VERSION ""

NS_ :

BS_:

BU_: HVESP01 HVESS

BO_ 2499744364 HVESP01_DiagnosticC_8: 8 HVESP01
 SG_ HVESP01_PackVoltageImbalance_8 : 58|2@1+ (1,0) [0|3] ""  HVESP01
 SG_ HVESP01_PrechargeoverCurrent_8 : 56|2@1+ (1,0) [0|3] ""  HVESP01
 SG_ HVESP01_HVILvoltageError_8 : 2|2@1+ (1,0) [0|3] ""  HVESP01
 SG_ HVESP01_HVILcurrentReturnError_8 : 0|2@1+ (1,0) [0|3] ""  HVESP01
 SG_ HVESP01_PosFcContWelded_8 : 14|2@1+ (1,0) [0|3] ""  HVESP01
 SG_ HVESP01_PosFcContStuckOpen_8 : 12|2@1+ (1,0) [0|3] ""  HVESP01
 SG_ HVESP01_NegFcContWelded_8 : 10|2@1+ (1,0) [0|3] ""  HVESP01
 SG_ HVESP01_NegFcContStuckOpen_8 : 8|2@1+ (1,0) [0|3] ""  HVESP01
 SG_ HVESP01_IsolationIntFault_8 : 20|2@1+ (1,0) [0|3] ""  HVESP01
 SG_ HVESP01_IsolationExtFault_8 : 18|2@1+ (1,0) [0|3] ""  HVESP01
 SG_ HVESP01_pcb_error_8 : 16|2@1+ (1,0) [0|3] ""  HVESP01
 SG_ HVESP01_hall_eff_hi_rang_err_8 : 30|2@1+ (1,0) [0|3] ""  HVESP01
 SG_ HVESP01_brick_volt_sns_open_8 : 28|2@1+ (1,0) [0|3] ""  HVESP01
 SG_ HVESP01_5v_error_8 : 26|2@1+ (1,0) [0|3] ""  HVESP01
 SG_ HVESP01_3_3_hot_error_8 : 24|2@1+ (1,0) [0|3] ""  HVESP01
 SG_ HVESP01_12v_input_error_8 : 38|2@1+ (1,0) [0|3] ""  HVESP01
 SG_ HVESP01_1_25v_error_8 : 36|2@1+ (1,0) [0|3] ""  HVESP01
 SG_ HVESP01_shunt_MIA_8 : 34|2@1+ (1,0) [0|3] ""  HVESP01
 SG_ HVESP01_SBC_int_reg_error_8 : 32|2@1+ (1,0) [0|3] ""  HVESP01
 SG_ HVESP01_pos_3_3v_analog_error_8 : 46|2@1+ (1,0) [0|3] ""  HVESP01
 SG_ HVESP01_outlt_clnt_thrm_open_8 : 44|2@1+ (1,0) [0|3] ""  HVESP01
 SG_ HVESP01_neg_3_3_analog_error_8 : 42|2@1+ (1,0) [0|3] ""  HVESP01
 SG_ HVESP01_inlet_clnt_thrm_open_8 : 40|2@1+ (1,0) [0|3] ""  HVESP01
 SG_ HVESP01_hall_eff_lo_rang_err_8 : 54|2@1+ (1,0) [0|3] ""  HVESP01
 SG_ HVESP01_outlt_clnt_thrm_short_8 : 52|2@1+ (1,0) [0|3] ""  HVESP01
 SG_ HVESP01_inlet_clnt_thrm_short_8 : 50|2@1+ (1,0) [0|3] ""  HVESP01
 SG_ HVESP01_3_3v_error_8 : 48|2@1+ (1,0) [0|3] ""  HVESP01

BO_ 2499744613 HVESP01_DiagnosticD_1: 8 HVESP01
 SG_ HVESP01_BusJoinFailed_1 : 10|2@1+ (1,0) [0|3] ""  HVESP01
 SG_ HVESP01_ModuleThermFaultSevere_1 : 8|2@1+ (1,0) [0|3] ""  HVESP01
 SG_ HVESP01_Cal2PackMismatch_1 : 22|2@1+ (1,0) [0|3] ""  HVESP01
 SG_ HVESP01_HardwareUvloError_1 : 20|2@1+ (1,0) [0|3] ""  HVESP01
 SG_ HVESP01_iOverchargemod_1 : 46|2@1+ (1,0) [0|3] ""  HVESP01
 SG_ HVESP01_afe_pwr_wire_open_1 : 44|2@1+ (1,0) [0|3] ""  HVESP01
 SG_ HVESP01_HardwareOVError_1 : 18|2@1+ (1,0) [0|3] ""  HVESP01
 SG_ HVESP01_DoubleDcContWeld_1 : 16|2@1+ (1,0) [0|3] ""  HVESP01
 SG_ HVESP01_CurrentMismatch_1 : 30|2@1+ (1,0) [0|3] ""  HVESP01
 SG_ HVESP01_vBrickImbalanceWar_1 : 28|2@1+ (1,0) [0|3] ""  HVESP01
 SG_ HVESP01_vBrickImbalanceMod_1 : 26|2@1+ (1,0) [0|3] ""  HVESP01
 SG_ HVESP01_vBrickImbalanceSev_1 : 24|2@1+ (1,0) [0|3] ""  HVESP01
 SG_ HVESP01_Placeholder06_1 : 38|2@1+ (1,0) [0|3] ""  HVESP01
 SG_ HVESP01_iOverdischargewar_1 : 36|2@1+ (1,0) [0|3] ""  HVESP01
 SG_ HVESP01_SpeakerMia_1 : 2|2@1+ (1,0) [0|3] ""  HVESP01
 SG_ HVESP01_IsoSpiBreak_1 : 0|2@1+ (1,0) [0|3] ""  HVESP01
 SG_ HVESP01_VersionMismatch_1 : 14|2@1+ (1,0) [0|3] ""  HVESP01
 SG_ HVESP01_SystemPrechargeFail_1 : 12|2@1+ (1,0) [0|3] ""  HVESP01
 SG_ HVESP01_iOverdischargemod_1 : 34|2@1+ (1,0) [0|3] ""  HVESP01
 SG_ HVESP01_iOverchargewar_1 : 32|2@1+ (1,0) [0|3] ""  HVESP01

BO_ 2499744614 HVESP01_DiagnosticD_2: 8 HVESP01
 SG_ HVESP01_BusJoinFailed_2 : 10|2@1+ (1,0) [0|3] ""  HVESP01
 SG_ HVESP01_ModuleThermFaultSevere_2 : 8|2@1+ (1,0) [0|3] ""  HVESP01
 SG_ HVESP01_Cal2PackMismatch_2 : 22|2@1+ (1,0) [0|3] ""  HVESP01
 SG_ HVESP01_HardwareUvloError_2 : 20|2@1+ (1,0) [0|3] ""  HVESP01
 SG_ HVESP01_iOverchargemod_2 : 46|2@1+ (1,0) [0|3] ""  HVESP01
 SG_ HVESP01_afe_pwr_wire_open_2 : 44|2@1+ (1,0) [0|3] ""  HVESP01
 SG_ HVESP01_HardwareOVError_2 : 18|2@1+ (1,0) [0|3] ""  HVESP01
 SG_ HVESP01_DoubleDcContWeld_2 : 16|2@1+ (1,0) [0|3] ""  HVESP01
 SG_ HVESP01_CurrentMismatch_2 : 30|2@1+ (1,0) [0|3] ""  HVESP01
 SG_ HVESP01_vBrickImbalanceWar_2 : 28|2@1+ (1,0) [0|3] ""  HVESP01
 SG_ HVESP01_vBrickImbalanceMod_2 : 26|2@1+ (1,0) [0|3] ""  HVESP01
 SG_ HVESP01_vBrickImbalanceSev_2 : 24|2@1+ (1,0) [0|3] ""  HVESP01
 SG_ HVESP01_Placeholder06_2 : 38|2@1+ (1,0) [0|3] ""  HVESP01
 SG_ HVESP01_iOverdischargewar_2 : 36|2@1+ (1,0) [0|3] ""  HVESP01
 SG_ HVESP01_SpeakerMia_2 : 2|2@1+ (1,0) [0|3] ""  HVESP01
 SG_ HVESP01_IsoSpiBreak_2 : 0|2@1+ (1,0) [0|3] ""  HVESP01
 SG_ HVESP01_VersionMismatch_2 : 14|2@1+ (1,0) [0|3] ""  HVESP01
 SG_ HVESP01_SystemPrechargeFail_2 : 12|2@1+ (1,0) [0|3] ""  HVESP01
 SG_ HVESP01_iOverdischargemod_2 : 34|2@1+ (1,0) [0|3] ""  HVESP01
 SG_ HVESP01_iOverchargewar_2 : 32|2@1+ (1,0) [0|3] ""  HVESP01

BO_ 2499744615 HVESP01_DiagnosticD_3: 8 HVESP01
 SG_ HVESP01_BusJoinFailed_3 : 10|2@1+ (1,0) [0|3] ""  HVESP01
 SG_ HVESP01_ModuleThermFaultSevere_3 : 8|2@1+ (1,0) [0|3] ""  HVESP01
 SG_ HVESP01_Cal2PackMismatch_3 : 22|2@1+ (1,0) [0|3] ""  HVESP01
 SG_ HVESP01_HardwareUvloError_3 : 20|2@1+ (1,0) [0|3] ""  HVESP01
 SG_ HVESP01_iOverchargemod_3 : 46|2@1+ (1,0) [0|3] ""  HVESP01
 SG_ HVESP01_afe_pwr_wire_open_3 : 44|2@1+ (1,0) [0|3] ""  HVESP01
 SG_ HVESP01_HardwareOVError_3 : 18|2@1+ (1,0) [0|3] ""  HVESP01
 SG_ HVESP01_DoubleDcContWeld_3 : 16|2@1+ (1,0) [0|3] ""  HVESP01
 SG_ HVESP01_CurrentMismatch_3 : 30|2@1+ (1,0) [0|3] ""  HVESP01
 SG_ HVESP01_vBrickImbalanceWar_3 : 28|2@1+ (1,0) [0|3] ""  HVESP01
 SG_ HVESP01_vBrickImbalanceMod_3 : 26|2@1+ (1,0) [0|3] ""  HVESP01
 SG_ HVESP01_vBrickImbalanceSev_3 : 24|2@1+ (1,0) [0|3] ""  HVESP01
 SG_ HVESP01_Placeholder06_3 : 38|2@1+ (1,0) [0|3] ""  HVESP01
 SG_ HVESP01_iOverdischargewar_3 : 36|2@1+ (1,0) [0|3] ""  HVESP01
 SG_ HVESP01_SpeakerMia_3 : 2|2@1+ (1,0) [0|3] ""  HVESP01
 SG_ HVESP01_IsoSpiBreak_3 : 0|2@1+ (1,0) [0|3] ""  HVESP01
 SG_ HVESP01_VersionMismatch_3 : 14|2@1+ (1,0) [0|3] ""  HVESP01
 SG_ HVESP01_SystemPrechargeFail_3 : 12|2@1+ (1,0) [0|3] ""  HVESP01
 SG_ HVESP01_iOverdischargemod_3 : 34|2@1+ (1,0) [0|3] ""  HVESP01
 SG_ HVESP01_iOverchargewar_3 : 32|2@1+ (1,0) [0|3] ""  HVESP01

BO_ 2499744616 HVESP01_DiagnosticD_4: 8 HVESP01
 SG_ HVESP01_BusJoinFailed_4 : 10|2@1+ (1,0) [0|3] ""  HVESP01
 SG_ HVESP01_ModuleThermFaultSevere_4 : 8|2@1+ (1,0) [0|3] ""  HVESP01
 SG_ HVESP01_Cal2PackMismatch_4 : 22|2@1+ (1,0) [0|3] ""  HVESP01
 SG_ HVESP01_HardwareUvloError_4 : 20|2@1+ (1,0) [0|3] ""  HVESP01
 SG_ HVESP01_iOverchargemod_4 : 46|2@1+ (1,0) [0|3] ""  HVESP01
 SG_ HVESP01_afe_pwr_wire_open_4 : 44|2@1+ (1,0) [0|3] ""  HVESP01
 SG_ HVESP01_HardwareOVError_4 : 18|2@1+ (1,0) [0|3] ""  HVESP01
 SG_ HVESP01_DoubleDcContWeld_4 : 16|2@1+ (1,0) [0|3] ""  HVESP01
 SG_ HVESP01_CurrentMismatch_4 : 30|2@1+ (1,0) [0|3] ""  HVESP01
 SG_ HVESP01_vBrickImbalanceWar_4 : 28|2@1+ (1,0) [0|3] ""  HVESP01
 SG_ HVESP01_vBrickImbalanceMod_4 : 26|2@1+ (1,0) [0|3] ""  HVESP01
 SG_ HVESP01_vBrickImbalanceSev_4 : 24|2@1+ (1,0) [0|3] ""  HVESP01
 SG_ HVESP01_Placeholder06_4 : 38|2@1+ (1,0) [0|3] ""  HVESP01
 SG_ HVESP01_iOverdischargewar_4 : 36|2@1+ (1,0) [0|3] ""  HVESP01
 SG_ HVESP01_SpeakerMia_4 : 2|2@1+ (1,0) [0|3] ""  HVESP01
 SG_ HVESP01_IsoSpiBreak_4 : 0|2@1+ (1,0) [0|3] ""  HVESP01
 SG_ HVESP01_VersionMismatch_4 : 14|2@1+ (1,0) [0|3] ""  HVESP01
 SG_ HVESP01_SystemPrechargeFail_4 : 12|2@1+ (1,0) [0|3] ""  HVESP01
 SG_ HVESP01_iOverdischargemod_4 : 34|2@1+ (1,0) [0|3] ""  HVESP01
 SG_ HVESP01_iOverchargewar_4 : 32|2@1+ (1,0) [0|3] ""  HVESP01

BO_ 2499744617 HVESP01_DiagnosticD_5: 8 HVESP01
 SG_ HVESP01_BusJoinFailed_5 : 10|2@1+ (1,0) [0|3] ""  HVESP01
 SG_ HVESP01_ModuleThermFaultSevere_5 : 8|2@1+ (1,0) [0|3] ""  HVESP01
 SG_ HVESP01_Cal2PackMismatch_5 : 22|2@1+ (1,0) [0|3] ""  HVESP01
 SG_ HVESP01_HardwareUvloError_5 : 20|2@1+ (1,0) [0|3] ""  HVESP01
 SG_ HVESP01_iOverchargemod_5 : 46|2@1+ (1,0) [0|3] ""  HVESP01
 SG_ HVESP01_afe_pwr_wire_open_5 : 44|2@1+ (1,0) [0|3] ""  HVESP01
 SG_ HVESP01_HardwareOVError_5 : 18|2@1+ (1,0) [0|3] ""  HVESP01
 SG_ HVESP01_DoubleDcContWeld_5 : 16|2@1+ (1,0) [0|3] ""  HVESP01
 SG_ HVESP01_CurrentMismatch_5 : 30|2@1+ (1,0) [0|3] ""  HVESP01
 SG_ HVESP01_vBrickImbalanceWar_5 : 28|2@1+ (1,0) [0|3] ""  HVESP01
 SG_ HVESP01_vBrickImbalanceMod_5 : 26|2@1+ (1,0) [0|3] ""  HVESP01
 SG_ HVESP01_vBrickImbalanceSev_5 : 24|2@1+ (1,0) [0|3] ""  HVESP01
 SG_ HVESP01_Placeholder06_5 : 38|2@1+ (1,0) [0|3] ""  HVESP01
 SG_ HVESP01_iOverdischargewar_5 : 36|2@1+ (1,0) [0|3] ""  HVESP01
 SG_ HVESP01_SpeakerMia_5 : 2|2@1+ (1,0) [0|3] ""  HVESP01
 SG_ HVESP01_IsoSpiBreak_5 : 0|2@1+ (1,0) [0|3] ""  HVESP01
 SG_ HVESP01_VersionMismatch_5 : 14|2@1+ (1,0) [0|3] ""  HVESP01
 SG_ HVESP01_SystemPrechargeFail_5 : 12|2@1+ (1,0) [0|3] ""  HVESP01
 SG_ HVESP01_iOverdischargemod_5 : 34|2@1+ (1,0) [0|3] ""  HVESP01
 SG_ HVESP01_iOverchargewar_5 : 32|2@1+ (1,0) [0|3] ""  HVESP01

BO_ 2499744618 HVESP01_DiagnosticD_6: 8 HVESP01
 SG_ HVESP01_BusJoinFailed_6 : 10|2@1+ (1,0) [0|3] ""  HVESP01
 SG_ HVESP01_ModuleThermFaultSevere_6 : 8|2@1+ (1,0) [0|3] ""  HVESP01
 SG_ HVESP01_Cal2PackMismatch_6 : 22|2@1+ (1,0) [0|3] ""  HVESP01
 SG_ HVESP01_HardwareUvloError_6 : 20|2@1+ (1,0) [0|3] ""  HVESP01
 SG_ HVESP01_iOverchargemod_6 : 46|2@1+ (1,0) [0|3] ""  HVESP01
 SG_ HVESP01_afe_pwr_wire_open_6 : 44|2@1+ (1,0) [0|3] ""  HVESP01
 SG_ HVESP01_HardwareOVError_6 : 18|2@1+ (1,0) [0|3] ""  HVESP01
 SG_ HVESP01_DoubleDcContWeld_6 : 16|2@1+ (1,0) [0|3] ""  HVESP01
 SG_ HVESP01_CurrentMismatch_6 : 30|2@1+ (1,0) [0|3] ""  HVESP01
 SG_ HVESP01_vBrickImbalanceWar_6 : 28|2@1+ (1,0) [0|3] ""  HVESP01
 SG_ HVESP01_vBrickImbalanceMod_6 : 26|2@1+ (1,0) [0|3] ""  HVESP01
 SG_ HVESP01_vBrickImbalanceSev_6 : 24|2@1+ (1,0) [0|3] ""  HVESP01
 SG_ HVESP01_Placeholder06_6 : 38|2@1+ (1,0) [0|3] ""  HVESP01
 SG_ HVESP01_iOverdischargewar_6 : 36|2@1+ (1,0) [0|3] ""  HVESP01
 SG_ HVESP01_SpeakerMia_6 : 2|2@1+ (1,0) [0|3] ""  HVESP01
 SG_ HVESP01_IsoSpiBreak_6 : 0|2@1+ (1,0) [0|3] ""  HVESP01
 SG_ HVESP01_VersionMismatch_6 : 14|2@1+ (1,0) [0|3] ""  HVESP01
 SG_ HVESP01_SystemPrechargeFail_6 : 12|2@1+ (1,0) [0|3] ""  HVESP01
 SG_ HVESP01_iOverdischargemod_6 : 34|2@1+ (1,0) [0|3] ""  HVESP01
 SG_ HVESP01_iOverchargewar_6 : 32|2@1+ (1,0) [0|3] ""  HVESP01

BO_ 2499744619 HVESP01_DiagnosticD_7: 8 HVESP01
 SG_ HVESP01_BusJoinFailed_7 : 10|2@1+ (1,0) [0|3] ""  HVESP01
 SG_ HVESP01_ModuleThermFaultSevere_7 : 8|2@1+ (1,0) [0|3] ""  HVESP01
 SG_ HVESP01_Cal2PackMismatch_7 : 22|2@1+ (1,0) [0|3] ""  HVESP01
 SG_ HVESP01_HardwareUvloError_7 : 20|2@1+ (1,0) [0|3] ""  HVESP01
 SG_ HVESP01_iOverchargemod_7 : 46|2@1+ (1,0) [0|3] ""  HVESP01
 SG_ HVESP01_afe_pwr_wire_open_7 : 44|2@1+ (1,0) [0|3] ""  HVESP01
 SG_ HVESP01_HardwareOVError_7 : 18|2@1+ (1,0) [0|3] ""  HVESP01
 SG_ HVESP01_DoubleDcContWeld_7 : 16|2@1+ (1,0) [0|3] ""  HVESP01
 SG_ HVESP01_CurrentMismatch_7 : 30|2@1+ (1,0) [0|3] ""  HVESP01
 SG_ HVESP01_vBrickImbalanceWar_7 : 28|2@1+ (1,0) [0|3] ""  HVESP01
 SG_ HVESP01_vBrickImbalanceMod_7 : 26|2@1+ (1,0) [0|3] ""  HVESP01
 SG_ HVESP01_vBrickImbalanceSev_7 : 24|2@1+ (1,0) [0|3] ""  HVESP01
 SG_ HVESP01_Placeholder06_7 : 38|2@1+ (1,0) [0|3] ""  HVESP01
 SG_ HVESP01_iOverdischargewar_7 : 36|2@1+ (1,0) [0|3] ""  HVESP01
 SG_ HVESP01_SpeakerMia_7 : 2|2@1+ (1,0) [0|3] ""  HVESP01
 SG_ HVESP01_IsoSpiBreak_7 : 0|2@1+ (1,0) [0|3] ""  HVESP01
 SG_ HVESP01_VersionMismatch_7 : 14|2@1+ (1,0) [0|3] ""  HVESP01
 SG_ HVESP01_SystemPrechargeFail_7 : 12|2@1+ (1,0) [0|3] ""  HVESP01
 SG_ HVESP01_iOverdischargemod_7 : 34|2@1+ (1,0) [0|3] ""  HVESP01
 SG_ HVESP01_iOverchargewar_7 : 32|2@1+ (1,0) [0|3] ""  HVESP01

BO_ 2499744620 HVESP01_DiagnosticD_8: 8 HVESP01
 SG_ HVESP01_BusJoinFailed_8 : 10|2@1+ (1,0) [0|3] ""  HVESP01
 SG_ HVESP01_ModuleThermFaultSevere_8 : 8|2@1+ (1,0) [0|3] ""  HVESP01
 SG_ HVESP01_Cal2PackMismatch_8 : 22|2@1+ (1,0) [0|3] ""  HVESP01
 SG_ HVESP01_HardwareUvloError_8 : 20|2@1+ (1,0) [0|3] ""  HVESP01
 SG_ HVESP01_iOverchargemod_8 : 46|2@1+ (1,0) [0|3] ""  HVESP01
 SG_ HVESP01_afe_pwr_wire_open_8 : 44|2@1+ (1,0) [0|3] ""  HVESP01
 SG_ HVESP01_HardwareOVError_8 : 18|2@1+ (1,0) [0|3] ""  HVESP01
 SG_ HVESP01_DoubleDcContWeld_8 : 16|2@1+ (1,0) [0|3] ""  HVESP01
 SG_ HVESP01_CurrentMismatch_8 : 30|2@1+ (1,0) [0|3] ""  HVESP01
 SG_ HVESP01_vBrickImbalanceWar_8 : 28|2@1+ (1,0) [0|3] ""  HVESP01
 SG_ HVESP01_vBrickImbalanceMod_8 : 26|2@1+ (1,0) [0|3] ""  HVESP01
 SG_ HVESP01_vBrickImbalanceSev_8 : 24|2@1+ (1,0) [0|3] ""  HVESP01
 SG_ HVESP01_Placeholder06_8 : 38|2@1+ (1,0) [0|3] ""  HVESP01
 SG_ HVESP01_iOverdischargewar_8 : 36|2@1+ (1,0) [0|3] ""  HVESP01
 SG_ HVESP01_SpeakerMia_8 : 2|2@1+ (1,0) [0|3] ""  HVESP01
 SG_ HVESP01_IsoSpiBreak_8 : 0|2@1+ (1,0) [0|3] ""  HVESP01
 SG_ HVESP01_VersionMismatch_8 : 14|2@1+ (1,0) [0|3] ""  HVESP01
 SG_ HVESP01_SystemPrechargeFail_8 : 12|2@1+ (1,0) [0|3] ""  HVESP01
 SG_ HVESP01_iOverdischargemod_8 : 34|2@1+ (1,0) [0|3] ""  HVESP01
 SG_ HVESP01_iOverchargewar_8 : 32|2@1+ (1,0) [0|3] ""  HVESP01

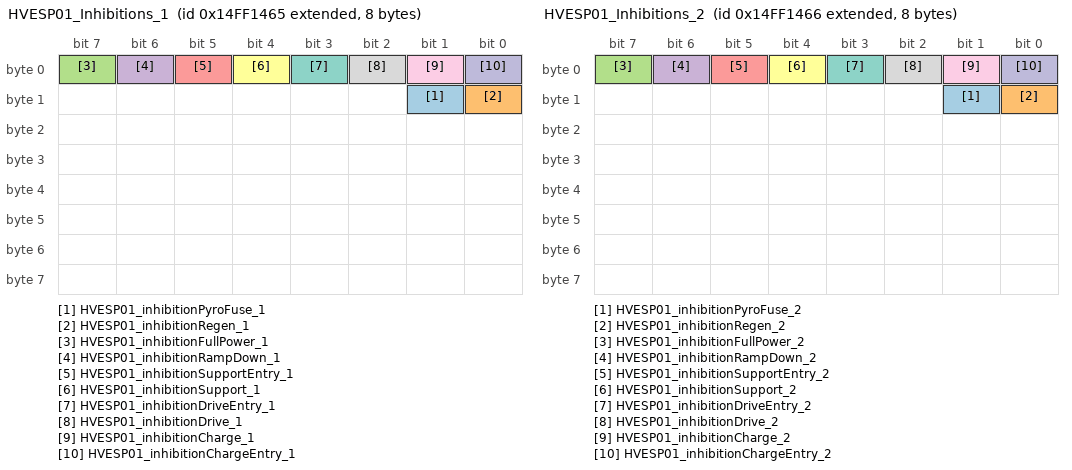
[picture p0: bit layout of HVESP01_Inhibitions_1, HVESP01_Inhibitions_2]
BO_ 2499744869 HVESP01_Inhibitions_1: 8 HVESP01
 SG_ HVESP01_inhibitionPyroFuse_1 : 9|1@1+ (1,0) [0|1] ""  HVESP01
 SG_ HVESP01_inhibitionRegen_1 : 8|1@1+ (1,0) [0|1] ""  HVESP01
 SG_ HVESP01_inhibitionFullPower_1 : 7|1@1+ (1,0) [0|1] ""  HVESP01
 SG_ HVESP01_inhibitionRampDown_1 : 6|1@1+ (1,0) [0|1] ""  HVESP01
 SG_ HVESP01_inhibitionSupportEntry_1 : 5|1@1+ (1,0) [0|1] ""  HVESP01
 SG_ HVESP01_inhibitionSupport_1 : 4|1@1+ (1,0) [0|1] ""  HVESP01
 SG_ HVESP01_inhibitionDriveEntry_1 : 3|1@1+ (1,0) [0|1] ""  HVESP01
 SG_ HVESP01_inhibitionDrive_1 : 2|1@1+ (1,0) [0|1] ""  HVESP01
 SG_ HVESP01_inhibitionCharge_1 : 1|1@1+ (1,0) [0|1] ""  HVESP01
 SG_ HVESP01_inhibitionChargeEntry_1 : 0|1@1+ (1,0) [0|1] ""  HVESP01

BO_ 2499744870 HVESP01_Inhibitions_2: 8 HVESP01
 SG_ HVESP01_inhibitionPyroFuse_2 : 9|1@1+ (1,0) [0|1] ""  HVESP01
 SG_ HVESP01_inhibitionRegen_2 : 8|1@1+ (1,0) [0|1] ""  HVESP01
 SG_ HVESP01_inhibitionFullPower_2 : 7|1@1+ (1,0) [0|1] ""  HVESP01
 SG_ HVESP01_inhibitionRampDown_2 : 6|1@1+ (1,0) [0|1] ""  HVESP01
 SG_ HVESP01_inhibitionSupportEntry_2 : 5|1@1+ (1,0) [0|1] ""  HVESP01
 SG_ HVESP01_inhibitionSupport_2 : 4|1@1+ (1,0) [0|1] ""  HVESP01
 SG_ HVESP01_inhibitionDriveEntry_2 : 3|1@1+ (1,0) [0|1] ""  HVESP01
 SG_ HVESP01_inhibitionDrive_2 : 2|1@1+ (1,0) [0|1] ""  HVESP01
 SG_ HVESP01_inhibitionCharge_2 : 1|1@1+ (1,0) [0|1] ""  HVESP01
 SG_ HVESP01_inhibitionChargeEntry_2 : 0|1@1+ (1,0) [0|1] ""  HVESP01

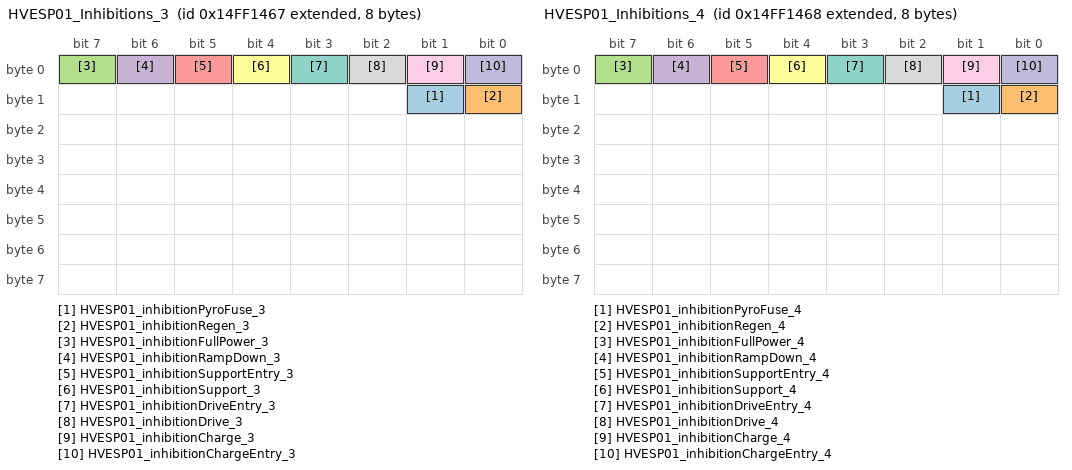
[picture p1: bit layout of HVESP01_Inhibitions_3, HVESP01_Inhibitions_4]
BO_ 2499744871 HVESP01_Inhibitions_3: 8 HVESP01
 SG_ HVESP01_inhibitionPyroFuse_3 : 9|1@1+ (1,0) [0|1] ""  HVESP01
 SG_ HVESP01_inhibitionRegen_3 : 8|1@1+ (1,0) [0|1] ""  HVESP01
 SG_ HVESP01_inhibitionFullPower_3 : 7|1@1+ (1,0) [0|1] ""  HVESP01
 SG_ HVESP01_inhibitionRampDown_3 : 6|1@1+ (1,0) [0|1] ""  HVESP01
 SG_ HVESP01_inhibitionSupportEntry_3 : 5|1@1+ (1,0) [0|1] ""  HVESP01
 SG_ HVESP01_inhibitionSupport_3 : 4|1@1+ (1,0) [0|1] ""  HVESP01
 SG_ HVESP01_inhibitionDriveEntry_3 : 3|1@1+ (1,0) [0|1] ""  HVESP01
 SG_ HVESP01_inhibitionDrive_3 : 2|1@1+ (1,0) [0|1] ""  HVESP01
 SG_ HVESP01_inhibitionCharge_3 : 1|1@1+ (1,0) [0|1] ""  HVESP01
 SG_ HVESP01_inhibitionChargeEntry_3 : 0|1@1+ (1,0) [0|1] ""  HVESP01

BO_ 2499744872 HVESP01_Inhibitions_4: 8 HVESP01
 SG_ HVESP01_inhibitionPyroFuse_4 : 9|1@1+ (1,0) [0|1] ""  HVESP01
 SG_ HVESP01_inhibitionRegen_4 : 8|1@1+ (1,0) [0|1] ""  HVESP01
 SG_ HVESP01_inhibitionFullPower_4 : 7|1@1+ (1,0) [0|1] ""  HVESP01
 SG_ HVESP01_inhibitionRampDown_4 : 6|1@1+ (1,0) [0|1] ""  HVESP01
 SG_ HVESP01_inhibitionSupportEntry_4 : 5|1@1+ (1,0) [0|1] ""  HVESP01
 SG_ HVESP01_inhibitionSupport_4 : 4|1@1+ (1,0) [0|1] ""  HVESP01
 SG_ HVESP01_inhibitionDriveEntry_4 : 3|1@1+ (1,0) [0|1] ""  HVESP01
 SG_ HVESP01_inhibitionDrive_4 : 2|1@1+ (1,0) [0|1] ""  HVESP01
 SG_ HVESP01_inhibitionCharge_4 : 1|1@1+ (1,0) [0|1] ""  HVESP01
 SG_ HVESP01_inhibitionChargeEntry_4 : 0|1@1+ (1,0) [0|1] ""  HVESP01

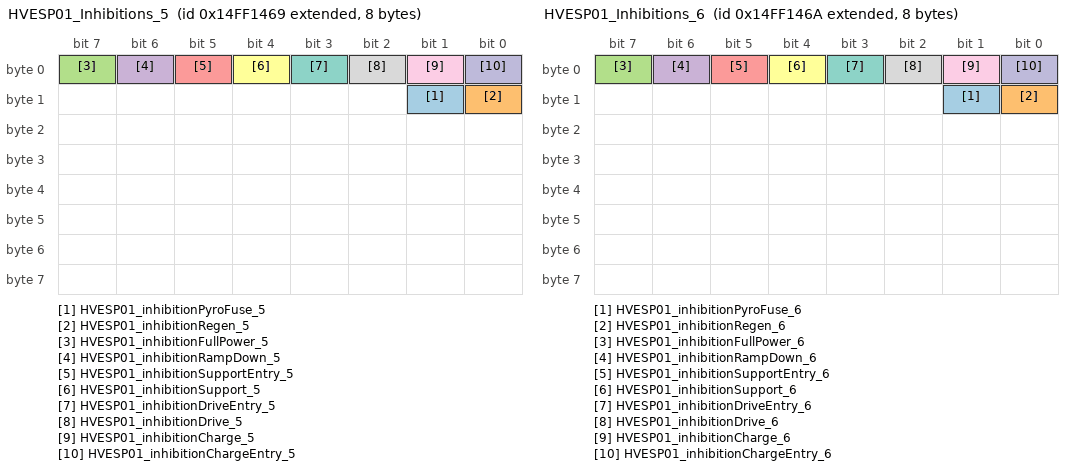
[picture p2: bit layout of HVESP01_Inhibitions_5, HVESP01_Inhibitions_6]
BO_ 2499744873 HVESP01_Inhibitions_5: 8 HVESP01
 SG_ HVESP01_inhibitionPyroFuse_5 : 9|1@1+ (1,0) [0|1] ""  HVESP01
 SG_ HVESP01_inhibitionRegen_5 : 8|1@1+ (1,0) [0|1] ""  HVESP01
 SG_ HVESP01_inhibitionFullPower_5 : 7|1@1+ (1,0) [0|1] ""  HVESP01
 SG_ HVESP01_inhibitionRampDown_5 : 6|1@1+ (1,0) [0|1] ""  HVESP01
 SG_ HVESP01_inhibitionSupportEntry_5 : 5|1@1+ (1,0) [0|1] ""  HVESP01
 SG_ HVESP01_inhibitionSupport_5 : 4|1@1+ (1,0) [0|1] ""  HVESP01
 SG_ HVESP01_inhibitionDriveEntry_5 : 3|1@1+ (1,0) [0|1] ""  HVESP01
 SG_ HVESP01_inhibitionDrive_5 : 2|1@1+ (1,0) [0|1] ""  HVESP01
 SG_ HVESP01_inhibitionCharge_5 : 1|1@1+ (1,0) [0|1] ""  HVESP01
 SG_ HVESP01_inhibitionChargeEntry_5 : 0|1@1+ (1,0) [0|1] ""  HVESP01

BO_ 2499744874 HVESP01_Inhibitions_6: 8 HVESP01
 SG_ HVESP01_inhibitionPyroFuse_6 : 9|1@1+ (1,0) [0|1] ""  HVESP01
 SG_ HVESP01_inhibitionRegen_6 : 8|1@1+ (1,0) [0|1] ""  HVESP01
 SG_ HVESP01_inhibitionFullPower_6 : 7|1@1+ (1,0) [0|1] ""  HVESP01
 SG_ HVESP01_inhibitionRampDown_6 : 6|1@1+ (1,0) [0|1] ""  HVESP01
 SG_ HVESP01_inhibitionSupportEntry_6 : 5|1@1+ (1,0) [0|1] ""  HVESP01
 SG_ HVESP01_inhibitionSupport_6 : 4|1@1+ (1,0) [0|1] ""  HVESP01
 SG_ HVESP01_inhibitionDriveEntry_6 : 3|1@1+ (1,0) [0|1] ""  HVESP01
 SG_ HVESP01_inhibitionDrive_6 : 2|1@1+ (1,0) [0|1] ""  HVESP01
 SG_ HVESP01_inhibitionCharge_6 : 1|1@1+ (1,0) [0|1] ""  HVESP01
 SG_ HVESP01_inhibitionChargeEntry_6 : 0|1@1+ (1,0) [0|1] ""  HVESP01

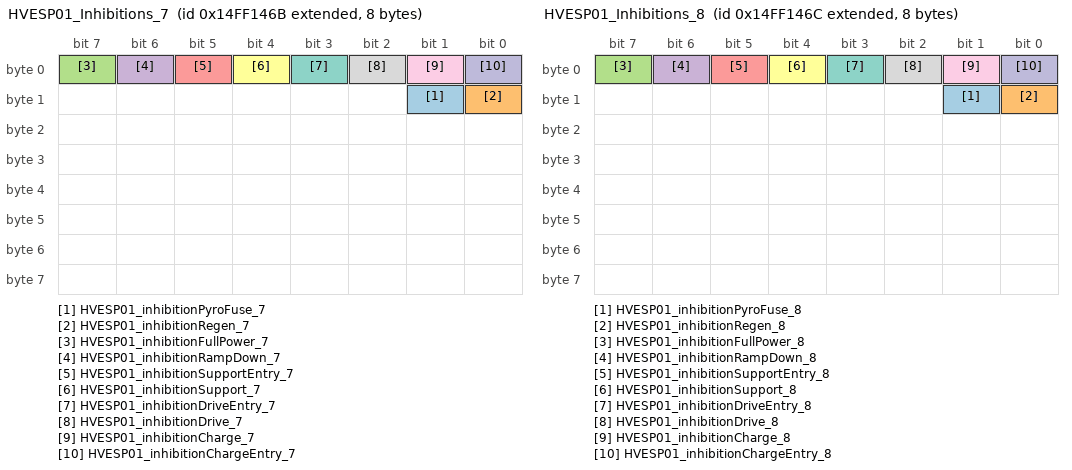
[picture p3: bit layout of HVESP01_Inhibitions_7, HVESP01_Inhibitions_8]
BO_ 2499744875 HVESP01_Inhibitions_7: 8 HVESP01
 SG_ HVESP01_inhibitionPyroFuse_7 : 9|1@1+ (1,0) [0|1] ""  HVESP01
 SG_ HVESP01_inhibitionRegen_7 : 8|1@1+ (1,0) [0|1] ""  HVESP01
 SG_ HVESP01_inhibitionFullPower_7 : 7|1@1+ (1,0) [0|1] ""  HVESP01
 SG_ HVESP01_inhibitionRampDown_7 : 6|1@1+ (1,0) [0|1] ""  HVESP01
 SG_ HVESP01_inhibitionSupportEntry_7 : 5|1@1+ (1,0) [0|1] ""  HVESP01
 SG_ HVESP01_inhibitionSupport_7 : 4|1@1+ (1,0) [0|1] ""  HVESP01
 SG_ HVESP01_inhibitionDriveEntry_7 : 3|1@1+ (1,0) [0|1] ""  HVESP01
 SG_ HVESP01_inhibitionDrive_7 : 2|1@1+ (1,0) [0|1] ""  HVESP01
 SG_ HVESP01_inhibitionCharge_7 : 1|1@1+ (1,0) [0|1] ""  HVESP01
 SG_ HVESP01_inhibitionChargeEntry_7 : 0|1@1+ (1,0) [0|1] ""  HVESP01

BO_ 2499744876 HVESP01_Inhibitions_8: 8 HVESP01
 SG_ HVESP01_inhibitionPyroFuse_8 : 9|1@1+ (1,0) [0|1] ""  HVESP01
 SG_ HVESP01_inhibitionRegen_8 : 8|1@1+ (1,0) [0|1] ""  HVESP01
 SG_ HVESP01_inhibitionFullPower_8 : 7|1@1+ (1,0) [0|1] ""  HVESP01
 SG_ HVESP01_inhibitionRampDown_8 : 6|1@1+ (1,0) [0|1] ""  HVESP01
 SG_ HVESP01_inhibitionSupportEntry_8 : 5|1@1+ (1,0) [0|1] ""  HVESP01
 SG_ HVESP01_inhibitionSupport_8 : 4|1@1+ (1,0) [0|1] ""  HVESP01
 SG_ HVESP01_inhibitionDriveEntry_8 : 3|1@1+ (1,0) [0|1] ""  HVESP01
 SG_ HVESP01_inhibitionDrive_8 : 2|1@1+ (1,0) [0|1] ""  HVESP01
 SG_ HVESP01_inhibitionCharge_8 : 1|1@1+ (1,0) [0|1] ""  HVESP01
 SG_ HVESP01_inhibitionChargeEntry_8 : 0|1@1+ (1,0) [0|1] ""  HVESP01

BO_ 2499745125 HVESP01_DiagnosticPrevA_1: 8 HVESP01
 SG_ HVESP01_vBrickOverSev_1 : 2|2@1+ (1,0) [0|3] ""  HVESP01
 SG_ HVESP01_vBrickOverMod_1 : 0|2@1+ (1,0) [0|3] ""  HVESP01
 SG_ HVESP01_vBrickOverWar_1 : 14|2@1+ (1,0) [0|3] ""  HVESP01
 SG_ HVESP01_HVESP01Quiet_1 : 12|2@1+ (1,0) [0|3] ""  HVESP01
 SG_ HVESP01_vBrickUnderMod_1 : 10|2@1+ (1,0) [0|3] ""  HVESP01
 SG_ HVESP01_vBrickUnderWar_1 : 8|2@1+ (1,0) [0|3] ""  HVESP01
 SG_ HVESP01_TempModuleOverSev_1 : 22|2@1+ (1,0) [0|3] ""  HVESP01
 SG_ HVESP01_TempModuleOverMod_1 : 20|2@1+ (1,0) [0|3] ""  HVESP01
 SG_ HVESP01_TempModuleOverWar_1 : 18|2@1+ (1,0) [0|3] ""  HVESP01
 SG_ HVESP01_TempModuleUnderSev_1 : 16|2@1+ (1,0) [0|3] ""  HVESP01
 SG_ HVESP01_TempModuleUnderMod_1 : 30|2@1+ (1,0) [0|3] ""  HVESP01
 SG_ HVESP01_TempModuleUnderWar_1 : 28|2@1+ (1,0) [0|3] ""  HVESP01
 SG_ HVESP01_iOverchargesev_1 : 26|2@1+ (1,0) [0|3] ""  HVESP01
 SG_ HVESP01_iOverdischargesev_1 : 24|2@1+ (1,0) [0|3] ""  HVESP01
 SG_ HVESP01_iOverHardware_1 : 38|2@1+ (1,0) [0|3] ""  HVESP01
 SG_ HVESP01_PosDcContStuckOpen_1 : 36|2@1+ (1,0) [0|3] ""  HVESP01
 SG_ HVESP01_PosDcContWelded_1 : 34|2@1+ (1,0) [0|3] ""  HVESP01
 SG_ HVESP01_NegDcContStuckOpen_1 : 32|2@1+ (1,0) [0|3] ""  HVESP01
 SG_ HVESP01_NegDcContWelded_1 : 46|2@1+ (1,0) [0|3] ""  HVESP01
 SG_ HVESP01_PrechgTooFast_1 : 44|2@1+ (1,0) [0|3] ""  HVESP01
 SG_ HVESP01_PrechgContWelded_1 : 42|2@1+ (1,0) [0|3] ""  HVESP01
 SG_ HVESP01_PrechgTimeout_1 : 40|2@1+ (1,0) [0|3] ""  HVESP01
 SG_ HVESP01_PrechgContStuckOpen_1 : 54|2@1+ (1,0) [0|3] ""  HVESP01
 SG_ HVESP01_ModuleImbalance_1 : 52|2@1+ (1,0) [0|3] ""  HVESP01
 SG_ HVESP01_ModuleMIA_1 : 50|2@1+ (1,0) [0|3] ""  HVESP01
 SG_ HVESP01_SensePackVoltError_1 : 48|2@1+ (1,0) [0|3] ""  HVESP01
 SG_ HVESP01_SenseLoadVoltError_1 : 62|2@1+ (1,0) [0|3] ""  HVESP01
 SG_ HVESP01_SenseShuntError_1 : 60|2@1+ (1,0) [0|3] ""  HVESP01
 SG_ HVESP01_SenseFcVoltErrorr_1 : 58|2@1+ (1,0) [0|3] ""  HVESP01
 SG_ HVESP01_Placeholder14_1 : 56|2@1+ (1,0) [0|3] ""  HVESP01

BO_ 2499745126 HVESP01_DiagnosticPrevA_2: 8 HVESP01
 SG_ HVESP01_vBrickOverSev_2 : 2|2@1+ (1,0) [0|3] ""  HVESP01
 SG_ HVESP01_vBrickOverMod_2 : 0|2@1+ (1,0) [0|3] ""  HVESP01
 SG_ HVESP01_vBrickOverWar_2 : 14|2@1+ (1,0) [0|3] ""  HVESP01
 SG_ HVESP01_HVESP01Quiet_2 : 12|2@1+ (1,0) [0|3] ""  HVESP01
 SG_ HVESP01_vBrickUnderMod_2 : 10|2@1+ (1,0) [0|3] ""  HVESP01
 SG_ HVESP01_vBrickUnderWar_2 : 8|2@1+ (1,0) [0|3] ""  HVESP01
 SG_ HVESP01_TempModuleOverSev_2 : 22|2@1+ (1,0) [0|3] ""  HVESP01
 SG_ HVESP01_TempModuleOverMod_2 : 20|2@1+ (1,0) [0|3] ""  HVESP01
 SG_ HVESP01_TempModuleOverWar_2 : 18|2@1+ (1,0) [0|3] ""  HVESP01
 SG_ HVESP01_TempModuleUnderSev_2 : 16|2@1+ (1,0) [0|3] ""  HVESP01
 SG_ HVESP01_TempModuleUnderMod_2 : 30|2@1+ (1,0) [0|3] ""  HVESP01
 SG_ HVESP01_TempModuleUnderWar_2 : 28|2@1+ (1,0) [0|3] ""  HVESP01
 SG_ HVESP01_iOverchargesev_2 : 26|2@1+ (1,0) [0|3] ""  HVESP01
 SG_ HVESP01_iOverdischargesev_2 : 24|2@1+ (1,0) [0|3] ""  HVESP01
 SG_ HVESP01_iOverHardware_2 : 38|2@1+ (1,0) [0|3] ""  HVESP01
 SG_ HVESP01_PosDcContStuckOpen_2 : 36|2@1+ (1,0) [0|3] ""  HVESP01
 SG_ HVESP01_PosDcContWelded_2 : 34|2@1+ (1,0) [0|3] ""  HVESP01
 SG_ HVESP01_NegDcContStuckOpen_2 : 32|2@1+ (1,0) [0|3] ""  HVESP01
 SG_ HVESP01_NegDcContWelded_2 : 46|2@1+ (1,0) [0|3] ""  HVESP01
 SG_ HVESP01_PrechgTooFast_2 : 44|2@1+ (1,0) [0|3] ""  HVESP01
 SG_ HVESP01_PrechgContWelded_2 : 42|2@1+ (1,0) [0|3] ""  HVESP01
 SG_ HVESP01_PrechgTimeout_2 : 40|2@1+ (1,0) [0|3] ""  HVESP01
 SG_ HVESP01_PrechgContStuckOpen_2 : 54|2@1+ (1,0) [0|3] ""  HVESP01
 SG_ HVESP01_ModuleImbalance_2 : 52|2@1+ (1,0) [0|3] ""  HVESP01
 SG_ HVESP01_ModuleMIA_2 : 50|2@1+ (1,0) [0|3] ""  HVESP01
 SG_ HVESP01_SensePackVoltError_2 : 48|2@1+ (1,0) [0|3] ""  HVESP01
 SG_ HVESP01_SenseLoadVoltError_2 : 62|2@1+ (1,0) [0|3] ""  HVESP01
 SG_ HVESP01_SenseShuntError_2 : 60|2@1+ (1,0) [0|3] ""  HVESP01
 SG_ HVESP01_SenseFcVoltErrorr_2 : 58|2@1+ (1,0) [0|3] ""  HVESP01
 SG_ HVESP01_Placeholder14_2 : 56|2@1+ (1,0) [0|3] ""  HVESP01

BO_ 2499745127 HVESP01_DiagnosticPrevA_3: 8 HVESP01
 SG_ HVESP01_vBrickOverSev_3 : 2|2@1+ (1,0) [0|3] ""  HVESP01
 SG_ HVESP01_vBrickOverMod_3 : 0|2@1+ (1,0) [0|3] ""  HVESP01
 SG_ HVESP01_vBrickOverWar_3 : 14|2@1+ (1,0) [0|3] ""  HVESP01
 SG_ HVESP01_HVESP01Quiet_3 : 12|2@1+ (1,0) [0|3] ""  HVESP01
 SG_ HVESP01_vBrickUnderMod_3 : 10|2@1+ (1,0) [0|3] ""  HVESP01
 SG_ HVESP01_vBrickUnderWar_3 : 8|2@1+ (1,0) [0|3] ""  HVESP01
 SG_ HVESP01_TempModuleOverSev_3 : 22|2@1+ (1,0) [0|3] ""  HVESP01
 SG_ HVESP01_TempModuleOverMod_3 : 20|2@1+ (1,0) [0|3] ""  HVESP01
 SG_ HVESP01_TempModuleOverWar_3 : 18|2@1+ (1,0) [0|3] ""  HVESP01
 SG_ HVESP01_TempModuleUnderSev_3 : 16|2@1+ (1,0) [0|3] ""  HVESP01
 SG_ HVESP01_TempModuleUnderMod_3 : 30|2@1+ (1,0) [0|3] ""  HVESP01
 SG_ HVESP01_TempModuleUnderWar_3 : 28|2@1+ (1,0) [0|3] ""  HVESP01
 SG_ HVESP01_iOverchargesev_3 : 26|2@1+ (1,0) [0|3] ""  HVESP01
 SG_ HVESP01_iOverdischargesev_3 : 24|2@1+ (1,0) [0|3] ""  HVESP01
 SG_ HVESP01_iOverHardware_3 : 38|2@1+ (1,0) [0|3] ""  HVESP01
 SG_ HVESP01_PosDcContStuckOpen_3 : 36|2@1+ (1,0) [0|3] ""  HVESP01
 SG_ HVESP01_PosDcContWelded_3 : 34|2@1+ (1,0) [0|3] ""  HVESP01
 SG_ HVESP01_NegDcContStuckOpen_3 : 32|2@1+ (1,0) [0|3] ""  HVESP01
 SG_ HVESP01_NegDcContWelded_3 : 46|2@1+ (1,0) [0|3] ""  HVESP01
 SG_ HVESP01_PrechgTooFast_3 : 44|2@1+ (1,0) [0|3] ""  HVESP01
 SG_ HVESP01_PrechgContWelded_3 : 42|2@1+ (1,0) [0|3] ""  HVESP01
 SG_ HVESP01_PrechgTimeout_3 : 40|2@1+ (1,0) [0|3] ""  HVESP01
 SG_ HVESP01_PrechgContStuckOpen_3 : 54|2@1+ (1,0) [0|3] ""  HVESP01
 SG_ HVESP01_ModuleImbalance_3 : 52|2@1+ (1,0) [0|3] ""  HVESP01
 SG_ HVESP01_ModuleMIA_3 : 50|2@1+ (1,0) [0|3] ""  HVESP01
 SG_ HVESP01_SensePackVoltError_3 : 48|2@1+ (1,0) [0|3] ""  HVESP01
 SG_ HVESP01_SenseLoadVoltError_3 : 62|2@1+ (1,0) [0|3] ""  HVESP01
 SG_ HVESP01_SenseShuntError_3 : 60|2@1+ (1,0) [0|3] ""  HVESP01
 SG_ HVESP01_SenseFcVoltErrorr_3 : 58|2@1+ (1,0) [0|3] ""  HVESP01
 SG_ HVESP01_Placeholder14_3 : 56|2@1+ (1,0) [0|3] ""  HVESP01

BO_ 2499745128 HVESP01_DiagnosticPrevA_4: 8 HVESP01
 SG_ HVESP01_vBrickOverSev_4 : 2|2@1+ (1,0) [0|3] ""  HVESP01
 SG_ HVESP01_vBrickOverMod_4 : 0|2@1+ (1,0) [0|3] ""  HVESP01
 SG_ HVESP01_vBrickOverWar_4 : 14|2@1+ (1,0) [0|3] ""  HVESP01
 SG_ HVESP01_HVESP01Quiet_4 : 12|2@1+ (1,0) [0|3] ""  HVESP01
 SG_ HVESP01_vBrickUnderMod_4 : 10|2@1+ (1,0) [0|3] ""  HVESP01
 SG_ HVESP01_vBrickUnderWar_4 : 8|2@1+ (1,0) [0|3] ""  HVESP01
 SG_ HVESP01_TempModuleOverSev_4 : 22|2@1+ (1,0) [0|3] ""  HVESP01
 SG_ HVESP01_TempModuleOverMod_4 : 20|2@1+ (1,0) [0|3] ""  HVESP01
 SG_ HVESP01_TempModuleOverWar_4 : 18|2@1+ (1,0) [0|3] ""  HVESP01
 SG_ HVESP01_TempModuleUnderSev_4 : 16|2@1+ (1,0) [0|3] ""  HVESP01
 SG_ HVESP01_TempModuleUnderMod_4 : 30|2@1+ (1,0) [0|3] ""  HVESP01
 SG_ HVESP01_TempModuleUnderWar_4 : 28|2@1+ (1,0) [0|3] ""  HVESP01
 SG_ HVESP01_iOverchargesev_4 : 26|2@1+ (1,0) [0|3] ""  HVESP01
 SG_ HVESP01_iOverdischargesev_4 : 24|2@1+ (1,0) [0|3] ""  HVESP01
 SG_ HVESP01_iOverHardware_4 : 38|2@1+ (1,0) [0|3] ""  HVESP01
 SG_ HVESP01_PosDcContStuckOpen_4 : 36|2@1+ (1,0) [0|3] ""  HVESP01
 SG_ HVESP01_PosDcContWelded_4 : 34|2@1+ (1,0) [0|3] ""  HVESP01
 SG_ HVESP01_NegDcContStuckOpen_4 : 32|2@1+ (1,0) [0|3] ""  HVESP01
 SG_ HVESP01_NegDcContWelded_4 : 46|2@1+ (1,0) [0|3] ""  HVESP01
 SG_ HVESP01_PrechgTooFast_4 : 44|2@1+ (1,0) [0|3] ""  HVESP01
 SG_ HVESP01_PrechgContWelded_4 : 42|2@1+ (1,0) [0|3] ""  HVESP01
 SG_ HVESP01_PrechgTimeout_4 : 40|2@1+ (1,0) [0|3] ""  HVESP01
 SG_ HVESP01_PrechgContStuckOpen_4 : 54|2@1+ (1,0) [0|3] ""  HVESP01
 SG_ HVESP01_ModuleImbalance_4 : 52|2@1+ (1,0) [0|3] ""  HVESP01
 SG_ HVESP01_ModuleMIA_4 : 50|2@1+ (1,0) [0|3] ""  HVESP01
 SG_ HVESP01_SensePackVoltError_4 : 48|2@1+ (1,0) [0|3] ""  HVESP01
 SG_ HVESP01_SenseLoadVoltError_4 : 62|2@1+ (1,0) [0|3] ""  HVESP01
 SG_ HVESP01_SenseShuntError_4 : 60|2@1+ (1,0) [0|3] ""  HVESP01
 SG_ HVESP01_SenseFcVoltErrorr_4 : 58|2@1+ (1,0) [0|3] ""  HVESP01
 SG_ HVESP01_Placeholder14_4 : 56|2@1+ (1,0) [0|3] ""  HVESP01

BO_ 2499745129 HVESP01_DiagnosticPrevA_5: 8 HVESP01
 SG_ HVESP01_vBrickOverSev_5 : 2|2@1+ (1,0) [0|3] ""  HVESP01
 SG_ HVESP01_vBrickOverMod_5 : 0|2@1+ (1,0) [0|3] ""  HVESP01
 SG_ HVESP01_vBrickOverWar_5 : 14|2@1+ (1,0) [0|3] ""  HVESP01
 SG_ HVESP01_HVESP01Quiet_5 : 12|2@1+ (1,0) [0|3] ""  HVESP01
 SG_ HVESP01_vBrickUnderMod_5 : 10|2@1+ (1,0) [0|3] ""  HVESP01
 SG_ HVESP01_vBrickUnderWar_5 : 8|2@1+ (1,0) [0|3] ""  HVESP01
 SG_ HVESP01_TempModuleOverSev_5 : 22|2@1+ (1,0) [0|3] ""  HVESP01
 SG_ HVESP01_TempModuleOverMod_5 : 20|2@1+ (1,0) [0|3] ""  HVESP01
 SG_ HVESP01_TempModuleOverWar_5 : 18|2@1+ (1,0) [0|3] ""  HVESP01
 SG_ HVESP01_TempModuleUnderSev_5 : 16|2@1+ (1,0) [0|3] ""  HVESP01
 SG_ HVESP01_TempModuleUnderMod_5 : 30|2@1+ (1,0) [0|3] ""  HVESP01
 SG_ HVESP01_TempModuleUnderWar_5 : 28|2@1+ (1,0) [0|3] ""  HVESP01
 SG_ HVESP01_iOverchargesev_5 : 26|2@1+ (1,0) [0|3] ""  HVESP01
 SG_ HVESP01_iOverdischargesev_5 : 24|2@1+ (1,0) [0|3] ""  HVESP01
 SG_ HVESP01_iOverHardware_5 : 38|2@1+ (1,0) [0|3] ""  HVESP01
 SG_ HVESP01_PosDcContStuckOpen_5 : 36|2@1+ (1,0) [0|3] ""  HVESP01
 SG_ HVESP01_PosDcContWelded_5 : 34|2@1+ (1,0) [0|3] ""  HVESP01
 SG_ HVESP01_NegDcContStuckOpen_5 : 32|2@1+ (1,0) [0|3] ""  HVESP01
 SG_ HVESP01_NegDcContWelded_5 : 46|2@1+ (1,0) [0|3] ""  HVESP01
 SG_ HVESP01_PrechgTooFast_5 : 44|2@1+ (1,0) [0|3] ""  HVESP01
 SG_ HVESP01_PrechgContWelded_5 : 42|2@1+ (1,0) [0|3] ""  HVESP01
 SG_ HVESP01_PrechgTimeout_5 : 40|2@1+ (1,0) [0|3] ""  HVESP01
 SG_ HVESP01_PrechgContStuckOpen_5 : 54|2@1+ (1,0) [0|3] ""  HVESP01
 SG_ HVESP01_ModuleImbalance_5 : 52|2@1+ (1,0) [0|3] ""  HVESP01
 SG_ HVESP01_ModuleMIA_5 : 50|2@1+ (1,0) [0|3] ""  HVESP01
 SG_ HVESP01_SensePackVoltError_5 : 48|2@1+ (1,0) [0|3] ""  HVESP01
 SG_ HVESP01_SenseLoadVoltError_5 : 62|2@1+ (1,0) [0|3] ""  HVESP01
 SG_ HVESP01_SenseShuntError_5 : 60|2@1+ (1,0) [0|3] ""  HVESP01
 SG_ HVESP01_SenseFcVoltErrorr_5 : 58|2@1+ (1,0) [0|3] ""  HVESP01
 SG_ HVESP01_Placeholder14_5 : 56|2@1+ (1,0) [0|3] ""  HVESP01

BO_ 2499745130 HVESP01_DiagnosticPrevA_6: 8 HVESP01
 SG_ HVESP01_vBrickOverSev_6 : 2|2@1+ (1,0) [0|3] ""  HVESP01
 SG_ HVESP01_vBrickOverMod_6 : 0|2@1+ (1,0) [0|3] ""  HVESP01
 SG_ HVESP01_vBrickOverWar_6 : 14|2@1+ (1,0) [0|3] ""  HVESP01
 SG_ HVESP01_HVESP01Quiet_6 : 12|2@1+ (1,0) [0|3] ""  HVESP01
 SG_ HVESP01_vBrickUnderMod_6 : 10|2@1+ (1,0) [0|3] ""  HVESP01
 SG_ HVESP01_vBrickUnderWar_6 : 8|2@1+ (1,0) [0|3] ""  HVESP01
 SG_ HVESP01_TempModuleOverSev_6 : 22|2@1+ (1,0) [0|3] ""  HVESP01
 SG_ HVESP01_TempModuleOverMod_6 : 20|2@1+ (1,0) [0|3] ""  HVESP01
 SG_ HVESP01_TempModuleOverWar_6 : 18|2@1+ (1,0) [0|3] ""  HVESP01
 SG_ HVESP01_TempModuleUnderSev_6 : 16|2@1+ (1,0) [0|3] ""  HVESP01
 SG_ HVESP01_TempModuleUnderMod_6 : 30|2@1+ (1,0) [0|3] ""  HVESP01
 SG_ HVESP01_TempModuleUnderWar_6 : 28|2@1+ (1,0) [0|3] ""  HVESP01
 SG_ HVESP01_iOverchargesev_6 : 26|2@1+ (1,0) [0|3] ""  HVESP01
 SG_ HVESP01_iOverdischargesev_6 : 24|2@1+ (1,0) [0|3] ""  HVESP01
 SG_ HVESP01_iOverHardware_6 : 38|2@1+ (1,0) [0|3] ""  HVESP01
 SG_ HVESP01_PosDcContStuckOpen_6 : 36|2@1+ (1,0) [0|3] ""  HVESP01
 SG_ HVESP01_PosDcContWelded_6 : 34|2@1+ (1,0) [0|3] ""  HVESP01
 SG_ HVESP01_NegDcContStuckOpen_6 : 32|2@1+ (1,0) [0|3] ""  HVESP01
 SG_ HVESP01_NegDcContWelded_6 : 46|2@1+ (1,0) [0|3] ""  HVESP01
 SG_ HVESP01_PrechgTooFast_6 : 44|2@1+ (1,0) [0|3] ""  HVESP01
 SG_ HVESP01_PrechgContWelded_6 : 42|2@1+ (1,0) [0|3] ""  HVESP01
 SG_ HVESP01_PrechgTimeout_6 : 40|2@1+ (1,0) [0|3] ""  HVESP01
 SG_ HVESP01_PrechgContStuckOpen_6 : 54|2@1+ (1,0) [0|3] ""  HVESP01
 SG_ HVESP01_ModuleImbalance_6 : 52|2@1+ (1,0) [0|3] ""  HVESP01
 SG_ HVESP01_ModuleMIA_6 : 50|2@1+ (1,0) [0|3] ""  HVESP01
 SG_ HVESP01_SensePackVoltError_6 : 48|2@1+ (1,0) [0|3] ""  HVESP01
 SG_ HVESP01_SenseLoadVoltError_6 : 62|2@1+ (1,0) [0|3] ""  HVESP01
 SG_ HVESP01_SenseShuntError_6 : 60|2@1+ (1,0) [0|3] ""  HVESP01
 SG_ HVESP01_SenseFcVoltErrorr_6 : 58|2@1+ (1,0) [0|3] ""  HVESP01
 SG_ HVESP01_Placeholder14_6 : 56|2@1+ (1,0) [0|3] ""  HVESP01

BO_ 2499745131 HVESP01_DiagnosticPrevA_7: 8 HVESP01
 SG_ HVESP01_vBrickOverSev_7 : 2|2@1+ (1,0) [0|3] ""  HVESP01
 SG_ HVESP01_vBrickOverMod_7 : 0|2@1+ (1,0) [0|3] ""  HVESP01
 SG_ HVESP01_vBrickOverWar_7 : 14|2@1+ (1,0) [0|3] ""  HVESP01
 SG_ HVESP01_HVESP01Quiet_7 : 12|2@1+ (1,0) [0|3] ""  HVESP01
 SG_ HVESP01_vBrickUnderMod_7 : 10|2@1+ (1,0) [0|3] ""  HVESP01
 SG_ HVESP01_vBrickUnderWar_7 : 8|2@1+ (1,0) [0|3] ""  HVESP01
 SG_ HVESP01_TempModuleOverSev_7 : 22|2@1+ (1,0) [0|3] ""  HVESP01
 SG_ HVESP01_TempModuleOverMod_7 : 20|2@1+ (1,0) [0|3] ""  HVESP01
 SG_ HVESP01_TempModuleOverWar_7 : 18|2@1+ (1,0) [0|3] ""  HVESP01
 SG_ HVESP01_TempModuleUnderSev_7 : 16|2@1+ (1,0) [0|3] ""  HVESP01
 SG_ HVESP01_TempModuleUnderMod_7 : 30|2@1+ (1,0) [0|3] ""  HVESP01
 SG_ HVESP01_TempModuleUnderWar_7 : 28|2@1+ (1,0) [0|3] ""  HVESP01
 SG_ HVESP01_iOverchargesev_7 : 26|2@1+ (1,0) [0|3] ""  HVESP01
 SG_ HVESP01_iOverdischargesev_7 : 24|2@1+ (1,0) [0|3] ""  HVESP01
 SG_ HVESP01_iOverHardware_7 : 38|2@1+ (1,0) [0|3] ""  HVESP01
 SG_ HVESP01_PosDcContStuckOpen_7 : 36|2@1+ (1,0) [0|3] ""  HVESP01
 SG_ HVESP01_PosDcContWelded_7 : 34|2@1+ (1,0) [0|3] ""  HVESP01
 SG_ HVESP01_NegDcContStuckOpen_7 : 32|2@1+ (1,0) [0|3] ""  HVESP01
 SG_ HVESP01_NegDcContWelded_7 : 46|2@1+ (1,0) [0|3] ""  HVESP01
 SG_ HVESP01_PrechgTooFast_7 : 44|2@1+ (1,0) [0|3] ""  HVESP01
 SG_ HVESP01_PrechgContWelded_7 : 42|2@1+ (1,0) [0|3] ""  HVESP01
 SG_ HVESP01_PrechgTimeout_7 : 40|2@1+ (1,0) [0|3] ""  HVESP01
 SG_ HVESP01_PrechgContStuckOpen_7 : 54|2@1+ (1,0) [0|3] ""  HVESP01
 SG_ HVESP01_ModuleImbalance_7 : 52|2@1+ (1,0) [0|3] ""  HVESP01
 SG_ HVESP01_ModuleMIA_7 : 50|2@1+ (1,0) [0|3] ""  HVESP01
 SG_ HVESP01_SensePackVoltError_7 : 48|2@1+ (1,0) [0|3] ""  HVESP01
 SG_ HVESP01_SenseLoadVoltError_7 : 62|2@1+ (1,0) [0|3] ""  HVESP01
 SG_ HVESP01_SenseShuntError_7 : 60|2@1+ (1,0) [0|3] ""  HVESP01
 SG_ HVESP01_SenseFcVoltErrorr_7 : 58|2@1+ (1,0) [0|3] ""  HVESP01
 SG_ HVESP01_Placeholder14_7 : 56|2@1+ (1,0) [0|3] ""  HVESP01

BO_ 2499745132 HVESP01_DiagnosticPrevA_8: 8 HVESP01
 SG_ HVESP01_vBrickOverSev_8 : 2|2@1+ (1,0) [0|3] ""  HVESP01
 SG_ HVESP01_vBrickOverMod_8 : 0|2@1+ (1,0) [0|3] ""  HVESP01
 SG_ HVESP01_vBrickOverWar_8 : 14|2@1+ (1,0) [0|3] ""  HVESP01
 SG_ HVESP01_HVESP01Quiet_8 : 12|2@1+ (1,0) [0|3] ""  HVESP01
 SG_ HVESP01_vBrickUnderMod_8 : 10|2@1+ (1,0) [0|3] ""  HVESP01
 SG_ HVESP01_vBrickUnderWar_8 : 8|2@1+ (1,0) [0|3] ""  HVESP01
 SG_ HVESP01_TempModuleOverSev_8 : 22|2@1+ (1,0) [0|3] ""  HVESP01
 SG_ HVESP01_TempModuleOverMod_8 : 20|2@1+ (1,0) [0|3] ""  HVESP01
 SG_ HVESP01_TempModuleOverWar_8 : 18|2@1+ (1,0) [0|3] ""  HVESP01
 SG_ HVESP01_TempModuleUnderSev_8 : 16|2@1+ (1,0) [0|3] ""  HVESP01
 SG_ HVESP01_TempModuleUnderMod_8 : 30|2@1+ (1,0) [0|3] ""  HVESP01
 SG_ HVESP01_TempModuleUnderWar_8 : 28|2@1+ (1,0) [0|3] ""  HVESP01
 SG_ HVESP01_iOverchargesev_8 : 26|2@1+ (1,0) [0|3] ""  HVESP01
 SG_ HVESP01_iOverdischargesev_8 : 24|2@1+ (1,0) [0|3] ""  HVESP01
 SG_ HVESP01_iOverHardware_8 : 38|2@1+ (1,0) [0|3] ""  HVESP01
 SG_ HVESP01_PosDcContStuckOpen_8 : 36|2@1+ (1,0) [0|3] ""  HVESP01
 SG_ HVESP01_PosDcContWelded_8 : 34|2@1+ (1,0) [0|3] ""  HVESP01
 SG_ HVESP01_NegDcContStuckOpen_8 : 32|2@1+ (1,0) [0|3] ""  HVESP01
 SG_ HVESP01_NegDcContWelded_8 : 46|2@1+ (1,0) [0|3] ""  HVESP01
 SG_ HVESP01_PrechgTooFast_8 : 44|2@1+ (1,0) [0|3] ""  HVESP01
 SG_ HVESP01_PrechgContWelded_8 : 42|2@1+ (1,0) [0|3] ""  HVESP01
 SG_ HVESP01_PrechgTimeout_8 : 40|2@1+ (1,0) [0|3] ""  HVESP01
 SG_ HVESP01_PrechgContStuckOpen_8 : 54|2@1+ (1,0) [0|3] ""  HVESP01
 SG_ HVESP01_ModuleImbalance_8 : 52|2@1+ (1,0) [0|3] ""  HVESP01
 SG_ HVESP01_ModuleMIA_8 : 50|2@1+ (1,0) [0|3] ""  HVESP01
 SG_ HVESP01_SensePackVoltError_8 : 48|2@1+ (1,0) [0|3] ""  HVESP01
 SG_ HVESP01_SenseLoadVoltError_8 : 62|2@1+ (1,0) [0|3] ""  HVESP01
 SG_ HVESP01_SenseShuntError_8 : 60|2@1+ (1,0) [0|3] ""  HVESP01
 SG_ HVESP01_SenseFcVoltErrorr_8 : 58|2@1+ (1,0) [0|3] ""  HVESP01
 SG_ HVESP01_Placeholder14_8 : 56|2@1+ (1,0) [0|3] ""  HVESP01

BO_ 2499745381 HVESP01_DiagnosticPrevB_1: 8 HVESP01
 SG_ HVESP01_SenseBrickImpHigh_1 : 2|2@1+ (1,0) [0|3] ""  HVESP01
 SG_ HVESP01_AFEfault_1 : 0|2@1+ (1,0) [0|3] ""  HVESP01
 SG_ HVESP01_AFEerror_1 : 14|2@1+ (1,0) [0|3] ""  HVESP01
 SG_ HVESP01_HVESP01MIA_1 : 12|2@1+ (1,0) [0|3] ""  HVESP01
 SG_ HVESP01_TempAmbientOverSev_1 : 10|2@1+ (1,0) [0|3] ""  HVESP01
 SG_ HVESP01_TempAmbientOverMod_1 : 8|2@1+ (1,0) [0|3] ""  HVESP01
 SG_ HVESP01_TempAmbientOverWar_1 : 22|2@1+ (1,0) [0|3] ""  HVESP01
 SG_ HVESP01_AbnormReset_1 : 20|2@1+ (1,0) [0|3] ""  HVESP01
 SG_ HVESP01_SenseAuxVoltError_1 : 18|2@1+ (1,0) [0|3] ""  HVESP01
 SG_ HVESP01_CalibrationInvalid_1 : 16|2@1+ (1,0) [0|3] ""  HVESP01
 SG_ HVESP01_TaskLockup_1 : 30|2@1+ (1,0) [0|3] ""  HVESP01
 SG_ HVESP01_RAMover_1 : 28|2@1+ (1,0) [0|3] ""  HVESP01
 SG_ HVESP01_BrickOverdischarge_1 : 26|2@1+ (1,0) [0|3] ""  HVESP01
 SG_ HVESP01_BrickOvercharge_1 : 24|2@1+ (1,0) [0|3] ""  HVESP01
 SG_ HVESP01_vBrickImbalancePer_1 : 38|2@1+ (1,0) [0|3] ""  HVESP01
 SG_ HVESP01_TempBrickImbalance_1 : 36|2@1+ (1,0) [0|3] ""  HVESP01
 SG_ HVESP01_CapPackLow_1 : 34|2@1+ (1,0) [0|3] ""  HVESP01
 SG_ HVESP01_rBrickHigh_1 : 32|2@1+ (1,0) [0|3] ""  HVESP01
 SG_ HVESP01_PowerpackInsuffErr_1 : 46|2@1+ (1,0) [0|3] ""  HVESP01
 SG_ HVESP01_BrickSoftShort_1 : 44|2@1+ (1,0) [0|3] ""  HVESP01
 SG_ HVESP01_chargeUndercurrent_1 : 42|2@1+ (1,0) [0|3] ""  HVESP01
 SG_ HVESP01_HVILcurrentSourceError_1 : 40|2@1+ (1,0) [0|3] ""  HVESP01
 SG_ HVESP01_SRS_1 : 54|2@1+ (1,0) [0|3] ""  HVESP01
 SG_ HVESP01_IsolationExtWar_1 : 52|2@1+ (1,0) [0|3] ""  HVESP01
 SG_ HVESP01_IsolationIntWar_1 : 50|2@1+ (1,0) [0|3] ""  HVESP01
 SG_ HVESP01_PyroFuseBlown_1 : 48|2@1+ (1,0) [0|3] ""  HVESP01
 SG_ HVESP01_vBrickUnderSev_1 : 62|2@1+ (1,0) [0|3] ""  HVESP01
 SG_ HVESP01_chargePrechargeTimeout_1 : 60|2@1+ (1,0) [0|3] ""  HVESP01
 SG_ HVESP01_ModuleThermFaultMod_0007 : 58|2@1+ (1,0) [0|3] ""  HVESP01
 SG_ HVESP01_ModuleThermFaultWar_0007 : 56|2@1+ (1,0) [0|3] ""  HVESP01

BO_ 2499745382 HVESP01_DiagnosticPrevB_2: 8 HVESP01
 SG_ HVESP01_SenseBrickImpHigh_2 : 2|2@1+ (1,0) [0|3] ""  HVESP01
 SG_ HVESP01_AFEfault_2 : 0|2@1+ (1,0) [0|3] ""  HVESP01
 SG_ HVESP01_AFEerror_2 : 14|2@1+ (1,0) [0|3] ""  HVESP01
 SG_ HVESP01_HVESP01MIA_2 : 12|2@1+ (1,0) [0|3] ""  HVESP01
 SG_ HVESP01_TempAmbientOverSev_2 : 10|2@1+ (1,0) [0|3] ""  HVESP01
 SG_ HVESP01_TempAmbientOverMod_2 : 8|2@1+ (1,0) [0|3] ""  HVESP01
 SG_ HVESP01_TempAmbientOverWar_2 : 22|2@1+ (1,0) [0|3] ""  HVESP01
 SG_ HVESP01_AbnormReset_2 : 20|2@1+ (1,0) [0|3] ""  HVESP01
 SG_ HVESP01_SenseAuxVoltError_2 : 18|2@1+ (1,0) [0|3] ""  HVESP01
 SG_ HVESP01_CalibrationInvalid_2 : 16|2@1+ (1,0) [0|3] ""  HVESP01
 SG_ HVESP01_TaskLockup_2 : 30|2@1+ (1,0) [0|3] ""  HVESP01
 SG_ HVESP01_RAMover_2 : 28|2@1+ (1,0) [0|3] ""  HVESP01
 SG_ HVESP01_BrickOverdischarge_2 : 26|2@1+ (1,0) [0|3] ""  HVESP01
 SG_ HVESP01_BrickOvercharge_2 : 24|2@1+ (1,0) [0|3] ""  HVESP01
 SG_ HVESP01_vBrickImbalancePer_2 : 38|2@1+ (1,0) [0|3] ""  HVESP01
 SG_ HVESP01_TempBrickImbalance_2 : 36|2@1+ (1,0) [0|3] ""  HVESP01
 SG_ HVESP01_CapPackLow_2 : 34|2@1+ (1,0) [0|3] ""  HVESP01
 SG_ HVESP01_rBrickHigh_2 : 32|2@1+ (1,0) [0|3] ""  HVESP01
 SG_ HVESP01_PowerpackInsuffErr_2 : 46|2@1+ (1,0) [0|3] ""  HVESP01
 SG_ HVESP01_BrickSoftShort_2 : 44|2@1+ (1,0) [0|3] ""  HVESP01
 SG_ HVESP01_chargeUndercurrent_2 : 42|2@1+ (1,0) [0|3] ""  HVESP01
 SG_ HVESP01_HVILcurrentSourceError_2 : 40|2@1+ (1,0) [0|3] ""  HVESP01
 SG_ HVESP01_SRS_2 : 54|2@1+ (1,0) [0|3] ""  HVESP01
 SG_ HVESP01_IsolationExtWar_2 : 52|2@1+ (1,0) [0|3] ""  HVESP01
 SG_ HVESP01_IsolationIntWar_2 : 50|2@1+ (1,0) [0|3] ""  HVESP01
 SG_ HVESP01_PyroFuseBlown_2 : 48|2@1+ (1,0) [0|3] ""  HVESP01
 SG_ HVESP01_vBrickUnderSev_2 : 62|2@1+ (1,0) [0|3] ""  HVESP01
 SG_ HVESP01_chargePrechargeTimeout_2 : 60|2@1+ (1,0) [0|3] ""  HVESP01
 SG_ HVESP01_ModuleThermFaultMod_0008 : 58|2@1+ (1,0) [0|3] ""  HVESP01
 SG_ HVESP01_ModuleThermFaultWar_0008 : 56|2@1+ (1,0) [0|3] ""  HVESP01

BO_ 2499745383 HVESP01_DiagnosticPrevB_3: 8 HVESP01
 SG_ HVESP01_SenseBrickImpHigh_3 : 2|2@1+ (1,0) [0|3] ""  HVESP01
 SG_ HVESP01_AFEfault_3 : 0|2@1+ (1,0) [0|3] ""  HVESP01
 SG_ HVESP01_AFEerror_3 : 14|2@1+ (1,0) [0|3] ""  HVESP01
 SG_ HVESP01_HVESP01MIA_3 : 12|2@1+ (1,0) [0|3] ""  HVESP01
 SG_ HVESP01_TempAmbientOverSev_3 : 10|2@1+ (1,0) [0|3] ""  HVESP01
 SG_ HVESP01_TempAmbientOverMod_3 : 8|2@1+ (1,0) [0|3] ""  HVESP01
 SG_ HVESP01_TempAmbientOverWar_3 : 22|2@1+ (1,0) [0|3] ""  HVESP01
 SG_ HVESP01_AbnormReset_3 : 20|2@1+ (1,0) [0|3] ""  HVESP01
 SG_ HVESP01_SenseAuxVoltError_3 : 18|2@1+ (1,0) [0|3] ""  HVESP01
 SG_ HVESP01_CalibrationInvalid_3 : 16|2@1+ (1,0) [0|3] ""  HVESP01
 SG_ HVESP01_TaskLockup_3 : 30|2@1+ (1,0) [0|3] ""  HVESP01
 SG_ HVESP01_RAMover_3 : 28|2@1+ (1,0) [0|3] ""  HVESP01
 SG_ HVESP01_BrickOverdischarge_3 : 26|2@1+ (1,0) [0|3] ""  HVESP01
 SG_ HVESP01_BrickOvercharge_3 : 24|2@1+ (1,0) [0|3] ""  HVESP01
 SG_ HVESP01_vBrickImbalancePer_3 : 38|2@1+ (1,0) [0|3] ""  HVESP01
 SG_ HVESP01_TempBrickImbalance_3 : 36|2@1+ (1,0) [0|3] ""  HVESP01
 SG_ HVESP01_CapPackLow_3 : 34|2@1+ (1,0) [0|3] ""  HVESP01
 SG_ HVESP01_rBrickHigh_3 : 32|2@1+ (1,0) [0|3] ""  HVESP01
 SG_ HVESP01_PowerpackInsuffErr_3 : 46|2@1+ (1,0) [0|3] ""  HVESP01
 SG_ HVESP01_BrickSoftShort_3 : 44|2@1+ (1,0) [0|3] ""  HVESP01
 SG_ HVESP01_chargeUndercurrent_3 : 42|2@1+ (1,0) [0|3] ""  HVESP01
 SG_ HVESP01_HVILcurrentSourceError_3 : 40|2@1+ (1,0) [0|3] ""  HVESP01
 SG_ HVESP01_SRS_3 : 54|2@1+ (1,0) [0|3] ""  HVESP01
 SG_ HVESP01_IsolationExtWar_3 : 52|2@1+ (1,0) [0|3] ""  HVESP01
 SG_ HVESP01_IsolationIntWar_3 : 50|2@1+ (1,0) [0|3] ""  HVESP01
 SG_ HVESP01_PyroFuseBlown_3 : 48|2@1+ (1,0) [0|3] ""  HVESP01
 SG_ HVESP01_vBrickUnderSev_3 : 62|2@1+ (1,0) [0|3] ""  HVESP01
 SG_ HVESP01_chargePrechargeTimeout_3 : 60|2@1+ (1,0) [0|3] ""  HVESP01
 SG_ HVESP01_ModuleThermFaultMod_0009 : 58|2@1+ (1,0) [0|3] ""  HVESP01
 SG_ HVESP01_ModuleThermFaultWar_0009 : 56|2@1+ (1,0) [0|3] ""  HVESP01

BO_ 2499745384 HVESP01_DiagnosticPrevB_4: 8 HVESP01
 SG_ HVESP01_SenseBrickImpHigh_4 : 2|2@1+ (1,0) [0|3] ""  HVESP01
 SG_ HVESP01_AFEfault_4 : 0|2@1+ (1,0) [0|3] ""  HVESP01
 SG_ HVESP01_AFEerror_4 : 14|2@1+ (1,0) [0|3] ""  HVESP01
 SG_ HVESP01_HVESP01MIA_4 : 12|2@1+ (1,0) [0|3] ""  HVESP01
 SG_ HVESP01_TempAmbientOverSev_4 : 10|2@1+ (1,0) [0|3] ""  HVESP01
 SG_ HVESP01_TempAmbientOverMod_4 : 8|2@1+ (1,0) [0|3] ""  HVESP01
 SG_ HVESP01_TempAmbientOverWar_4 : 22|2@1+ (1,0) [0|3] ""  HVESP01
 SG_ HVESP01_AbnormReset_4 : 20|2@1+ (1,0) [0|3] ""  HVESP01
 SG_ HVESP01_SenseAuxVoltError_4 : 18|2@1+ (1,0) [0|3] ""  HVESP01
 SG_ HVESP01_CalibrationInvalid_4 : 16|2@1+ (1,0) [0|3] ""  HVESP01
 SG_ HVESP01_TaskLockup_4 : 30|2@1+ (1,0) [0|3] ""  HVESP01
 SG_ HVESP01_RAMover_4 : 28|2@1+ (1,0) [0|3] ""  HVESP01
 SG_ HVESP01_BrickOverdischarge_4 : 26|2@1+ (1,0) [0|3] ""  HVESP01
 SG_ HVESP01_BrickOvercharge_4 : 24|2@1+ (1,0) [0|3] ""  HVESP01
 SG_ HVESP01_vBrickImbalancePer_4 : 38|2@1+ (1,0) [0|3] ""  HVESP01
 SG_ HVESP01_TempBrickImbalance_4 : 36|2@1+ (1,0) [0|3] ""  HVESP01
 SG_ HVESP01_CapPackLow_4 : 34|2@1+ (1,0) [0|3] ""  HVESP01
 SG_ HVESP01_rBrickHigh_4 : 32|2@1+ (1,0) [0|3] ""  HVESP01
 SG_ HVESP01_PowerpackInsuffErr_4 : 46|2@1+ (1,0) [0|3] ""  HVESP01
 SG_ HVESP01_BrickSoftShort_4 : 44|2@1+ (1,0) [0|3] ""  HVESP01
 SG_ HVESP01_chargeUndercurrent_4 : 42|2@1+ (1,0) [0|3] ""  HVESP01
 SG_ HVESP01_HVILcurrentSourceError_4 : 40|2@1+ (1,0) [0|3] ""  HVESP01
 SG_ HVESP01_SRS_4 : 54|2@1+ (1,0) [0|3] ""  HVESP01
 SG_ HVESP01_IsolationExtWar_4 : 52|2@1+ (1,0) [0|3] ""  HVESP01
 SG_ HVESP01_IsolationIntWar_4 : 50|2@1+ (1,0) [0|3] ""  HVESP01
 SG_ HVESP01_PyroFuseBlown_4 : 48|2@1+ (1,0) [0|3] ""  HVESP01
 SG_ HVESP01_vBrickUnderSev_4 : 62|2@1+ (1,0) [0|3] ""  HVESP01
 SG_ HVESP01_chargePrechargeTimeout_4 : 60|2@1+ (1,0) [0|3] ""  HVESP01
 SG_ HVESP01_ModuleThermFaultMod_0010 : 58|2@1+ (1,0) [0|3] ""  HVESP01
 SG_ HVESP01_ModuleThermFaultWar_0010 : 56|2@1+ (1,0) [0|3] ""  HVESP01

BO_ 2499745385 HVESP01_DiagnosticPrevB_5: 8 HVESP01
 SG_ HVESP01_SenseBrickImpHigh_5 : 2|2@1+ (1,0) [0|3] ""  HVESP01
 SG_ HVESP01_AFEfault_5 : 0|2@1+ (1,0) [0|3] ""  HVESP01
 SG_ HVESP01_AFEerror_5 : 14|2@1+ (1,0) [0|3] ""  HVESP01
 SG_ HVESP01_HVESP01MIA_5 : 12|2@1+ (1,0) [0|3] ""  HVESP01
 SG_ HVESP01_TempAmbientOverSev_5 : 10|2@1+ (1,0) [0|3] ""  HVESP01
 SG_ HVESP01_TempAmbientOverMod_5 : 8|2@1+ (1,0) [0|3] ""  HVESP01
 SG_ HVESP01_TempAmbientOverWar_5 : 22|2@1+ (1,0) [0|3] ""  HVESP01
 SG_ HVESP01_AbnormReset_5 : 20|2@1+ (1,0) [0|3] ""  HVESP01
 SG_ HVESP01_SenseAuxVoltError_5 : 18|2@1+ (1,0) [0|3] ""  HVESP01
 SG_ HVESP01_CalibrationInvalid_5 : 16|2@1+ (1,0) [0|3] ""  HVESP01
 SG_ HVESP01_TaskLockup_5 : 30|2@1+ (1,0) [0|3] ""  HVESP01
 SG_ HVESP01_RAMover_5 : 28|2@1+ (1,0) [0|3] ""  HVESP01
 SG_ HVESP01_BrickOverdischarge_5 : 26|2@1+ (1,0) [0|3] ""  HVESP01
 SG_ HVESP01_BrickOvercharge_5 : 24|2@1+ (1,0) [0|3] ""  HVESP01
 SG_ HVESP01_vBrickImbalancePer_5 : 38|2@1+ (1,0) [0|3] ""  HVESP01
 SG_ HVESP01_TempBrickImbalance_5 : 36|2@1+ (1,0) [0|3] ""  HVESP01
 SG_ HVESP01_CapPackLow_5 : 34|2@1+ (1,0) [0|3] ""  HVESP01
 SG_ HVESP01_rBrickHigh_5 : 32|2@1+ (1,0) [0|3] ""  HVESP01
 SG_ HVESP01_PowerpackInsuffErr_5 : 46|2@1+ (1,0) [0|3] ""  HVESP01
 SG_ HVESP01_BrickSoftShort_5 : 44|2@1+ (1,0) [0|3] ""  HVESP01
 SG_ HVESP01_chargeUndercurrent_5 : 42|2@1+ (1,0) [0|3] ""  HVESP01
 SG_ HVESP01_HVILcurrentSourceError_5 : 40|2@1+ (1,0) [0|3] ""  HVESP01
 SG_ HVESP01_SRS_5 : 54|2@1+ (1,0) [0|3] ""  HVESP01
 SG_ HVESP01_IsolationExtWar_5 : 52|2@1+ (1,0) [0|3] ""  HVESP01
 SG_ HVESP01_IsolationIntWar_5 : 50|2@1+ (1,0) [0|3] ""  HVESP01
 SG_ HVESP01_PyroFuseBlown_5 : 48|2@1+ (1,0) [0|3] ""  HVESP01
 SG_ HVESP01_vBrickUnderSev_5 : 62|2@1+ (1,0) [0|3] ""  HVESP01
 SG_ HVESP01_chargePrechargeTimeout_5 : 60|2@1+ (1,0) [0|3] ""  HVESP01
 SG_ HVESP01_ModuleThermFaultMod_0011 : 58|2@1+ (1,0) [0|3] ""  HVESP01
 SG_ HVESP01_ModuleThermFaultWar_0011 : 56|2@1+ (1,0) [0|3] ""  HVESP01

BO_ 2499745386 HVESP01_DiagnosticPrevB_6: 8 HVESP01
 SG_ HVESP01_SenseBrickImpHigh_6 : 2|2@1+ (1,0) [0|3] ""  HVESP01
 SG_ HVESP01_AFEfault_6 : 0|2@1+ (1,0) [0|3] ""  HVESP01
 SG_ HVESP01_AFEerror_6 : 14|2@1+ (1,0) [0|3] ""  HVESP01
 SG_ HVESP01_HVESP01MIA_6 : 12|2@1+ (1,0) [0|3] ""  HVESP01
 SG_ HVESP01_TempAmbientOverSev_6 : 10|2@1+ (1,0) [0|3] ""  HVESP01
 SG_ HVESP01_TempAmbientOverMod_6 : 8|2@1+ (1,0) [0|3] ""  HVESP01
 SG_ HVESP01_TempAmbientOverWar_6 : 22|2@1+ (1,0) [0|3] ""  HVESP01
 SG_ HVESP01_AbnormReset_6 : 20|2@1+ (1,0) [0|3] ""  HVESP01
 SG_ HVESP01_SenseAuxVoltError_6 : 18|2@1+ (1,0) [0|3] ""  HVESP01
 SG_ HVESP01_CalibrationInvalid_6 : 16|2@1+ (1,0) [0|3] ""  HVESP01
 SG_ HVESP01_TaskLockup_6 : 30|2@1+ (1,0) [0|3] ""  HVESP01
 SG_ HVESP01_RAMover_6 : 28|2@1+ (1,0) [0|3] ""  HVESP01
 SG_ HVESP01_BrickOverdischarge_6 : 26|2@1+ (1,0) [0|3] ""  HVESP01
 SG_ HVESP01_BrickOvercharge_6 : 24|2@1+ (1,0) [0|3] ""  HVESP01
 SG_ HVESP01_vBrickImbalancePer_6 : 38|2@1+ (1,0) [0|3] ""  HVESP01
 SG_ HVESP01_TempBrickImbalance_6 : 36|2@1+ (1,0) [0|3] ""  HVESP01
 SG_ HVESP01_CapPackLow_6 : 34|2@1+ (1,0) [0|3] ""  HVESP01
 SG_ HVESP01_rBrickHigh_6 : 32|2@1+ (1,0) [0|3] ""  HVESP01
 SG_ HVESP01_PowerpackInsuffErr_6 : 46|2@1+ (1,0) [0|3] ""  HVESP01
 SG_ HVESP01_BrickSoftShort_6 : 44|2@1+ (1,0) [0|3] ""  HVESP01
 SG_ HVESP01_chargeUndercurrent_6 : 42|2@1+ (1,0) [0|3] ""  HVESP01
 SG_ HVESP01_HVILcurrentSourceError_6 : 40|2@1+ (1,0) [0|3] ""  HVESP01
 SG_ HVESP01_SRS_6 : 54|2@1+ (1,0) [0|3] ""  HVESP01
 SG_ HVESP01_IsolationExtWar_6 : 52|2@1+ (1,0) [0|3] ""  HVESP01
 SG_ HVESP01_IsolationIntWar_6 : 50|2@1+ (1,0) [0|3] ""  HVESP01
 SG_ HVESP01_PyroFuseBlown_6 : 48|2@1+ (1,0) [0|3] ""  HVESP01
 SG_ HVESP01_vBrickUnderSev_6 : 62|2@1+ (1,0) [0|3] ""  HVESP01
 SG_ HVESP01_chargePrechargeTimeout_6 : 60|2@1+ (1,0) [0|3] ""  HVESP01
 SG_ HVESP01_ModuleThermFaultMod_0012 : 58|2@1+ (1,0) [0|3] ""  HVESP01
 SG_ HVESP01_ModuleThermFaultWar_0012 : 56|2@1+ (1,0) [0|3] ""  HVESP01

BO_ 2499745387 HVESP01_DiagnosticPrevB_7: 8 HVESP01
 SG_ HVESP01_SenseBrickImpHigh_7 : 2|2@1+ (1,0) [0|3] ""  HVESP01
 SG_ HVESP01_AFEfault_7 : 0|2@1+ (1,0) [0|3] ""  HVESP01
 SG_ HVESP01_AFEerror_7 : 14|2@1+ (1,0) [0|3] ""  HVESP01
 SG_ HVESP01_HVESP01MIA_7 : 12|2@1+ (1,0) [0|3] ""  HVESP01
 SG_ HVESP01_TempAmbientOverSev_7 : 10|2@1+ (1,0) [0|3] ""  HVESP01
 SG_ HVESP01_TempAmbientOverMod_7 : 8|2@1+ (1,0) [0|3] ""  HVESP01
 SG_ HVESP01_TempAmbientOverWar_7 : 22|2@1+ (1,0) [0|3] ""  HVESP01
 SG_ HVESP01_AbnormReset_7 : 20|2@1+ (1,0) [0|3] ""  HVESP01
 SG_ HVESP01_SenseAuxVoltError_7 : 18|2@1+ (1,0) [0|3] ""  HVESP01
 SG_ HVESP01_CalibrationInvalid_7 : 16|2@1+ (1,0) [0|3] ""  HVESP01
 SG_ HVESP01_TaskLockup_7 : 30|2@1+ (1,0) [0|3] ""  HVESP01
 SG_ HVESP01_RAMover_7 : 28|2@1+ (1,0) [0|3] ""  HVESP01
 SG_ HVESP01_BrickOverdischarge_7 : 26|2@1+ (1,0) [0|3] ""  HVESP01
 SG_ HVESP01_BrickOvercharge_7 : 24|2@1+ (1,0) [0|3] ""  HVESP01
 SG_ HVESP01_vBrickImbalancePer_7 : 38|2@1+ (1,0) [0|3] ""  HVESP01
 SG_ HVESP01_TempBrickImbalance_7 : 36|2@1+ (1,0) [0|3] ""  HVESP01
 SG_ HVESP01_CapPackLow_7 : 34|2@1+ (1,0) [0|3] ""  HVESP01
 SG_ HVESP01_rBrickHigh_7 : 32|2@1+ (1,0) [0|3] ""  HVESP01
 SG_ HVESP01_PowerpackInsuffErr_7 : 46|2@1+ (1,0) [0|3] ""  HVESP01
 SG_ HVESP01_BrickSoftShort_7 : 44|2@1+ (1,0) [0|3] ""  HVESP01
 SG_ HVESP01_chargeUndercurrent_7 : 42|2@1+ (1,0) [0|3] ""  HVESP01
 SG_ HVESP01_HVILcurrentSourceError_7 : 40|2@1+ (1,0) [0|3] ""  HVESP01
 SG_ HVESP01_SRS_7 : 54|2@1+ (1,0) [0|3] ""  HVESP01
 SG_ HVESP01_IsolationExtWar_7 : 52|2@1+ (1,0) [0|3] ""  HVESP01
 SG_ HVESP01_IsolationIntWar_7 : 50|2@1+ (1,0) [0|3] ""  HVESP01
 SG_ HVESP01_PyroFuseBlown_7 : 48|2@1+ (1,0) [0|3] ""  HVESP01
 SG_ HVESP01_vBrickUnderSev_7 : 62|2@1+ (1,0) [0|3] ""  HVESP01
 SG_ HVESP01_chargePrechargeTimeout_7 : 60|2@1+ (1,0) [0|3] ""  HVESP01
 SG_ HVESP01_ModuleThermFaultMod_0013 : 58|2@1+ (1,0) [0|3] ""  HVESP01
 SG_ HVESP01_ModuleThermFaultWar_0013 : 56|2@1+ (1,0) [0|3] ""  HVESP01

BO_ 2499745388 HVESP01_DiagnosticPrevB_8: 8 HVESP01
 SG_ HVESP01_SenseBrickImpHigh_8 : 2|2@1+ (1,0) [0|3] ""  HVESP01
 SG_ HVESP01_AFEfault_8 : 0|2@1+ (1,0) [0|3] ""  HVESP01
 SG_ HVESP01_AFEerror_8 : 14|2@1+ (1,0) [0|3] ""  HVESP01
 SG_ HVESP01_HVESP01MIA_8 : 12|2@1+ (1,0) [0|3] ""  HVESP01
 SG_ HVESP01_TempAmbientOverSev_8 : 10|2@1+ (1,0) [0|3] ""  HVESP01
 SG_ HVESP01_TempAmbientOverMod_8 : 8|2@1+ (1,0) [0|3] ""  HVESP01
 SG_ HVESP01_TempAmbientOverWar_8 : 22|2@1+ (1,0) [0|3] ""  HVESP01
 SG_ HVESP01_AbnormReset_8 : 20|2@1+ (1,0) [0|3] ""  HVESP01
 SG_ HVESP01_SenseAuxVoltError_8 : 18|2@1+ (1,0) [0|3] ""  HVESP01
 SG_ HVESP01_CalibrationInvalid_8 : 16|2@1+ (1,0) [0|3] ""  HVESP01
 SG_ HVESP01_TaskLockup_8 : 30|2@1+ (1,0) [0|3] ""  HVESP01
 SG_ HVESP01_RAMover_8 : 28|2@1+ (1,0) [0|3] ""  HVESP01
 SG_ HVESP01_BrickOverdischarge_8 : 26|2@1+ (1,0) [0|3] ""  HVESP01
 SG_ HVESP01_BrickOvercharge_8 : 24|2@1+ (1,0) [0|3] ""  HVESP01
 SG_ HVESP01_vBrickImbalancePer_8 : 38|2@1+ (1,0) [0|3] ""  HVESP01
 SG_ HVESP01_TempBrickImbalance_8 : 36|2@1+ (1,0) [0|3] ""  HVESP01
 SG_ HVESP01_CapPackLow_8 : 34|2@1+ (1,0) [0|3] ""  HVESP01
 SG_ HVESP01_rBrickHigh_8 : 32|2@1+ (1,0) [0|3] ""  HVESP01
 SG_ HVESP01_PowerpackInsuffErr_8 : 46|2@1+ (1,0) [0|3] ""  HVESP01
 SG_ HVESP01_BrickSoftShort_8 : 44|2@1+ (1,0) [0|3] ""  HVESP01
 SG_ HVESP01_chargeUndercurrent_8 : 42|2@1+ (1,0) [0|3] ""  HVESP01
 SG_ HVESP01_HVILcurrentSourceError_8 : 40|2@1+ (1,0) [0|3] ""  HVESP01
 SG_ HVESP01_SRS_8 : 54|2@1+ (1,0) [0|3] ""  HVESP01
 SG_ HVESP01_IsolationExtWar_8 : 52|2@1+ (1,0) [0|3] ""  HVESP01
 SG_ HVESP01_IsolationIntWar_8 : 50|2@1+ (1,0) [0|3] ""  HVESP01
 SG_ HVESP01_PyroFuseBlown_8 : 48|2@1+ (1,0) [0|3] ""  HVESP01
 SG_ HVESP01_vBrickUnderSev_8 : 62|2@1+ (1,0) [0|3] ""  HVESP01
 SG_ HVESP01_chargePrechargeTimeout_8 : 60|2@1+ (1,0) [0|3] ""  HVESP01
 SG_ HVESP01_ModuleThermFaultMod_0014 : 58|2@1+ (1,0) [0|3] ""  HVESP01
 SG_ HVESP01_ModuleThermFaultWar_0014 : 56|2@1+ (1,0) [0|3] ""  HVESP01

BO_ 2499745637 HVESP01_DiagnosticPrevC_1: 8 HVESP01
 SG_ HVESP01_PackVoltageImbalance_1 : 58|2@1+ (1,0) [0|3] ""  HVESP01
 SG_ HVESP01_PrechargeoverCurrent_1 : 56|2@1+ (1,0) [0|3] ""  HVESP01
 SG_ HVESP01_HVILvoltageError_1 : 2|2@1+ (1,0) [0|3] ""  HVESP01
 SG_ HVESP01_HVILcurrentReturnError_1 : 0|2@1+ (1,0) [0|3] ""  HVESP01
 SG_ HVESP01_PosFcContWelded_1 : 14|2@1+ (1,0) [0|3] ""  HVESP01
 SG_ HVESP01_PosFcContStuckOpen_1 : 12|2@1+ (1,0) [0|3] ""  HVESP01
 SG_ HVESP01_NegFcContWelded_1 : 10|2@1+ (1,0) [0|3] ""  HVESP01
 SG_ HVESP01_NegFcContStuckOpen_1 : 8|2@1+ (1,0) [0|3] ""  HVESP01
 SG_ HVESP01_IsospiBreak_1 : 22|2@1+ (1,0) [0|3] ""  HVESP01
 SG_ HVESP01_IsolationIntFault_1 : 20|2@1+ (1,0) [0|3] ""  HVESP01
 SG_ HVESP01_IsolationExtFault_1 : 18|2@1+ (1,0) [0|3] ""  HVESP01
 SG_ HVESP01_pcb_error_1 : 16|2@1+ (1,0) [0|3] ""  HVESP01
 SG_ HVESP01_hall_eff_hi_rang_err_1 : 30|2@1+ (1,0) [0|3] ""  HVESP01
 SG_ HVESP01_brick_volt_sns_open_1 : 28|2@1+ (1,0) [0|3] ""  HVESP01
 SG_ HVESP01_5v_error_1 : 26|2@1+ (1,0) [0|3] ""  HVESP01
 SG_ HVESP01_3_3_hot_error_1 : 24|2@1+ (1,0) [0|3] ""  HVESP01
 SG_ HVESP01_12v_input_error_1 : 38|2@1+ (1,0) [0|3] ""  HVESP01
 SG_ HVESP01_1_25v_error_1 : 36|2@1+ (1,0) [0|3] ""  HVESP01
 SG_ HVESP01_shunt_MIA_1 : 34|2@1+ (1,0) [0|3] ""  HVESP01
 SG_ HVESP01_SBC_int_reg_error_1 : 32|2@1+ (1,0) [0|3] ""  HVESP01
 SG_ HVESP01_pos_3_3v_analog_error_1 : 46|2@1+ (1,0) [0|3] ""  HVESP01
 SG_ HVESP01_outlt_clnt_thrm_open_1 : 44|2@1+ (1,0) [0|3] ""  HVESP01
 SG_ HVESP01_neg_3_3_analog_error_1 : 42|2@1+ (1,0) [0|3] ""  HVESP01
 SG_ HVESP01_inlet_clnt_thrm_open_1 : 40|2@1+ (1,0) [0|3] ""  HVESP01
 SG_ HVESP01_hall_eff_lo_rang_err_1 : 54|2@1+ (1,0) [0|3] ""  HVESP01
 SG_ HVESP01_outlt_clnt_thrm_short_1 : 52|2@1+ (1,0) [0|3] ""  HVESP01
 SG_ HVESP01_inlet_clnt_thrm_short_1 : 50|2@1+ (1,0) [0|3] ""  HVESP01
 SG_ HVESP01_3_3v_error_1 : 48|2@1+ (1,0) [0|3] ""  HVESP01

BO_ 2499745638 HVESP01_DiagnosticPrevC_2: 8 HVESP01
 SG_ HVESP01_PackVoltageImbalance_2 : 58|2@1+ (1,0) [0|3] ""  HVESP01
 SG_ HVESP01_PrechargeoverCurrent_2 : 56|2@1+ (1,0) [0|3] ""  HVESP01
 SG_ HVESP01_HVILvoltageError_2 : 2|2@1+ (1,0) [0|3] ""  HVESP01
 SG_ HVESP01_HVILcurrentReturnError_2 : 0|2@1+ (1,0) [0|3] ""  HVESP01
 SG_ HVESP01_PosFcContWelded_2 : 14|2@1+ (1,0) [0|3] ""  HVESP01
 SG_ HVESP01_PosFcContStuckOpen_2 : 12|2@1+ (1,0) [0|3] ""  HVESP01
 SG_ HVESP01_NegFcContWelded_2 : 10|2@1+ (1,0) [0|3] ""  HVESP01
 SG_ HVESP01_NegFcContStuckOpen_2 : 8|2@1+ (1,0) [0|3] ""  HVESP01
 SG_ HVESP01_IsospiBreak_2 : 22|2@1+ (1,0) [0|3] ""  HVESP01
 SG_ HVESP01_IsolationIntFault_2 : 20|2@1+ (1,0) [0|3] ""  HVESP01
 SG_ HVESP01_IsolationExtFault_2 : 18|2@1+ (1,0) [0|3] ""  HVESP01
 SG_ HVESP01_pcb_error_2 : 16|2@1+ (1,0) [0|3] ""  HVESP01
 SG_ HVESP01_hall_eff_hi_rang_err_2 : 30|2@1+ (1,0) [0|3] ""  HVESP01
 SG_ HVESP01_brick_volt_sns_open_2 : 28|2@1+ (1,0) [0|3] ""  HVESP01
 SG_ HVESP01_5v_error_2 : 26|2@1+ (1,0) [0|3] ""  HVESP01
 SG_ HVESP01_3_3_hot_error_2 : 24|2@1+ (1,0) [0|3] ""  HVESP01
 SG_ HVESP01_12v_input_error_2 : 38|2@1+ (1,0) [0|3] ""  HVESP01
 SG_ HVESP01_1_25v_error_2 : 36|2@1+ (1,0) [0|3] ""  HVESP01
 SG_ HVESP01_shunt_MIA_2 : 34|2@1+ (1,0) [0|3] ""  HVESP01
 SG_ HVESP01_SBC_int_reg_error_2 : 32|2@1+ (1,0) [0|3] ""  HVESP01
 SG_ HVESP01_pos_3_3v_analog_error_2 : 46|2@1+ (1,0) [0|3] ""  HVESP01
 SG_ HVESP01_outlt_clnt_thrm_open_2 : 44|2@1+ (1,0) [0|3] ""  HVESP01
 SG_ HVESP01_neg_3_3_analog_error_2 : 42|2@1+ (1,0) [0|3] ""  HVESP01
 SG_ HVESP01_inlet_clnt_thrm_open_2 : 40|2@1+ (1,0) [0|3] ""  HVESP01
 SG_ HVESP01_hall_eff_lo_rang_err_2 : 54|2@1+ (1,0) [0|3] ""  HVESP01
 SG_ HVESP01_outlt_clnt_thrm_short_2 : 52|2@1+ (1,0) [0|3] ""  HVESP01
 SG_ HVESP01_inlet_clnt_thrm_short_2 : 50|2@1+ (1,0) [0|3] ""  HVESP01
 SG_ HVESP01_3_3v_error_2 : 48|2@1+ (1,0) [0|3] ""  HVESP01

BO_ 2499745639 HVESP01_DiagnosticPrevC_3: 8 HVESP01
 SG_ HVESP01_PackVoltageImbalance_3 : 58|2@1+ (1,0) [0|3] ""  HVESP01
 SG_ HVESP01_PrechargeoverCurrent_3 : 56|2@1+ (1,0) [0|3] ""  HVESP01
 SG_ HVESP01_HVILvoltageError_3 : 2|2@1+ (1,0) [0|3] ""  HVESP01
 SG_ HVESP01_HVILcurrentReturnError_3 : 0|2@1+ (1,0) [0|3] ""  HVESP01
 SG_ HVESP01_PosFcContWelded_3 : 14|2@1+ (1,0) [0|3] ""  HVESP01
 SG_ HVESP01_PosFcContStuckOpen_3 : 12|2@1+ (1,0) [0|3] ""  HVESP01
 SG_ HVESP01_NegFcContWelded_3 : 10|2@1+ (1,0) [0|3] ""  HVESP01
 SG_ HVESP01_NegFcContStuckOpen_3 : 8|2@1+ (1,0) [0|3] ""  HVESP01
 SG_ HVESP01_IsospiBreak_3 : 22|2@1+ (1,0) [0|3] ""  HVESP01
 SG_ HVESP01_IsolationIntFault_3 : 20|2@1+ (1,0) [0|3] ""  HVESP01
 SG_ HVESP01_IsolationExtFault_3 : 18|2@1+ (1,0) [0|3] ""  HVESP01
 SG_ HVESP01_pcb_error_3 : 16|2@1+ (1,0) [0|3] ""  HVESP01
 SG_ HVESP01_hall_eff_hi_rang_err_3 : 30|2@1+ (1,0) [0|3] ""  HVESP01
 SG_ HVESP01_brick_volt_sns_open_3 : 28|2@1+ (1,0) [0|3] ""  HVESP01
 SG_ HVESP01_5v_error_3 : 26|2@1+ (1,0) [0|3] ""  HVESP01
 SG_ HVESP01_3_3_hot_error_3 : 24|2@1+ (1,0) [0|3] ""  HVESP01
 SG_ HVESP01_12v_input_error_3 : 38|2@1+ (1,0) [0|3] ""  HVESP01
 SG_ HVESP01_1_25v_error_3 : 36|2@1+ (1,0) [0|3] ""  HVESP01
 SG_ HVESP01_shunt_MIA_3 : 34|2@1+ (1,0) [0|3] ""  HVESP01
 SG_ HVESP01_SBC_int_reg_error_3 : 32|2@1+ (1,0) [0|3] ""  HVESP01
 SG_ HVESP01_pos_3_3v_analog_error_3 : 46|2@1+ (1,0) [0|3] ""  HVESP01
 SG_ HVESP01_outlt_clnt_thrm_open_3 : 44|2@1+ (1,0) [0|3] ""  HVESP01
 SG_ HVESP01_neg_3_3_analog_error_3 : 42|2@1+ (1,0) [0|3] ""  HVESP01
 SG_ HVESP01_inlet_clnt_thrm_open_3 : 40|2@1+ (1,0) [0|3] ""  HVESP01
 SG_ HVESP01_hall_eff_lo_rang_err_3 : 54|2@1+ (1,0) [0|3] ""  HVESP01
 SG_ HVESP01_outlt_clnt_thrm_short_3 : 52|2@1+ (1,0) [0|3] ""  HVESP01
 SG_ HVESP01_inlet_clnt_thrm_short_3 : 50|2@1+ (1,0) [0|3] ""  HVESP01
 SG_ HVESP01_3_3v_error_3 : 48|2@1+ (1,0) [0|3] ""  HVESP01

BO_ 2499745640 HVESP01_DiagnosticPrevC_4: 8 HVESP01
 SG_ HVESP01_PackVoltageImbalance_4 : 58|2@1+ (1,0) [0|3] ""  HVESP01
 SG_ HVESP01_PrechargeoverCurrent_4 : 56|2@1+ (1,0) [0|3] ""  HVESP01
 SG_ HVESP01_HVILvoltageError_4 : 2|2@1+ (1,0) [0|3] ""  HVESP01
 SG_ HVESP01_HVILcurrentReturnError_4 : 0|2@1+ (1,0) [0|3] ""  HVESP01
 SG_ HVESP01_PosFcContWelded_4 : 14|2@1+ (1,0) [0|3] ""  HVESP01
 SG_ HVESP01_PosFcContStuckOpen_4 : 12|2@1+ (1,0) [0|3] ""  HVESP01
 SG_ HVESP01_NegFcContWelded_4 : 10|2@1+ (1,0) [0|3] ""  HVESP01
 SG_ HVESP01_NegFcContStuckOpen_4 : 8|2@1+ (1,0) [0|3] ""  HVESP01
 SG_ HVESP01_IsospiBreak_4 : 22|2@1+ (1,0) [0|3] ""  HVESP01
 SG_ HVESP01_IsolationIntFault_4 : 20|2@1+ (1,0) [0|3] ""  HVESP01
 SG_ HVESP01_IsolationExtFault_4 : 18|2@1+ (1,0) [0|3] ""  HVESP01
 SG_ HVESP01_pcb_error_4 : 16|2@1+ (1,0) [0|3] ""  HVESP01
 SG_ HVESP01_hall_eff_hi_rang_err_4 : 30|2@1+ (1,0) [0|3] ""  HVESP01
 SG_ HVESP01_brick_volt_sns_open_4 : 28|2@1+ (1,0) [0|3] ""  HVESP01
 SG_ HVESP01_5v_error_4 : 26|2@1+ (1,0) [0|3] ""  HVESP01
 SG_ HVESP01_3_3_hot_error_4 : 24|2@1+ (1,0) [0|3] ""  HVESP01
 SG_ HVESP01_12v_input_error_4 : 38|2@1+ (1,0) [0|3] ""  HVESP01
 SG_ HVESP01_1_25v_error_4 : 36|2@1+ (1,0) [0|3] ""  HVESP01
 SG_ HVESP01_shunt_MIA_4 : 34|2@1+ (1,0) [0|3] ""  HVESP01
 SG_ HVESP01_SBC_int_reg_error_4 : 32|2@1+ (1,0) [0|3] ""  HVESP01
 SG_ HVESP01_pos_3_3v_analog_error_4 : 46|2@1+ (1,0) [0|3] ""  HVESP01
 SG_ HVESP01_outlt_clnt_thrm_open_4 : 44|2@1+ (1,0) [0|3] ""  HVESP01
 SG_ HVESP01_neg_3_3_analog_error_4 : 42|2@1+ (1,0) [0|3] ""  HVESP01
 SG_ HVESP01_inlet_clnt_thrm_open_4 : 40|2@1+ (1,0) [0|3] ""  HVESP01
 SG_ HVESP01_hall_eff_lo_rang_err_4 : 54|2@1+ (1,0) [0|3] ""  HVESP01
 SG_ HVESP01_outlt_clnt_thrm_short_4 : 52|2@1+ (1,0) [0|3] ""  HVESP01
 SG_ HVESP01_inlet_clnt_thrm_short_4 : 50|2@1+ (1,0) [0|3] ""  HVESP01
 SG_ HVESP01_3_3v_error_4 : 48|2@1+ (1,0) [0|3] ""  HVESP01

BO_ 2499745641 HVESP01_DiagnosticPrevC_5: 8 HVESP01
 SG_ HVESP01_PackVoltageImbalance_5 : 58|2@1+ (1,0) [0|3] ""  HVESP01
 SG_ HVESP01_PrechargeoverCurrent_5 : 56|2@1+ (1,0) [0|3] ""  HVESP01
 SG_ HVESP01_HVILvoltageError_5 : 2|2@1+ (1,0) [0|3] ""  HVESP01
 SG_ HVESP01_HVILcurrentReturnError_5 : 0|2@1+ (1,0) [0|3] ""  HVESP01
 SG_ HVESP01_PosFcContWelded_5 : 14|2@1+ (1,0) [0|3] ""  HVESP01
 SG_ HVESP01_PosFcContStuckOpen_5 : 12|2@1+ (1,0) [0|3] ""  HVESP01
 SG_ HVESP01_NegFcContWelded_5 : 10|2@1+ (1,0) [0|3] ""  HVESP01
 SG_ HVESP01_NegFcContStuckOpen_5 : 8|2@1+ (1,0) [0|3] ""  HVESP01
 SG_ HVESP01_IsospiBreak_5 : 22|2@1+ (1,0) [0|3] ""  HVESP01
 SG_ HVESP01_IsolationIntFault_5 : 20|2@1+ (1,0) [0|3] ""  HVESP01
 SG_ HVESP01_IsolationExtFault_5 : 18|2@1+ (1,0) [0|3] ""  HVESP01
 SG_ HVESP01_pcb_error_5 : 16|2@1+ (1,0) [0|3] ""  HVESP01
 SG_ HVESP01_hall_eff_hi_rang_err_5 : 30|2@1+ (1,0) [0|3] ""  HVESP01
 SG_ HVESP01_brick_volt_sns_open_5 : 28|2@1+ (1,0) [0|3] ""  HVESP01
 SG_ HVESP01_5v_error_5 : 26|2@1+ (1,0) [0|3] ""  HVESP01
 SG_ HVESP01_3_3_hot_error_5 : 24|2@1+ (1,0) [0|3] ""  HVESP01
 SG_ HVESP01_12v_input_error_5 : 38|2@1+ (1,0) [0|3] ""  HVESP01
 SG_ HVESP01_1_25v_error_5 : 36|2@1+ (1,0) [0|3] ""  HVESP01
 SG_ HVESP01_shunt_MIA_5 : 34|2@1+ (1,0) [0|3] ""  HVESP01
 SG_ HVESP01_SBC_int_reg_error_5 : 32|2@1+ (1,0) [0|3] ""  HVESP01
 SG_ HVESP01_pos_3_3v_analog_error_5 : 46|2@1+ (1,0) [0|3] ""  HVESP01
 SG_ HVESP01_outlt_clnt_thrm_open_5 : 44|2@1+ (1,0) [0|3] ""  HVESP01
 SG_ HVESP01_neg_3_3_analog_error_5 : 42|2@1+ (1,0) [0|3] ""  HVESP01
 SG_ HVESP01_inlet_clnt_thrm_open_5 : 40|2@1+ (1,0) [0|3] ""  HVESP01
 SG_ HVESP01_hall_eff_lo_rang_err_5 : 54|2@1+ (1,0) [0|3] ""  HVESP01
 SG_ HVESP01_outlt_clnt_thrm_short_5 : 52|2@1+ (1,0) [0|3] ""  HVESP01
 SG_ HVESP01_inlet_clnt_thrm_short_5 : 50|2@1+ (1,0) [0|3] ""  HVESP01
 SG_ HVESP01_3_3v_error_5 : 48|2@1+ (1,0) [0|3] ""  HVESP01

BO_ 2499745642 HVESP01_DiagnosticPrevC_6: 8 HVESP01
 SG_ HVESP01_PackVoltageImbalance_6 : 58|2@1+ (1,0) [0|3] ""  HVESP01
 SG_ HVESP01_PrechargeoverCurrent_6 : 56|2@1+ (1,0) [0|3] ""  HVESP01
 SG_ HVESP01_HVILvoltageError_6 : 2|2@1+ (1,0) [0|3] ""  HVESP01
 SG_ HVESP01_HVILcurrentReturnError_6 : 0|2@1+ (1,0) [0|3] ""  HVESP01
 SG_ HVESP01_PosFcContWelded_6 : 14|2@1+ (1,0) [0|3] ""  HVESP01
 SG_ HVESP01_PosFcContStuckOpen_6 : 12|2@1+ (1,0) [0|3] ""  HVESP01
 SG_ HVESP01_NegFcContWelded_6 : 10|2@1+ (1,0) [0|3] ""  HVESP01
 SG_ HVESP01_NegFcContStuckOpen_6 : 8|2@1+ (1,0) [0|3] ""  HVESP01
 SG_ HVESP01_IsospiBreak_6 : 22|2@1+ (1,0) [0|3] ""  HVESP01
 SG_ HVESP01_IsolationIntFault_6 : 20|2@1+ (1,0) [0|3] ""  HVESP01
 SG_ HVESP01_IsolationExtFault_6 : 18|2@1+ (1,0) [0|3] ""  HVESP01
 SG_ HVESP01_pcb_error_6 : 16|2@1+ (1,0) [0|3] ""  HVESP01
 SG_ HVESP01_hall_eff_hi_rang_err_6 : 30|2@1+ (1,0) [0|3] ""  HVESP01
 SG_ HVESP01_brick_volt_sns_open_6 : 28|2@1+ (1,0) [0|3] ""  HVESP01
 SG_ HVESP01_5v_error_6 : 26|2@1+ (1,0) [0|3] ""  HVESP01
 SG_ HVESP01_3_3_hot_error_6 : 24|2@1+ (1,0) [0|3] ""  HVESP01
 SG_ HVESP01_12v_input_error_6 : 38|2@1+ (1,0) [0|3] ""  HVESP01
 SG_ HVESP01_1_25v_error_6 : 36|2@1+ (1,0) [0|3] ""  HVESP01
 SG_ HVESP01_shunt_MIA_6 : 34|2@1+ (1,0) [0|3] ""  HVESP01
 SG_ HVESP01_SBC_int_reg_error_6 : 32|2@1+ (1,0) [0|3] ""  HVESP01
 SG_ HVESP01_pos_3_3v_analog_error_6 : 46|2@1+ (1,0) [0|3] ""  HVESP01
 SG_ HVESP01_outlt_clnt_thrm_open_6 : 44|2@1+ (1,0) [0|3] ""  HVESP01
 SG_ HVESP01_neg_3_3_analog_error_6 : 42|2@1+ (1,0) [0|3] ""  HVESP01
 SG_ HVESP01_inlet_clnt_thrm_open_6 : 40|2@1+ (1,0) [0|3] ""  HVESP01
 SG_ HVESP01_hall_eff_lo_rang_err_6 : 54|2@1+ (1,0) [0|3] ""  HVESP01
 SG_ HVESP01_outlt_clnt_thrm_short_6 : 52|2@1+ (1,0) [0|3] ""  HVESP01
 SG_ HVESP01_inlet_clnt_thrm_short_6 : 50|2@1+ (1,0) [0|3] ""  HVESP01
 SG_ HVESP01_3_3v_error_6 : 48|2@1+ (1,0) [0|3] ""  HVESP01

BO_ 2499745643 HVESP01_DiagnosticPrevC_7: 8 HVESP01
 SG_ HVESP01_PackVoltageImbalance_7 : 58|2@1+ (1,0) [0|3] ""  HVESP01
 SG_ HVESP01_PrechargeoverCurrent_7 : 56|2@1+ (1,0) [0|3] ""  HVESP01
 SG_ HVESP01_HVILvoltageError_7 : 2|2@1+ (1,0) [0|3] ""  HVESP01
 SG_ HVESP01_HVILcurrentReturnError_7 : 0|2@1+ (1,0) [0|3] ""  HVESP01
 SG_ HVESP01_PosFcContWelded_7 : 14|2@1+ (1,0) [0|3] ""  HVESP01
 SG_ HVESP01_PosFcContStuckOpen_7 : 12|2@1+ (1,0) [0|3] ""  HVESP01
 SG_ HVESP01_NegFcContWelded_7 : 10|2@1+ (1,0) [0|3] ""  HVESP01
 SG_ HVESP01_NegFcContStuckOpen_7 : 8|2@1+ (1,0) [0|3] ""  HVESP01
 SG_ HVESP01_IsospiBreak_7 : 22|2@1+ (1,0) [0|3] ""  HVESP01
 SG_ HVESP01_IsolationIntFault_7 : 20|2@1+ (1,0) [0|3] ""  HVESP01
 SG_ HVESP01_IsolationExtFault_7 : 18|2@1+ (1,0) [0|3] ""  HVESP01
 SG_ HVESP01_pcb_error_7 : 16|2@1+ (1,0) [0|3] ""  HVESP01
 SG_ HVESP01_hall_eff_hi_rang_err_7 : 30|2@1+ (1,0) [0|3] ""  HVESP01
 SG_ HVESP01_brick_volt_sns_open_7 : 28|2@1+ (1,0) [0|3] ""  HVESP01
 SG_ HVESP01_5v_error_7 : 26|2@1+ (1,0) [0|3] ""  HVESP01
 SG_ HVESP01_3_3_hot_error_7 : 24|2@1+ (1,0) [0|3] ""  HVESP01
 SG_ HVESP01_12v_input_error_7 : 38|2@1+ (1,0) [0|3] ""  HVESP01
 SG_ HVESP01_1_25v_error_7 : 36|2@1+ (1,0) [0|3] ""  HVESP01
 SG_ HVESP01_shunt_MIA_7 : 34|2@1+ (1,0) [0|3] ""  HVESP01
 SG_ HVESP01_SBC_int_reg_error_7 : 32|2@1+ (1,0) [0|3] ""  HVESP01
 SG_ HVESP01_pos_3_3v_analog_error_7 : 46|2@1+ (1,0) [0|3] ""  HVESP01
 SG_ HVESP01_outlt_clnt_thrm_open_7 : 44|2@1+ (1,0) [0|3] ""  HVESP01
 SG_ HVESP01_neg_3_3_analog_error_7 : 42|2@1+ (1,0) [0|3] ""  HVESP01
 SG_ HVESP01_inlet_clnt_thrm_open_7 : 40|2@1+ (1,0) [0|3] ""  HVESP01
 SG_ HVESP01_hall_eff_lo_rang_err_7 : 54|2@1+ (1,0) [0|3] ""  HVESP01
 SG_ HVESP01_outlt_clnt_thrm_short_7 : 52|2@1+ (1,0) [0|3] ""  HVESP01
 SG_ HVESP01_inlet_clnt_thrm_short_7 : 50|2@1+ (1,0) [0|3] ""  HVESP01
 SG_ HVESP01_3_3v_error_7 : 48|2@1+ (1,0) [0|3] ""  HVESP01

BO_ 2499745644 HVESP01_DiagnosticPrevC_8: 8 HVESP01
 SG_ HVESP01_PackVoltageImbalance_8 : 58|2@1+ (1,0) [0|3] ""  HVESP01
 SG_ HVESP01_PrechargeoverCurrent_8 : 56|2@1+ (1,0) [0|3] ""  HVESP01
 SG_ HVESP01_HVILvoltageError_8 : 2|2@1+ (1,0) [0|3] ""  HVESP01
 SG_ HVESP01_HVILcurrentReturnError_8 : 0|2@1+ (1,0) [0|3] ""  HVESP01
 SG_ HVESP01_PosFcContWelded_8 : 14|2@1+ (1,0) [0|3] ""  HVESP01
 SG_ HVESP01_PosFcContStuckOpen_8 : 12|2@1+ (1,0) [0|3] ""  HVESP01
 SG_ HVESP01_NegFcContWelded_8 : 10|2@1+ (1,0) [0|3] ""  HVESP01
 SG_ HVESP01_NegFcContStuckOpen_8 : 8|2@1+ (1,0) [0|3] ""  HVESP01
 SG_ HVESP01_IsospiBreak_8 : 22|2@1+ (1,0) [0|3] ""  HVESP01
 SG_ HVESP01_IsolationIntFault_8 : 20|2@1+ (1,0) [0|3] ""  HVESP01
 SG_ HVESP01_IsolationExtFault_8 : 18|2@1+ (1,0) [0|3] ""  HVESP01
 SG_ HVESP01_pcb_error_8 : 16|2@1+ (1,0) [0|3] ""  HVESP01
 SG_ HVESP01_hall_eff_hi_rang_err_8 : 30|2@1+ (1,0) [0|3] ""  HVESP01
 SG_ HVESP01_brick_volt_sns_open_8 : 28|2@1+ (1,0) [0|3] ""  HVESP01
 SG_ HVESP01_5v_error_8 : 26|2@1+ (1,0) [0|3] ""  HVESP01
 SG_ HVESP01_3_3_hot_error_8 : 24|2@1+ (1,0) [0|3] ""  HVESP01
 SG_ HVESP01_12v_input_error_8 : 38|2@1+ (1,0) [0|3] ""  HVESP01
 SG_ HVESP01_1_25v_error_8 : 36|2@1+ (1,0) [0|3] ""  HVESP01
 SG_ HVESP01_shunt_MIA_8 : 34|2@1+ (1,0) [0|3] ""  HVESP01
 SG_ HVESP01_SBC_int_reg_error_8 : 32|2@1+ (1,0) [0|3] ""  HVESP01
 SG_ HVESP01_pos_3_3v_analog_error_8 : 46|2@1+ (1,0) [0|3] ""  HVESP01
 SG_ HVESP01_outlt_clnt_thrm_open_8 : 44|2@1+ (1,0) [0|3] ""  HVESP01
 SG_ HVESP01_neg_3_3_analog_error_8 : 42|2@1+ (1,0) [0|3] ""  HVESP01
 SG_ HVESP01_inlet_clnt_thrm_open_8 : 40|2@1+ (1,0) [0|3] ""  HVESP01
 SG_ HVESP01_hall_eff_lo_rang_err_8 : 54|2@1+ (1,0) [0|3] ""  HVESP01
 SG_ HVESP01_outlt_clnt_thrm_short_8 : 52|2@1+ (1,0) [0|3] ""  HVESP01
 SG_ HVESP01_inlet_clnt_thrm_short_8 : 50|2@1+ (1,0) [0|3] ""  HVESP01
 SG_ HVESP01_3_3v_error_8 : 48|2@1+ (1,0) [0|3] ""  HVESP01

BO_ 2499745893 HVESP01_DiagnosticPrevD_1: 8 HVESP01
 SG_ HVESP01_BusJoinFailed_1 : 10|2@1+ (1,0) [0|3] ""  HVESP01
 SG_ HVESP01_ModuleThermFaultSevere_1 : 8|2@1+ (1,0) [0|3] ""  HVESP01
 SG_ HVESP01_Cal2PackMismatch_1 : 22|2@1+ (1,0) [0|3] ""  HVESP01
 SG_ HVESP01_HardwareUvloError_1 : 20|2@1+ (1,0) [0|3] ""  HVESP01
 SG_ HVESP01_iOverchargemod_1 : 46|2@1+ (1,0) [0|3] ""  HVESP01
 SG_ HVESP01_afe_pwr_wire_open_1 : 44|2@1+ (1,0) [0|3] ""  HVESP01
 SG_ HVESP01_HardwareOVError_1 : 18|2@1+ (1,0) [0|3] ""  HVESP01
 SG_ HVESP01_DoubleDcContWeld_1 : 16|2@1+ (1,0) [0|3] ""  HVESP01
 SG_ HVESP01_CurrentMismatch_1 : 30|2@1+ (1,0) [0|3] ""  HVESP01
 SG_ HVESP01_vBrickImbalanceWar_1 : 28|2@1+ (1,0) [0|3] ""  HVESP01
 SG_ HVESP01_vBrickImbalanceMod_1 : 26|2@1+ (1,0) [0|3] ""  HVESP01
 SG_ HVESP01_vBrickImbalanceSev_1 : 24|2@1+ (1,0) [0|3] ""  HVESP01
 SG_ HVESP01_Placeholder06_1 : 38|2@1+ (1,0) [0|3] ""  HVESP01
 SG_ HVESP01_iOverdischargewar_1 : 36|2@1+ (1,0) [0|3] ""  HVESP01
 SG_ HVESP01_SpeakerMia_1 : 2|2@1+ (1,0) [0|3] ""  HVESP01
 SG_ HVESP01_IsoSpiBreak_1 : 0|2@1+ (1,0) [0|3] ""  HVESP01
 SG_ HVESP01_VersionMismatch_1 : 14|2@1+ (1,0) [0|3] ""  HVESP01
 SG_ HVESP01_SystemPrechargeFail_1 : 12|2@1+ (1,0) [0|3] ""  HVESP01
 SG_ HVESP01_iOverdischargemod_1 : 34|2@1+ (1,0) [0|3] ""  HVESP01
 SG_ HVESP01_iOverchargewar_1 : 32|2@1+ (1,0) [0|3] ""  HVESP01

BO_ 2499745894 HVESP01_DiagnosticPrevD_2: 8 HVESP01
 SG_ HVESP01_BusJoinFailed_2 : 10|2@1+ (1,0) [0|3] ""  HVESP01
 SG_ HVESP01_ModuleThermFaultSevere_2 : 8|2@1+ (1,0) [0|3] ""  HVESP01
 SG_ HVESP01_Cal2PackMismatch_2 : 22|2@1+ (1,0) [0|3] ""  HVESP01
 SG_ HVESP01_HardwareUvloError_2 : 20|2@1+ (1,0) [0|3] ""  HVESP01
 SG_ HVESP01_iOverchargemod_2 : 46|2@1+ (1,0) [0|3] ""  HVESP01
 SG_ HVESP01_afe_pwr_wire_open_2 : 44|2@1+ (1,0) [0|3] ""  HVESP01
 SG_ HVESP01_HardwareOVError_2 : 18|2@1+ (1,0) [0|3] ""  HVESP01
 SG_ HVESP01_DoubleDcContWeld_2 : 16|2@1+ (1,0) [0|3] ""  HVESP01
 SG_ HVESP01_CurrentMismatch_2 : 30|2@1+ (1,0) [0|3] ""  HVESP01
 SG_ HVESP01_vBrickImbalanceWar_2 : 28|2@1+ (1,0) [0|3] ""  HVESP01
 SG_ HVESP01_vBrickImbalanceMod_2 : 26|2@1+ (1,0) [0|3] ""  HVESP01
 SG_ HVESP01_vBrickImbalanceSev_2 : 24|2@1+ (1,0) [0|3] ""  HVESP01
 SG_ HVESP01_Placeholder06_2 : 38|2@1+ (1,0) [0|3] ""  HVESP01
 SG_ HVESP01_iOverdischargewar_2 : 36|2@1+ (1,0) [0|3] ""  HVESP01
 SG_ HVESP01_SpeakerMia_2 : 2|2@1+ (1,0) [0|3] ""  HVESP01
 SG_ HVESP01_IsoSpiBreak_2 : 0|2@1+ (1,0) [0|3] ""  HVESP01
 SG_ HVESP01_VersionMismatch_2 : 14|2@1+ (1,0) [0|3] ""  HVESP01
 SG_ HVESP01_SystemPrechargeFail_2 : 12|2@1+ (1,0) [0|3] ""  HVESP01
 SG_ HVESP01_iOverdischargemod_2 : 34|2@1+ (1,0) [0|3] ""  HVESP01
 SG_ HVESP01_iOverchargewar_2 : 32|2@1+ (1,0) [0|3] ""  HVESP01

BO_ 2499745895 HVESP01_DiagnosticPrevD_3: 8 HVESP01
 SG_ HVESP01_BusJoinFailed_3 : 10|2@1+ (1,0) [0|3] ""  HVESP01
 SG_ HVESP01_ModuleThermFaultSevere_3 : 8|2@1+ (1,0) [0|3] ""  HVESP01
 SG_ HVESP01_Cal2PackMismatch_3 : 22|2@1+ (1,0) [0|3] ""  HVESP01
 SG_ HVESP01_HardwareUvloError_3 : 20|2@1+ (1,0) [0|3] ""  HVESP01
 SG_ HVESP01_iOverchargemod_3 : 46|2@1+ (1,0) [0|3] ""  HVESP01
 SG_ HVESP01_afe_pwr_wire_open_3 : 44|2@1+ (1,0) [0|3] ""  HVESP01
 SG_ HVESP01_HardwareOVError_3 : 18|2@1+ (1,0) [0|3] ""  HVESP01
 SG_ HVESP01_DoubleDcContWeld_3 : 16|2@1+ (1,0) [0|3] ""  HVESP01
 SG_ HVESP01_CurrentMismatch_3 : 30|2@1+ (1,0) [0|3] ""  HVESP01
 SG_ HVESP01_vBrickImbalanceWar_3 : 28|2@1+ (1,0) [0|3] ""  HVESP01
 SG_ HVESP01_vBrickImbalanceMod_3 : 26|2@1+ (1,0) [0|3] ""  HVESP01
 SG_ HVESP01_vBrickImbalanceSev_3 : 24|2@1+ (1,0) [0|3] ""  HVESP01
 SG_ HVESP01_Placeholder06_3 : 38|2@1+ (1,0) [0|3] ""  HVESP01
 SG_ HVESP01_iOverdischargewar_3 : 36|2@1+ (1,0) [0|3] ""  HVESP01
 SG_ HVESP01_SpeakerMia_3 : 2|2@1+ (1,0) [0|3] ""  HVESP01
 SG_ HVESP01_IsoSpiBreak_3 : 0|2@1+ (1,0) [0|3] ""  HVESP01
 SG_ HVESP01_VersionMismatch_3 : 14|2@1+ (1,0) [0|3] ""  HVESP01
 SG_ HVESP01_SystemPrechargeFail_3 : 12|2@1+ (1,0) [0|3] ""  HVESP01
 SG_ HVESP01_iOverdischargemod_3 : 34|2@1+ (1,0) [0|3] ""  HVESP01
 SG_ HVESP01_iOverchargewar_3 : 32|2@1+ (1,0) [0|3] ""  HVESP01

BO_ 2499745896 HVESP01_DiagnosticPrevD_4: 8 HVESP01
 SG_ HVESP01_BusJoinFailed_4 : 10|2@1+ (1,0) [0|3] ""  HVESP01
 SG_ HVESP01_ModuleThermFaultSevere_4 : 8|2@1+ (1,0) [0|3] ""  HVESP01
 SG_ HVESP01_Cal2PackMismatch_4 : 22|2@1+ (1,0) [0|3] ""  HVESP01
 SG_ HVESP01_HardwareUvloError_4 : 20|2@1+ (1,0) [0|3] ""  HVESP01
 SG_ HVESP01_iOverchargemod_4 : 46|2@1+ (1,0) [0|3] ""  HVESP01
 SG_ HVESP01_afe_pwr_wire_open_4 : 44|2@1+ (1,0) [0|3] ""  HVESP01
 SG_ HVESP01_HardwareOVError_4 : 18|2@1+ (1,0) [0|3] ""  HVESP01
 SG_ HVESP01_DoubleDcContWeld_4 : 16|2@1+ (1,0) [0|3] ""  HVESP01
 SG_ HVESP01_CurrentMismatch_4 : 30|2@1+ (1,0) [0|3] ""  HVESP01
 SG_ HVESP01_vBrickImbalanceWar_4 : 28|2@1+ (1,0) [0|3] ""  HVESP01
 SG_ HVESP01_vBrickImbalanceMod_4 : 26|2@1+ (1,0) [0|3] ""  HVESP01
 SG_ HVESP01_vBrickImbalanceSev_4 : 24|2@1+ (1,0) [0|3] ""  HVESP01
 SG_ HVESP01_Placeholder06_4 : 38|2@1+ (1,0) [0|3] ""  HVESP01
 SG_ HVESP01_iOverdischargewar_4 : 36|2@1+ (1,0) [0|3] ""  HVESP01
 SG_ HVESP01_SpeakerMia_4 : 2|2@1+ (1,0) [0|3] ""  HVESP01
 SG_ HVESP01_IsoSpiBreak_4 : 0|2@1+ (1,0) [0|3] ""  HVESP01
 SG_ HVESP01_VersionMismatch_4 : 14|2@1+ (1,0) [0|3] ""  HVESP01
 SG_ HVESP01_SystemPrechargeFail_4 : 12|2@1+ (1,0) [0|3] ""  HVESP01
 SG_ HVESP01_iOverdischargemod_4 : 34|2@1+ (1,0) [0|3] ""  HVESP01
 SG_ HVESP01_iOverchargewar_4 : 32|2@1+ (1,0) [0|3] ""  HVESP01

BO_ 2499745897 HVESP01_DiagnosticPrevD_5: 8 HVESP01
 SG_ HVESP01_BusJoinFailed_5 : 10|2@1+ (1,0) [0|3] ""  HVESP01
 SG_ HVESP01_ModuleThermFaultSevere_5 : 8|2@1+ (1,0) [0|3] ""  HVESP01
 SG_ HVESP01_Cal2PackMismatch_5 : 22|2@1+ (1,0) [0|3] ""  HVESP01
 SG_ HVESP01_HardwareUvloError_5 : 20|2@1+ (1,0) [0|3] ""  HVESP01
 SG_ HVESP01_iOverchargemod_5 : 46|2@1+ (1,0) [0|3] ""  HVESP01
 SG_ HVESP01_afe_pwr_wire_open_5 : 44|2@1+ (1,0) [0|3] ""  HVESP01
 SG_ HVESP01_HardwareOVError_5 : 18|2@1+ (1,0) [0|3] ""  HVESP01
 SG_ HVESP01_DoubleDcContWeld_5 : 16|2@1+ (1,0) [0|3] ""  HVESP01
 SG_ HVESP01_CurrentMismatch_5 : 30|2@1+ (1,0) [0|3] ""  HVESP01
 SG_ HVESP01_vBrickImbalanceWar_5 : 28|2@1+ (1,0) [0|3] ""  HVESP01
 SG_ HVESP01_vBrickImbalanceMod_5 : 26|2@1+ (1,0) [0|3] ""  HVESP01
 SG_ HVESP01_vBrickImbalanceSev_5 : 24|2@1+ (1,0) [0|3] ""  HVESP01
 SG_ HVESP01_Placeholder06_5 : 38|2@1+ (1,0) [0|3] ""  HVESP01
 SG_ HVESP01_iOverdischargewar_5 : 36|2@1+ (1,0) [0|3] ""  HVESP01
 SG_ HVESP01_SpeakerMia_5 : 2|2@1+ (1,0) [0|3] ""  HVESP01
 SG_ HVESP01_IsoSpiBreak_5 : 0|2@1+ (1,0) [0|3] ""  HVESP01
 SG_ HVESP01_VersionMismatch_5 : 14|2@1+ (1,0) [0|3] ""  HVESP01
 SG_ HVESP01_SystemPrechargeFail_5 : 12|2@1+ (1,0) [0|3] ""  HVESP01
 SG_ HVESP01_iOverdischargemod_5 : 34|2@1+ (1,0) [0|3] ""  HVESP01
 SG_ HVESP01_iOverchargewar_5 : 32|2@1+ (1,0) [0|3] ""  HVESP01

BO_ 2499745898 HVESP01_DiagnosticPrevD_6: 8 HVESP01
 SG_ HVESP01_BusJoinFailed_6 : 10|2@1+ (1,0) [0|3] ""  HVESP01
 SG_ HVESP01_ModuleThermFaultSevere_6 : 8|2@1+ (1,0) [0|3] ""  HVESP01
 SG_ HVESP01_Cal2PackMismatch_6 : 22|2@1+ (1,0) [0|3] ""  HVESP01
 SG_ HVESP01_HardwareUvloError_6 : 20|2@1+ (1,0) [0|3] ""  HVESP01
 SG_ HVESP01_iOverchargemod_6 : 46|2@1+ (1,0) [0|3] ""  HVESP01
 SG_ HVESP01_afe_pwr_wire_open_6 : 44|2@1+ (1,0) [0|3] ""  HVESP01
 SG_ HVESP01_HardwareOVError_6 : 18|2@1+ (1,0) [0|3] ""  HVESP01
 SG_ HVESP01_DoubleDcContWeld_6 : 16|2@1+ (1,0) [0|3] ""  HVESP01
 SG_ HVESP01_CurrentMismatch_6 : 30|2@1+ (1,0) [0|3] ""  HVESP01
 SG_ HVESP01_vBrickImbalanceWar_6 : 28|2@1+ (1,0) [0|3] ""  HVESP01
 SG_ HVESP01_vBrickImbalanceMod_6 : 26|2@1+ (1,0) [0|3] ""  HVESP01
 SG_ HVESP01_vBrickImbalanceSev_6 : 24|2@1+ (1,0) [0|3] ""  HVESP01
 SG_ HVESP01_Placeholder06_6 : 38|2@1+ (1,0) [0|3] ""  HVESP01
 SG_ HVESP01_iOverdischargewar_6 : 36|2@1+ (1,0) [0|3] ""  HVESP01
 SG_ HVESP01_SpeakerMia_6 : 2|2@1+ (1,0) [0|3] ""  HVESP01
 SG_ HVESP01_IsoSpiBreak_6 : 0|2@1+ (1,0) [0|3] ""  HVESP01
 SG_ HVESP01_VersionMismatch_6 : 14|2@1+ (1,0) [0|3] ""  HVESP01
 SG_ HVESP01_SystemPrechargeFail_6 : 12|2@1+ (1,0) [0|3] ""  HVESP01
 SG_ HVESP01_iOverdischargemod_6 : 34|2@1+ (1,0) [0|3] ""  HVESP01
 SG_ HVESP01_iOverchargewar_6 : 32|2@1+ (1,0) [0|3] ""  HVESP01

BO_ 2499745899 HVESP01_DiagnosticPrevD_7: 8 HVESP01
 SG_ HVESP01_BusJoinFailed_7 : 10|2@1+ (1,0) [0|3] ""  HVESP01
 SG_ HVESP01_ModuleThermFaultSevere_7 : 8|2@1+ (1,0) [0|3] ""  HVESP01
 SG_ HVESP01_Cal2PackMismatch_7 : 22|2@1+ (1,0) [0|3] ""  HVESP01
 SG_ HVESP01_HardwareUvloError_7 : 20|2@1+ (1,0) [0|3] ""  HVESP01
 SG_ HVESP01_iOverchargemod_7 : 46|2@1+ (1,0) [0|3] ""  HVESP01
 SG_ HVESP01_afe_pwr_wire_open_7 : 44|2@1+ (1,0) [0|3] ""  HVESP01
 SG_ HVESP01_HardwareOVError_7 : 18|2@1+ (1,0) [0|3] ""  HVESP01
 SG_ HVESP01_DoubleDcContWeld_7 : 16|2@1+ (1,0) [0|3] ""  HVESP01
 SG_ HVESP01_CurrentMismatch_7 : 30|2@1+ (1,0) [0|3] ""  HVESP01
 SG_ HVESP01_vBrickImbalanceWar_7 : 28|2@1+ (1,0) [0|3] ""  HVESP01
 SG_ HVESP01_vBrickImbalanceMod_7 : 26|2@1+ (1,0) [0|3] ""  HVESP01
 SG_ HVESP01_vBrickImbalanceSev_7 : 24|2@1+ (1,0) [0|3] ""  HVESP01
 SG_ HVESP01_Placeholder06_7 : 38|2@1+ (1,0) [0|3] ""  HVESP01
 SG_ HVESP01_iOverdischargewar_7 : 36|2@1+ (1,0) [0|3] ""  HVESP01
 SG_ HVESP01_SpeakerMia_7 : 2|2@1+ (1,0) [0|3] ""  HVESP01
 SG_ HVESP01_IsoSpiBreak_7 : 0|2@1+ (1,0) [0|3] ""  HVESP01
 SG_ HVESP01_VersionMismatch_7 : 14|2@1+ (1,0) [0|3] ""  HVESP01
 SG_ HVESP01_SystemPrechargeFail_7 : 12|2@1+ (1,0) [0|3] ""  HVESP01
 SG_ HVESP01_iOverdischargemod_7 : 34|2@1+ (1,0) [0|3] ""  HVESP01
 SG_ HVESP01_iOverchargewar_7 : 32|2@1+ (1,0) [0|3] ""  HVESP01

BO_ 2499745900 HVESP01_DiagnosticPrevD_8: 8 HVESP01
 SG_ HVESP01_BusJoinFailed_8 : 10|2@1+ (1,0) [0|3] ""  HVESP01
 SG_ HVESP01_ModuleThermFaultSevere_8 : 8|2@1+ (1,0) [0|3] ""  HVESP01
 SG_ HVESP01_Cal2PackMismatch_8 : 22|2@1+ (1,0) [0|3] ""  HVESP01
 SG_ HVESP01_HardwareUvloError_8 : 20|2@1+ (1,0) [0|3] ""  HVESP01
 SG_ HVESP01_iOverchargemod_8 : 46|2@1+ (1,0) [0|3] ""  HVESP01
 SG_ HVESP01_afe_pwr_wire_open_8 : 44|2@1+ (1,0) [0|3] ""  HVESP01
 SG_ HVESP01_HardwareOVError_8 : 18|2@1+ (1,0) [0|3] ""  HVESP01
 SG_ HVESP01_DoubleDcContWeld_8 : 16|2@1+ (1,0) [0|3] ""  HVESP01
 SG_ HVESP01_CurrentMismatch_8 : 30|2@1+ (1,0) [0|3] ""  HVESP01
 SG_ HVESP01_vBrickImbalanceWar_8 : 28|2@1+ (1,0) [0|3] ""  HVESP01
 SG_ HVESP01_vBrickImbalanceMod_8 : 26|2@1+ (1,0) [0|3] ""  HVESP01
 SG_ HVESP01_vBrickImbalanceSev_8 : 24|2@1+ (1,0) [0|3] ""  HVESP01
 SG_ HVESP01_Placeholder06_8 : 38|2@1+ (1,0) [0|3] ""  HVESP01
 SG_ HVESP01_iOverdischargewar_8 : 36|2@1+ (1,0) [0|3] ""  HVESP01
 SG_ HVESP01_SpeakerMia_8 : 2|2@1+ (1,0) [0|3] ""  HVESP01
 SG_ HVESP01_IsoSpiBreak_8 : 0|2@1+ (1,0) [0|3] ""  HVESP01
 SG_ HVESP01_VersionMismatch_8 : 14|2@1+ (1,0) [0|3] ""  HVESP01
 SG_ HVESP01_SystemPrechargeFail_8 : 12|2@1+ (1,0) [0|3] ""  HVESP01
 SG_ HVESP01_iOverdischargemod_8 : 34|2@1+ (1,0) [0|3] ""  HVESP01
 SG_ HVESP01_iOverchargewar_8 : 32|2@1+ (1,0) [0|3] ""  HVESP01

BO_ 2499746149 HVESP01_Current_1: 8 HVESP01
 SG_ HVESP01_currentSecondary_1 : 0|22@1+ (0.001,-1600) [-1600|1600] "A"  HVESP01
 SG_ HVESP01_currentPrimary_1 : 40|22@1+ (0.001,-1600) [-1600|1600] "A"  HVESP01

BO_ 2499746150 HVESP01_Current_2: 8 HVESP01
 SG_ HVESP01_currentSecondary_2 : 0|22@1+ (0.001,-1600) [-1600|1600] "A"  HVESP01
 SG_ HVESP01_currentPrimary_2 : 40|22@1+ (0.001,-1600) [-1600|1600] "A"  HVESP01

BO_ 2499746151 HVESP01_Current_3: 8 HVESP01
 SG_ HVESP01_currentSecondary_3 : 0|22@1+ (0.001,-1600) [-1600|1600] "A"  HVESP01
 SG_ HVESP01_currentPrimary_3 : 40|22@1+ (0.001,-1600) [-1600|1600] "A"  HVESP01

BO_ 2499746152 HVESP01_Current_4: 8 HVESP01
 SG_ HVESP01_currentSecondary_4 : 0|22@1+ (0.001,-1600) [-1600|1600] "A"  HVESP01
 SG_ HVESP01_currentPrimary_4 : 40|22@1+ (0.001,-1600) [-1600|1600] "A"  HVESP01

BO_ 2499746153 HVESP01_Current_5: 8 HVESP01
 SG_ HVESP01_currentSecondary_5 : 0|22@1+ (0.001,-1600) [-1600|1600] "A"  HVESP01
 SG_ HVESP01_currentPrimary_5 : 40|22@1+ (0.001,-1600) [-1600|1600] "A"  HVESP01

BO_ 2499746154 HVESP01_Current_6: 8 HVESP01
 SG_ HVESP01_currentSecondary_6 : 0|22@1+ (0.001,-1600) [-1600|1600] "A"  HVESP01
 SG_ HVESP01_currentPrimary_6 : 40|22@1+ (0.001,-1600) [-1600|1600] "A"  HVESP01

BO_ 2499746155 HVESP01_Current_7: 8 HVESP01
 SG_ HVESP01_currentSecondary_7 : 0|22@1+ (0.001,-1600) [-1600|1600] "A"  HVESP01
 SG_ HVESP01_currentPrimary_7 : 40|22@1+ (0.001,-1600) [-1600|1600] "A"  HVESP01

BO_ 2499746156 HVESP01_Current_8: 8 HVESP01
 SG_ HVESP01_currentSecondary_8 : 0|22@1+ (0.001,-1600) [-1600|1600] "A"  HVESP01
 SG_ HVESP01_currentPrimary_8 : 40|22@1+ (0.001,-1600) [-1600|1600] "A"  HVESP01

BO_ 2499747941 HVESP01_VoltageDiag_1: 8 HVESP01
 SG_ HVESP01_diagVPackPos_1 : 16|16@1+ (0.02,0) [0|1310.7] "v"  HVESP01
 SG_ HVESP01_diagVPackNeg_1 : 0|16@1+ (0.02,0) [0|1310.7] "v"  HVESP01
 SG_ HVESP01_diagVLoadNeg_1 : 32|16@1+ (0.02,0) [0|1310.7] "v"  HVESP01
 SG_ HVESP01_diagVLoadPos_1 : 48|16@1+ (0.02,0) [0|1310.7] "v"  HVESP01

BO_ 2499747942 HVESP01_VoltageDiag_2: 8 HVESP01
 SG_ HVESP01_diagVPackPos_2 : 16|16@1+ (0.02,0) [0|1310.7] "v"  HVESP01
 SG_ HVESP01_diagVPackNeg_2 : 0|16@1+ (0.02,0) [0|1310.7] "v"  HVESP01
 SG_ HVESP01_diagVLoadNeg_2 : 32|16@1+ (0.02,0) [0|1310.7] "v"  HVESP01
 SG_ HVESP01_diagVLoadPos_2 : 48|16@1+ (0.02,0) [0|1310.7] "v"  HVESP01

BO_ 2499747943 HVESP01_VoltageDiag_3: 8 HVESP01
 SG_ HVESP01_diagVPackPos_3 : 16|16@1+ (0.02,0) [0|1310.7] "v"  HVESP01
 SG_ HVESP01_diagVPackNeg_3 : 0|16@1+ (0.02,0) [0|1310.7] "v"  HVESP01
 SG_ HVESP01_diagVLoadNeg_3 : 32|16@1+ (0.02,0) [0|1310.7] "v"  HVESP01
 SG_ HVESP01_diagVLoadPos_3 : 48|16@1+ (0.02,0) [0|1310.7] "v"  HVESP01

BO_ 2499747944 HVESP01_VoltageDiag_4: 8 HVESP01
 SG_ HVESP01_diagVPackPos_4 : 16|16@1+ (0.02,0) [0|1310.7] "v"  HVESP01
 SG_ HVESP01_diagVPackNeg_4 : 0|16@1+ (0.02,0) [0|1310.7] "v"  HVESP01
 SG_ HVESP01_diagVLoadNeg_4 : 32|16@1+ (0.02,0) [0|1310.7] "v"  HVESP01
 SG_ HVESP01_diagVLoadPos_4 : 48|16@1+ (0.02,0) [0|1310.7] "v"  HVESP01

BO_ 2499747945 HVESP01_VoltageDiag_5: 8 HVESP01
 SG_ HVESP01_diagVPackPos_5 : 16|16@1+ (0.02,0) [0|1310.7] "v"  HVESP01
 SG_ HVESP01_diagVPackNeg_5 : 0|16@1+ (0.02,0) [0|1310.7] "v"  HVESP01
 SG_ HVESP01_diagVLoadNeg_5 : 32|16@1+ (0.02,0) [0|1310.7] "v"  HVESP01
 SG_ HVESP01_diagVLoadPos_5 : 48|16@1+ (0.02,0) [0|1310.7] "v"  HVESP01

BO_ 2499747946 HVESP01_VoltageDiag_6: 8 HVESP01
 SG_ HVESP01_diagVPackPos_6 : 16|16@1+ (0.02,0) [0|1310.7] "v"  HVESP01
 SG_ HVESP01_diagVPackNeg_6 : 0|16@1+ (0.02,0) [0|1310.7] "v"  HVESP01
 SG_ HVESP01_diagVLoadNeg_6 : 32|16@1+ (0.02,0) [0|1310.7] "v"  HVESP01
 SG_ HVESP01_diagVLoadPos_6 : 48|16@1+ (0.02,0) [0|1310.7] "v"  HVESP01

BO_ 2499747947 HVESP01_VoltageDiag_7: 8 HVESP01
 SG_ HVESP01_diagVPackPos_7 : 16|16@1+ (0.02,0) [0|1310.7] "v"  HVESP01
 SG_ HVESP01_diagVPackNeg_7 : 0|16@1+ (0.02,0) [0|1310.7] "v"  HVESP01
 SG_ HVESP01_diagVLoadNeg_7 : 32|16@1+ (0.02,0) [0|1310.7] "v"  HVESP01
 SG_ HVESP01_diagVLoadPos_7 : 48|16@1+ (0.02,0) [0|1310.7] "v"  HVESP01

BO_ 2499747948 HVESP01_VoltageDiag_8: 8 HVESP01
 SG_ HVESP01_diagVPackPos_8 : 16|16@1+ (0.02,0) [0|1310.7] "v"  HVESP01
 SG_ HVESP01_diagVPackNeg_8 : 0|16@1+ (0.02,0) [0|1310.7] "v"  HVESP01
 SG_ HVESP01_diagVLoadNeg_8 : 32|16@1+ (0.02,0) [0|1310.7] "v"  HVESP01
 SG_ HVESP01_diagVLoadPos_8 : 48|16@1+ (0.02,0) [0|1310.7] "v"  HVESP01

BO_ 2499748197 HVESP01_BMSDiag_1: 8 HVESP01
 SG_ HVESP01_LV_InputVoltage_1 : 48|16@1+ (0.01,0) [0|35] "V"  HVESP01
 SG_ HVESP01_pyroCheckResult_1 : 0|16@1+ (0.001,0) [0|30] "V"  HVESP01
 SG_ HVESP01_dc_pos_cntr_coil_1 : 16|16@1+ (0.01,0) [0|655] "V"  HVESP01
 SG_ HVESP01_dc_neg_cntr_coil_1 : 32|16@1+ (0.01,0) [0|655] "V"  HVESP01

BO_ 2499748198 HVESP01_BMSDiag_2: 8 HVESP01
 SG_ HVESP01_LV_InputVoltage_2 : 48|16@1+ (0.01,0) [0|35] "V"  HVESP01
 SG_ HVESP01_pyroCheckResult_2 : 0|16@1+ (0.001,0) [0|30] "V"  HVESP01
 SG_ HVESP01_dc_pos_cntr_coil_2 : 16|16@1+ (0.01,0) [0|655] "V"  HVESP01
 SG_ HVESP01_dc_neg_cntr_coil_2 : 32|16@1+ (0.01,0) [0|655] "V"  HVESP01

BO_ 2499748199 HVESP01_BMSDiag_3: 8 HVESP01
 SG_ HVESP01_LV_InputVoltage_3 : 48|16@1+ (0.01,0) [0|35] "V"  HVESP01
 SG_ HVESP01_pyroCheckResult_3 : 0|16@1+ (0.001,0) [0|30] "V"  HVESP01
 SG_ HVESP01_dc_pos_cntr_coil_3 : 16|16@1+ (0.01,0) [0|655] "V"  HVESP01
 SG_ HVESP01_dc_neg_cntr_coil_3 : 32|16@1+ (0.01,0) [0|655] "V"  HVESP01

BO_ 2499748200 HVESP01_BMSDiag_4: 8 HVESP01
 SG_ HVESP01_LV_InputVoltage_4 : 48|16@1+ (0.01,0) [0|35] "V"  HVESP01
 SG_ HVESP01_pyroCheckResult_4 : 0|16@1+ (0.001,0) [0|30] "V"  HVESP01
 SG_ HVESP01_dc_pos_cntr_coil_4 : 16|16@1+ (0.01,0) [0|655] "V"  HVESP01
 SG_ HVESP01_dc_neg_cntr_coil_4 : 32|16@1+ (0.01,0) [0|655] "V"  HVESP01

BO_ 2499748201 HVESP01_BMSDiag_5: 8 HVESP01
 SG_ HVESP01_LV_InputVoltage_5 : 48|16@1+ (0.01,0) [0|35] "V"  HVESP01
 SG_ HVESP01_pyroCheckResult_5 : 0|16@1+ (0.001,0) [0|30] "V"  HVESP01
 SG_ HVESP01_dc_pos_cntr_coil_5 : 16|16@1+ (0.01,0) [0|655] "V"  HVESP01
 SG_ HVESP01_dc_neg_cntr_coil_5 : 32|16@1+ (0.01,0) [0|655] "V"  HVESP01

BO_ 2499748202 HVESP01_BMSDiag_6: 8 HVESP01
 SG_ HVESP01_LV_InputVoltage_6 : 48|16@1+ (0.01,0) [0|35] "V"  HVESP01
 SG_ HVESP01_pyroCheckResult_6 : 0|16@1+ (0.001,0) [0|30] "V"  HVESP01
 SG_ HVESP01_dc_pos_cntr_coil_6 : 16|16@1+ (0.01,0) [0|655] "V"  HVESP01
 SG_ HVESP01_dc_neg_cntr_coil_6 : 32|16@1+ (0.01,0) [0|655] "V"  HVESP01

BO_ 2499748203 HVESP01_BMSDiag_7: 8 HVESP01
 SG_ HVESP01_LV_InputVoltage_7 : 48|16@1+ (0.01,0) [0|35] "V"  HVESP01
 SG_ HVESP01_pyroCheckResult_7 : 0|16@1+ (0.001,0) [0|30] "V"  HVESP01
 SG_ HVESP01_dc_pos_cntr_coil_7 : 16|16@1+ (0.01,0) [0|655] "V"  HVESP01
 SG_ HVESP01_dc_neg_cntr_coil_7 : 32|16@1+ (0.01,0) [0|655] "V"  HVESP01

BO_ 2499748204 HVESP01_BMSDiag_8: 8 HVESP01
 SG_ HVESP01_LV_InputVoltage_8 : 48|16@1+ (0.01,0) [0|35] "V"  HVESP01
 SG_ HVESP01_pyroCheckResult_8 : 0|16@1+ (0.001,0) [0|30] "V"  HVESP01
 SG_ HVESP01_dc_pos_cntr_coil_8 : 16|16@1+ (0.01,0) [0|655] "V"  HVESP01
 SG_ HVESP01_dc_neg_cntr_coil_8 : 32|16@1+ (0.01,0) [0|655] "V"  HVESP01

BO_ 2499748453 HVESP01_SleepWake_1: 8 HVESP01
 SG_ HVESP01_timeAsleepSec_1 : 32|32@1+ (1,0) [0|4294967295] "seconds"  HVESP01
 SG_ HVESP01_timeAwakeSec_1 : 0|32@1+ (1,0) [0|4294967295] "seconds"  HVESP01

BO_ 2499748454 HVESP01_SleepWake_2: 8 HVESP01
 SG_ HVESP01_timeAsleepSec_2 : 32|32@1+ (1,0) [0|4294967295] "seconds"  HVESP01
 SG_ HVESP01_timeAwakeSec_2 : 0|32@1+ (1,0) [0|4294967295] "seconds"  HVESP01

BO_ 2499748455 HVESP01_SleepWake_3: 8 HVESP01
 SG_ HVESP01_timeAsleepSec_3 : 32|32@1+ (1,0) [0|4294967295] "seconds"  HVESP01
 SG_ HVESP01_timeAwakeSec_3 : 0|32@1+ (1,0) [0|4294967295] "seconds"  HVESP01

BO_ 2499748456 HVESP01_SleepWake_4: 8 HVESP01
 SG_ HVESP01_timeAsleepSec_4 : 32|32@1+ (1,0) [0|4294967295] "seconds"  HVESP01
 SG_ HVESP01_timeAwakeSec_4 : 0|32@1+ (1,0) [0|4294967295] "seconds"  HVESP01

BO_ 2499748457 HVESP01_SleepWake_5: 8 HVESP01
 SG_ HVESP01_timeAsleepSec_5 : 32|32@1+ (1,0) [0|4294967295] "seconds"  HVESP01
 SG_ HVESP01_timeAwakeSec_5 : 0|32@1+ (1,0) [0|4294967295] "seconds"  HVESP01

BO_ 2499748458 HVESP01_SleepWake_6: 8 HVESP01
 SG_ HVESP01_timeAsleepSec_6 : 32|32@1+ (1,0) [0|4294967295] "seconds"  HVESP01
 SG_ HVESP01_timeAwakeSec_6 : 0|32@1+ (1,0) [0|4294967295] "seconds"  HVESP01

BO_ 2499748459 HVESP01_SleepWake_7: 8 HVESP01
 SG_ HVESP01_timeAsleepSec_7 : 32|32@1+ (1,0) [0|4294967295] "seconds"  HVESP01
 SG_ HVESP01_timeAwakeSec_7 : 0|32@1+ (1,0) [0|4294967295] "seconds"  HVESP01

BO_ 2499748460 HVESP01_SleepWake_8: 8 HVESP01
 SG_ HVESP01_timeAsleepSec_8 : 32|32@1+ (1,0) [0|4294967295] "seconds"  HVESP01
 SG_ HVESP01_timeAwakeSec_8 : 0|32@1+ (1,0) [0|4294967295] "seconds"  HVESP01

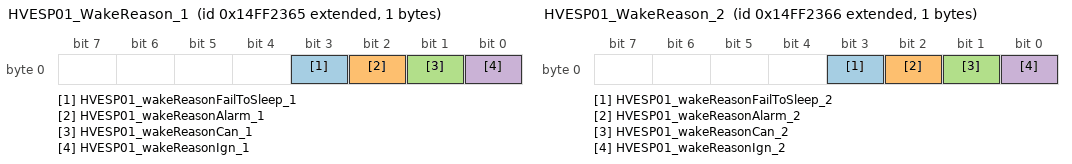
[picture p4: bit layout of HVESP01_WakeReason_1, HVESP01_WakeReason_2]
BO_ 2499748709 HVESP01_WakeReason_1: 1 HVESP01
 SG_ HVESP01_wakeReasonFailToSleep_1 : 3|1@1+ (1,0) [0|1] ""  HVESP01
 SG_ HVESP01_wakeReasonAlarm_1 : 2|1@1+ (1,0) [0|1] ""  HVESP01
 SG_ HVESP01_wakeReasonCan_1 : 1|1@1+ (1,0) [0|1] ""  HVESP01
 SG_ HVESP01_wakeReasonIgn_1 : 0|1@1+ (1,0) [0|1] ""  HVESP01

BO_ 2499748710 HVESP01_WakeReason_2: 1 HVESP01
 SG_ HVESP01_wakeReasonFailToSleep_2 : 3|1@1+ (1,0) [0|1] ""  HVESP01
 SG_ HVESP01_wakeReasonAlarm_2 : 2|1@1+ (1,0) [0|1] ""  HVESP01
 SG_ HVESP01_wakeReasonCan_2 : 1|1@1+ (1,0) [0|1] ""  HVESP01
 SG_ HVESP01_wakeReasonIgn_2 : 0|1@1+ (1,0) [0|1] ""  HVESP01

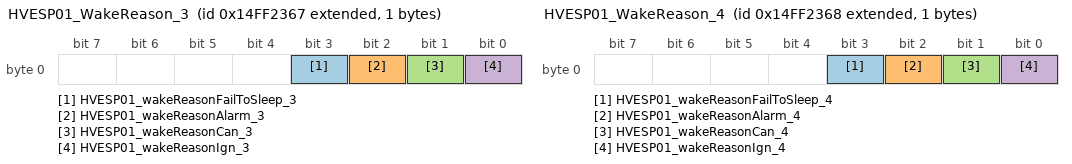
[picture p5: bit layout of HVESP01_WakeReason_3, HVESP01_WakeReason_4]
BO_ 2499748711 HVESP01_WakeReason_3: 1 HVESP01
 SG_ HVESP01_wakeReasonFailToSleep_3 : 3|1@1+ (1,0) [0|1] ""  HVESP01
 SG_ HVESP01_wakeReasonAlarm_3 : 2|1@1+ (1,0) [0|1] ""  HVESP01
 SG_ HVESP01_wakeReasonCan_3 : 1|1@1+ (1,0) [0|1] ""  HVESP01
 SG_ HVESP01_wakeReasonIgn_3 : 0|1@1+ (1,0) [0|1] ""  HVESP01

BO_ 2499748712 HVESP01_WakeReason_4: 1 HVESP01
 SG_ HVESP01_wakeReasonFailToSleep_4 : 3|1@1+ (1,0) [0|1] ""  HVESP01
 SG_ HVESP01_wakeReasonAlarm_4 : 2|1@1+ (1,0) [0|1] ""  HVESP01
 SG_ HVESP01_wakeReasonCan_4 : 1|1@1+ (1,0) [0|1] ""  HVESP01
 SG_ HVESP01_wakeReasonIgn_4 : 0|1@1+ (1,0) [0|1] ""  HVESP01

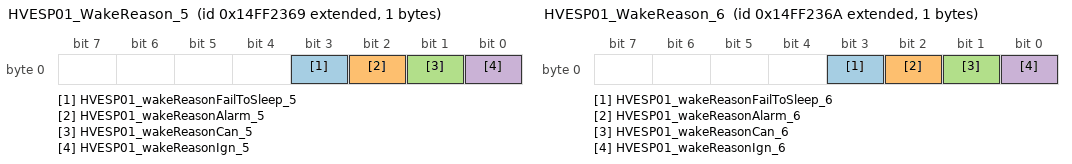
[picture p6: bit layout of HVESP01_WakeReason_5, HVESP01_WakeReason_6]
BO_ 2499748713 HVESP01_WakeReason_5: 1 HVESP01
 SG_ HVESP01_wakeReasonFailToSleep_5 : 3|1@1+ (1,0) [0|1] ""  HVESP01
 SG_ HVESP01_wakeReasonAlarm_5 : 2|1@1+ (1,0) [0|1] ""  HVESP01
 SG_ HVESP01_wakeReasonCan_5 : 1|1@1+ (1,0) [0|1] ""  HVESP01
 SG_ HVESP01_wakeReasonIgn_5 : 0|1@1+ (1,0) [0|1] ""  HVESP01

BO_ 2499748714 HVESP01_WakeReason_6: 1 HVESP01
 SG_ HVESP01_wakeReasonFailToSleep_6 : 3|1@1+ (1,0) [0|1] ""  HVESP01
 SG_ HVESP01_wakeReasonAlarm_6 : 2|1@1+ (1,0) [0|1] ""  HVESP01
 SG_ HVESP01_wakeReasonCan_6 : 1|1@1+ (1,0) [0|1] ""  HVESP01
 SG_ HVESP01_wakeReasonIgn_6 : 0|1@1+ (1,0) [0|1] ""  HVESP01

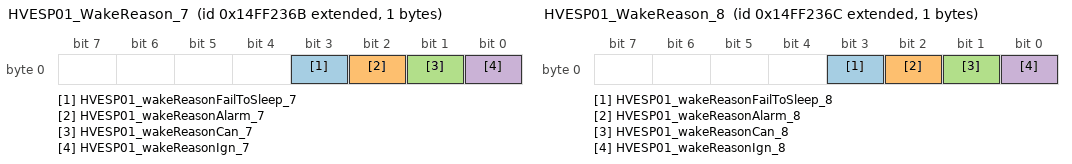
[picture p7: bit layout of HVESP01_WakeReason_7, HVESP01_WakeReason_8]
BO_ 2499748715 HVESP01_WakeReason_7: 1 HVESP01
 SG_ HVESP01_wakeReasonFailToSleep_7 : 3|1@1+ (1,0) [0|1] ""  HVESP01
 SG_ HVESP01_wakeReasonAlarm_7 : 2|1@1+ (1,0) [0|1] ""  HVESP01
 SG_ HVESP01_wakeReasonCan_7 : 1|1@1+ (1,0) [0|1] ""  HVESP01
 SG_ HVESP01_wakeReasonIgn_7 : 0|1@1+ (1,0) [0|1] ""  HVESP01

BO_ 2499748716 HVESP01_WakeReason_8: 1 HVESP01
 SG_ HVESP01_wakeReasonFailToSleep_8 : 3|1@1+ (1,0) [0|1] ""  HVESP01
 SG_ HVESP01_wakeReasonAlarm_8 : 2|1@1+ (1,0) [0|1] ""  HVESP01
 SG_ HVESP01_wakeReasonCan_8 : 1|1@1+ (1,0) [0|1] ""  HVESP01
 SG_ HVESP01_wakeReasonIgn_8 : 0|1@1+ (1,0) [0|1] ""  HVESP01

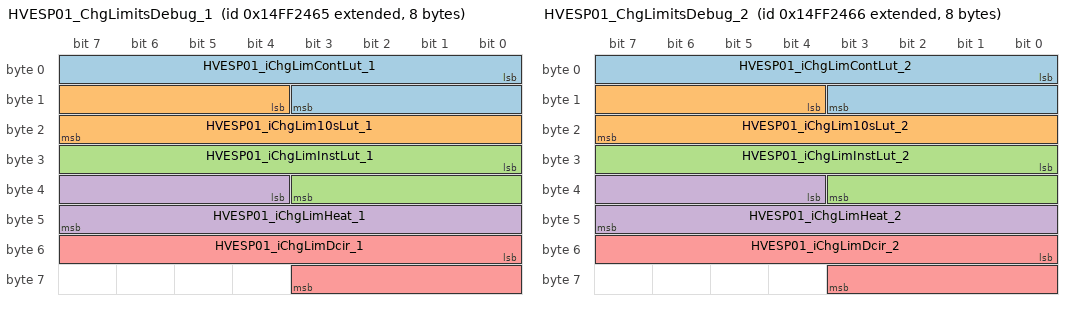
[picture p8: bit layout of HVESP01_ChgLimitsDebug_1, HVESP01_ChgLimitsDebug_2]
BO_ 2499748965 HVESP01_ChgLimitsDebug_1: 8 HVESP01
 SG_ HVESP01_iChgLimContLut_1 : 0|12@1+ (1,0) [0|4095] "A"  HVESP01
 SG_ HVESP01_iChgLim10sLut_1 : 12|12@1+ (1,0) [0|4095] "A"  HVESP01
 SG_ HVESP01_iChgLimInstLut_1 : 24|12@1+ (1,0) [0|4095] "A"  HVESP01
 SG_ HVESP01_iChgLimHeat_1 : 36|12@1+ (1,0) [0|4095] "A"  HVESP01
 SG_ HVESP01_iChgLimDcir_1 : 48|12@1+ (1,0) [0|4095] "A"  HVESP01

BO_ 2499748966 HVESP01_ChgLimitsDebug_2: 8 HVESP01
 SG_ HVESP01_iChgLimContLut_2 : 0|12@1+ (1,0) [0|4095] "A"  HVESP01
 SG_ HVESP01_iChgLim10sLut_2 : 12|12@1+ (1,0) [0|4095] "A"  HVESP01
 SG_ HVESP01_iChgLimInstLut_2 : 24|12@1+ (1,0) [0|4095] "A"  HVESP01
 SG_ HVESP01_iChgLimHeat_2 : 36|12@1+ (1,0) [0|4095] "A"  HVESP01
 SG_ HVESP01_iChgLimDcir_2 : 48|12@1+ (1,0) [0|4095] "A"  HVESP01

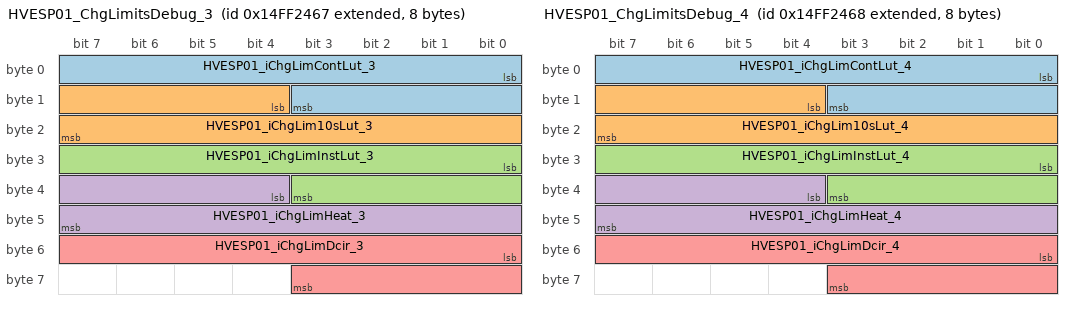
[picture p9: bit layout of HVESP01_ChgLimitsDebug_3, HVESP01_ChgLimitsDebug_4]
BO_ 2499748967 HVESP01_ChgLimitsDebug_3: 8 HVESP01
 SG_ HVESP01_iChgLimContLut_3 : 0|12@1+ (1,0) [0|4095] "A"  HVESP01
 SG_ HVESP01_iChgLim10sLut_3 : 12|12@1+ (1,0) [0|4095] "A"  HVESP01
 SG_ HVESP01_iChgLimInstLut_3 : 24|12@1+ (1,0) [0|4095] "A"  HVESP01
 SG_ HVESP01_iChgLimHeat_3 : 36|12@1+ (1,0) [0|4095] "A"  HVESP01
 SG_ HVESP01_iChgLimDcir_3 : 48|12@1+ (1,0) [0|4095] "A"  HVESP01

BO_ 2499748968 HVESP01_ChgLimitsDebug_4: 8 HVESP01
 SG_ HVESP01_iChgLimContLut_4 : 0|12@1+ (1,0) [0|4095] "A"  HVESP01
 SG_ HVESP01_iChgLim10sLut_4 : 12|12@1+ (1,0) [0|4095] "A"  HVESP01
 SG_ HVESP01_iChgLimInstLut_4 : 24|12@1+ (1,0) [0|4095] "A"  HVESP01
 SG_ HVESP01_iChgLimHeat_4 : 36|12@1+ (1,0) [0|4095] "A"  HVESP01
 SG_ HVESP01_iChgLimDcir_4 : 48|12@1+ (1,0) [0|4095] "A"  HVESP01

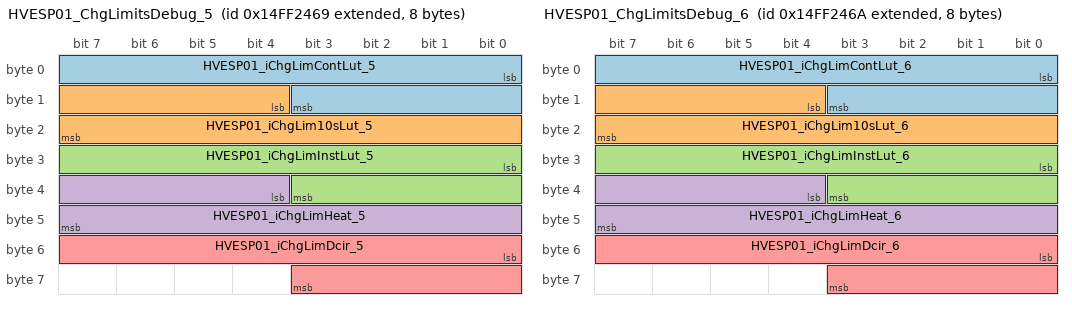
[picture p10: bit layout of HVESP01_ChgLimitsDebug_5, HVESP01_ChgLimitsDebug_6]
BO_ 2499748969 HVESP01_ChgLimitsDebug_5: 8 HVESP01
 SG_ HVESP01_iChgLimContLut_5 : 0|12@1+ (1,0) [0|4095] "A"  HVESP01
 SG_ HVESP01_iChgLim10sLut_5 : 12|12@1+ (1,0) [0|4095] "A"  HVESP01
 SG_ HVESP01_iChgLimInstLut_5 : 24|12@1+ (1,0) [0|4095] "A"  HVESP01
 SG_ HVESP01_iChgLimHeat_5 : 36|12@1+ (1,0) [0|4095] "A"  HVESP01
 SG_ HVESP01_iChgLimDcir_5 : 48|12@1+ (1,0) [0|4095] "A"  HVESP01

BO_ 2499748970 HVESP01_ChgLimitsDebug_6: 8 HVESP01
 SG_ HVESP01_iChgLimContLut_6 : 0|12@1+ (1,0) [0|4095] "A"  HVESP01
 SG_ HVESP01_iChgLim10sLut_6 : 12|12@1+ (1,0) [0|4095] "A"  HVESP01
 SG_ HVESP01_iChgLimInstLut_6 : 24|12@1+ (1,0) [0|4095] "A"  HVESP01
 SG_ HVESP01_iChgLimHeat_6 : 36|12@1+ (1,0) [0|4095] "A"  HVESP01
 SG_ HVESP01_iChgLimDcir_6 : 48|12@1+ (1,0) [0|4095] "A"  HVESP01

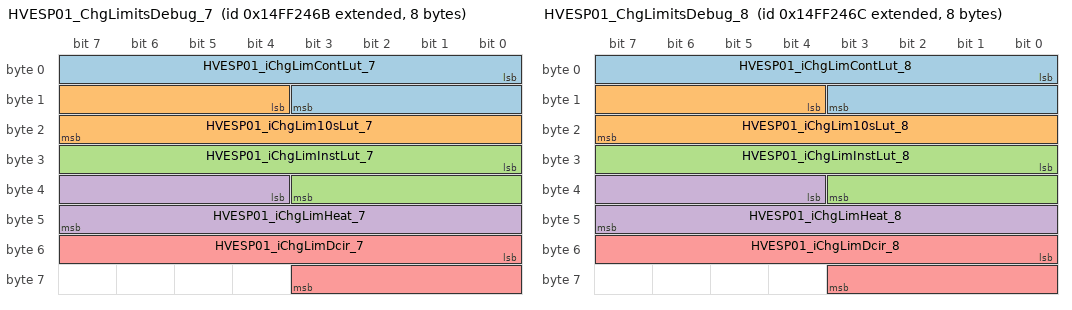
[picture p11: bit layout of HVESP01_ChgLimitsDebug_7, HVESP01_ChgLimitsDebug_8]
BO_ 2499748971 HVESP01_ChgLimitsDebug_7: 8 HVESP01
 SG_ HVESP01_iChgLimContLut_7 : 0|12@1+ (1,0) [0|4095] "A"  HVESP01
 SG_ HVESP01_iChgLim10sLut_7 : 12|12@1+ (1,0) [0|4095] "A"  HVESP01
 SG_ HVESP01_iChgLimInstLut_7 : 24|12@1+ (1,0) [0|4095] "A"  HVESP01
 SG_ HVESP01_iChgLimHeat_7 : 36|12@1+ (1,0) [0|4095] "A"  HVESP01
 SG_ HVESP01_iChgLimDcir_7 : 48|12@1+ (1,0) [0|4095] "A"  HVESP01

BO_ 2499748972 HVESP01_ChgLimitsDebug_8: 8 HVESP01
 SG_ HVESP01_iChgLimContLut_8 : 0|12@1+ (1,0) [0|4095] "A"  HVESP01
 SG_ HVESP01_iChgLim10sLut_8 : 12|12@1+ (1,0) [0|4095] "A"  HVESP01
 SG_ HVESP01_iChgLimInstLut_8 : 24|12@1+ (1,0) [0|4095] "A"  HVESP01
 SG_ HVESP01_iChgLimHeat_8 : 36|12@1+ (1,0) [0|4095] "A"  HVESP01
 SG_ HVESP01_iChgLimDcir_8 : 48|12@1+ (1,0) [0|4095] "A"  HVESP01

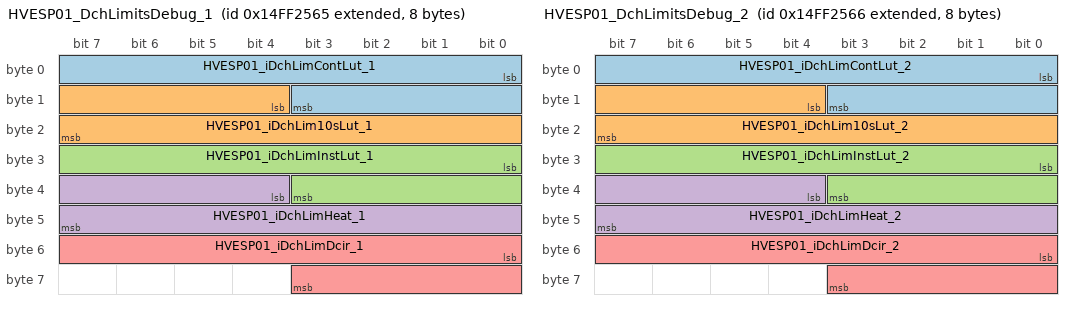
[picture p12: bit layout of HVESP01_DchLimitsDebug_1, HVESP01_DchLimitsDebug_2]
BO_ 2499749221 HVESP01_DchLimitsDebug_1: 8 HVESP01
 SG_ HVESP01_iDchLimContLut_1 : 0|12@1+ (1,0) [0|4095] "A"  HVESP01
 SG_ HVESP01_iDchLim10sLut_1 : 12|12@1+ (1,0) [0|4095] "A"  HVESP01
 SG_ HVESP01_iDchLimInstLut_1 : 24|12@1+ (1,0) [0|4095] "A"  HVESP01
 SG_ HVESP01_iDchLimHeat_1 : 36|12@1+ (1,0) [0|4095] "A"  HVESP01
 SG_ HVESP01_iDchLimDcir_1 : 48|12@1+ (1,0) [0|4095] "A"  HVESP01

BO_ 2499749222 HVESP01_DchLimitsDebug_2: 8 HVESP01
 SG_ HVESP01_iDchLimContLut_2 : 0|12@1+ (1,0) [0|4095] "A"  HVESP01
 SG_ HVESP01_iDchLim10sLut_2 : 12|12@1+ (1,0) [0|4095] "A"  HVESP01
 SG_ HVESP01_iDchLimInstLut_2 : 24|12@1+ (1,0) [0|4095] "A"  HVESP01
 SG_ HVESP01_iDchLimHeat_2 : 36|12@1+ (1,0) [0|4095] "A"  HVESP01
 SG_ HVESP01_iDchLimDcir_2 : 48|12@1+ (1,0) [0|4095] "A"  HVESP01

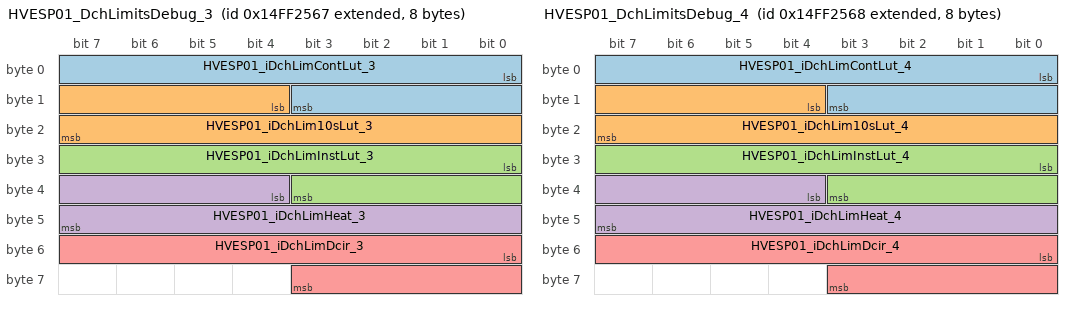
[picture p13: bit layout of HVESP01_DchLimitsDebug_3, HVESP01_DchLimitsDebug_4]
BO_ 2499749223 HVESP01_DchLimitsDebug_3: 8 HVESP01
 SG_ HVESP01_iDchLimContLut_3 : 0|12@1+ (1,0) [0|4095] "A"  HVESP01
 SG_ HVESP01_iDchLim10sLut_3 : 12|12@1+ (1,0) [0|4095] "A"  HVESP01
 SG_ HVESP01_iDchLimInstLut_3 : 24|12@1+ (1,0) [0|4095] "A"  HVESP01
 SG_ HVESP01_iDchLimHeat_3 : 36|12@1+ (1,0) [0|4095] "A"  HVESP01
 SG_ HVESP01_iDchLimDcir_3 : 48|12@1+ (1,0) [0|4095] "A"  HVESP01

BO_ 2499749224 HVESP01_DchLimitsDebug_4: 8 HVESP01
 SG_ HVESP01_iDchLimContLut_4 : 0|12@1+ (1,0) [0|4095] "A"  HVESP01
 SG_ HVESP01_iDchLim10sLut_4 : 12|12@1+ (1,0) [0|4095] "A"  HVESP01
 SG_ HVESP01_iDchLimInstLut_4 : 24|12@1+ (1,0) [0|4095] "A"  HVESP01
 SG_ HVESP01_iDchLimHeat_4 : 36|12@1+ (1,0) [0|4095] "A"  HVESP01
 SG_ HVESP01_iDchLimDcir_4 : 48|12@1+ (1,0) [0|4095] "A"  HVESP01

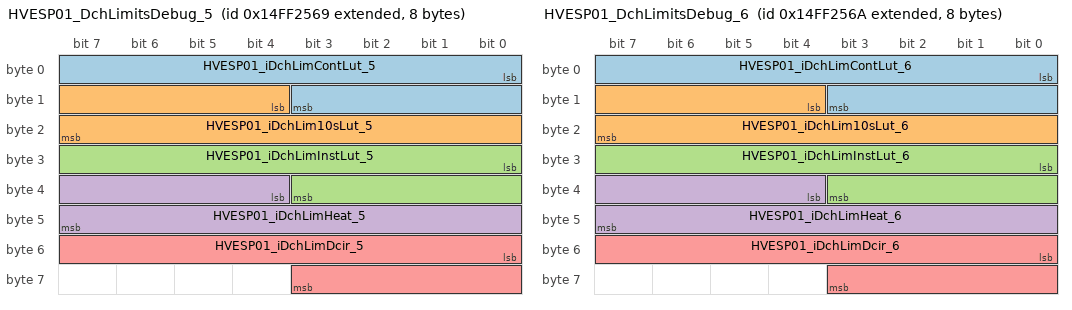
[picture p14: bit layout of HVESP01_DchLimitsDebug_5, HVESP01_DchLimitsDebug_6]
BO_ 2499749225 HVESP01_DchLimitsDebug_5: 8 HVESP01
 SG_ HVESP01_iDchLimContLut_5 : 0|12@1+ (1,0) [0|4095] "A"  HVESP01
 SG_ HVESP01_iDchLim10sLut_5 : 12|12@1+ (1,0) [0|4095] "A"  HVESP01
 SG_ HVESP01_iDchLimInstLut_5 : 24|12@1+ (1,0) [0|4095] "A"  HVESP01
 SG_ HVESP01_iDchLimHeat_5 : 36|12@1+ (1,0) [0|4095] "A"  HVESP01
 SG_ HVESP01_iDchLimDcir_5 : 48|12@1+ (1,0) [0|4095] "A"  HVESP01

BO_ 2499749226 HVESP01_DchLimitsDebug_6: 8 HVESP01
 SG_ HVESP01_iDchLimContLut_6 : 0|12@1+ (1,0) [0|4095] "A"  HVESP01
 SG_ HVESP01_iDchLim10sLut_6 : 12|12@1+ (1,0) [0|4095] "A"  HVESP01
 SG_ HVESP01_iDchLimInstLut_6 : 24|12@1+ (1,0) [0|4095] "A"  HVESP01
 SG_ HVESP01_iDchLimHeat_6 : 36|12@1+ (1,0) [0|4095] "A"  HVESP01
 SG_ HVESP01_iDchLimDcir_6 : 48|12@1+ (1,0) [0|4095] "A"  HVESP01

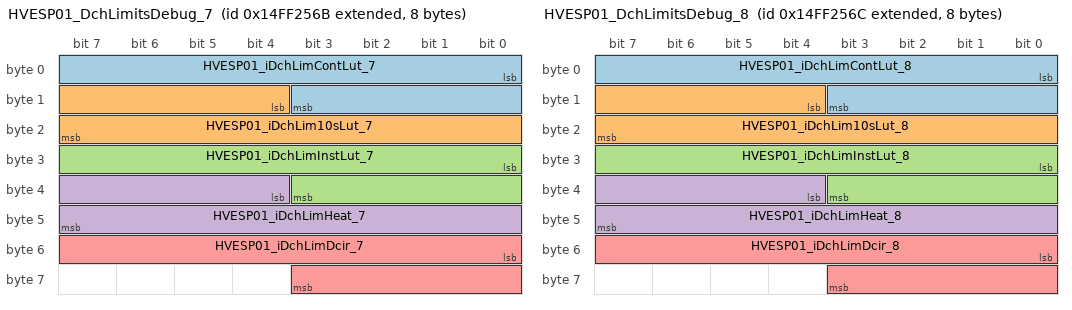
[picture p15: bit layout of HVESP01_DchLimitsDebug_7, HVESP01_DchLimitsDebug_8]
BO_ 2499749227 HVESP01_DchLimitsDebug_7: 8 HVESP01
 SG_ HVESP01_iDchLimContLut_7 : 0|12@1+ (1,0) [0|4095] "A"  HVESP01
 SG_ HVESP01_iDchLim10sLut_7 : 12|12@1+ (1,0) [0|4095] "A"  HVESP01
 SG_ HVESP01_iDchLimInstLut_7 : 24|12@1+ (1,0) [0|4095] "A"  HVESP01
 SG_ HVESP01_iDchLimHeat_7 : 36|12@1+ (1,0) [0|4095] "A"  HVESP01
 SG_ HVESP01_iDchLimDcir_7 : 48|12@1+ (1,0) [0|4095] "A"  HVESP01

BO_ 2499749228 HVESP01_DchLimitsDebug_8: 8 HVESP01
 SG_ HVESP01_iDchLimContLut_8 : 0|12@1+ (1,0) [0|4095] "A"  HVESP01
 SG_ HVESP01_iDchLim10sLut_8 : 12|12@1+ (1,0) [0|4095] "A"  HVESP01
 SG_ HVESP01_iDchLimInstLut_8 : 24|12@1+ (1,0) [0|4095] "A"  HVESP01
 SG_ HVESP01_iDchLimHeat_8 : 36|12@1+ (1,0) [0|4095] "A"  HVESP01
 SG_ HVESP01_iDchLimDcir_8 : 48|12@1+ (1,0) [0|4095] "A"  HVESP01

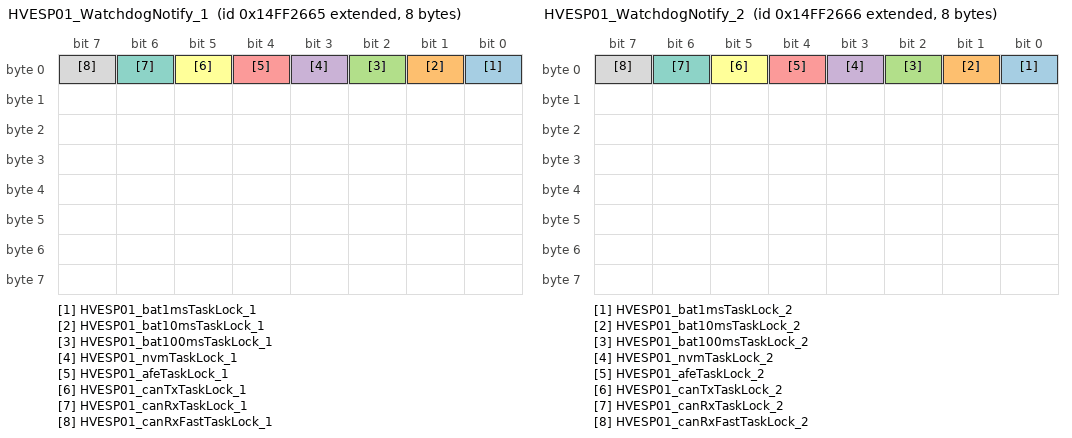
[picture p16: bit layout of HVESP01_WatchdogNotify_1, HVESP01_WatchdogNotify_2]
BO_ 2499749477 HVESP01_WatchdogNotify_1: 8 HVESP01
 SG_ HVESP01_bat1msTaskLock_1 : 0|1@1+ (1,0) [0|1] ""  HVESP01
 SG_ HVESP01_bat10msTaskLock_1 : 1|1@1+ (1,0) [0|1] ""  HVESP01
 SG_ HVESP01_bat100msTaskLock_1 : 2|1@1+ (1,0) [0|1] ""  HVESP01
 SG_ HVESP01_nvmTaskLock_1 : 3|1@1+ (1,0) [0|1] ""  HVESP01
 SG_ HVESP01_afeTaskLock_1 : 4|1@1+ (1,0) [0|1] ""  HVESP01
 SG_ HVESP01_canTxTaskLock_1 : 5|1@1+ (1,0) [0|1] ""  HVESP01
 SG_ HVESP01_canRxTaskLock_1 : 6|1@1+ (1,0) [0|1] ""  HVESP01
 SG_ HVESP01_canRxFastTaskLock_1 : 7|1@1+ (1,0) [0|1] ""  HVESP01

BO_ 2499749478 HVESP01_WatchdogNotify_2: 8 HVESP01
 SG_ HVESP01_bat1msTaskLock_2 : 0|1@1+ (1,0) [0|1] ""  HVESP01
 SG_ HVESP01_bat10msTaskLock_2 : 1|1@1+ (1,0) [0|1] ""  HVESP01
 SG_ HVESP01_bat100msTaskLock_2 : 2|1@1+ (1,0) [0|1] ""  HVESP01
 SG_ HVESP01_nvmTaskLock_2 : 3|1@1+ (1,0) [0|1] ""  HVESP01
 SG_ HVESP01_afeTaskLock_2 : 4|1@1+ (1,0) [0|1] ""  HVESP01
 SG_ HVESP01_canTxTaskLock_2 : 5|1@1+ (1,0) [0|1] ""  HVESP01
 SG_ HVESP01_canRxTaskLock_2 : 6|1@1+ (1,0) [0|1] ""  HVESP01
 SG_ HVESP01_canRxFastTaskLock_2 : 7|1@1+ (1,0) [0|1] ""  HVESP01

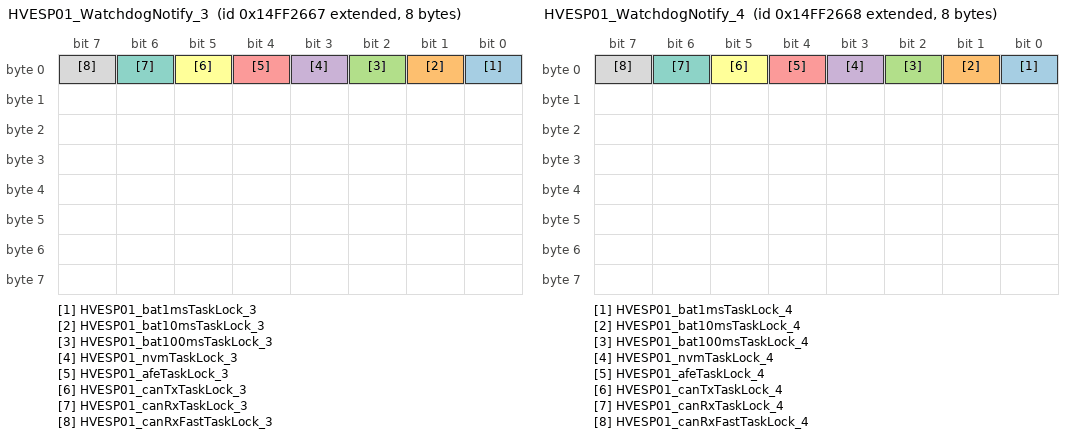
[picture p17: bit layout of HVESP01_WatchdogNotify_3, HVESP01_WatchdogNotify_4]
BO_ 2499749479 HVESP01_WatchdogNotify_3: 8 HVESP01
 SG_ HVESP01_bat1msTaskLock_3 : 0|1@1+ (1,0) [0|1] ""  HVESP01
 SG_ HVESP01_bat10msTaskLock_3 : 1|1@1+ (1,0) [0|1] ""  HVESP01
 SG_ HVESP01_bat100msTaskLock_3 : 2|1@1+ (1,0) [0|1] ""  HVESP01
 SG_ HVESP01_nvmTaskLock_3 : 3|1@1+ (1,0) [0|1] ""  HVESP01
 SG_ HVESP01_afeTaskLock_3 : 4|1@1+ (1,0) [0|1] ""  HVESP01
 SG_ HVESP01_canTxTaskLock_3 : 5|1@1+ (1,0) [0|1] ""  HVESP01
 SG_ HVESP01_canRxTaskLock_3 : 6|1@1+ (1,0) [0|1] ""  HVESP01
 SG_ HVESP01_canRxFastTaskLock_3 : 7|1@1+ (1,0) [0|1] ""  HVESP01

BO_ 2499749480 HVESP01_WatchdogNotify_4: 8 HVESP01
 SG_ HVESP01_bat1msTaskLock_4 : 0|1@1+ (1,0) [0|1] ""  HVESP01
 SG_ HVESP01_bat10msTaskLock_4 : 1|1@1+ (1,0) [0|1] ""  HVESP01
 SG_ HVESP01_bat100msTaskLock_4 : 2|1@1+ (1,0) [0|1] ""  HVESP01
 SG_ HVESP01_nvmTaskLock_4 : 3|1@1+ (1,0) [0|1] ""  HVESP01
 SG_ HVESP01_afeTaskLock_4 : 4|1@1+ (1,0) [0|1] ""  HVESP01
 SG_ HVESP01_canTxTaskLock_4 : 5|1@1+ (1,0) [0|1] ""  HVESP01
 SG_ HVESP01_canRxTaskLock_4 : 6|1@1+ (1,0) [0|1] ""  HVESP01
 SG_ HVESP01_canRxFastTaskLock_4 : 7|1@1+ (1,0) [0|1] ""  HVESP01

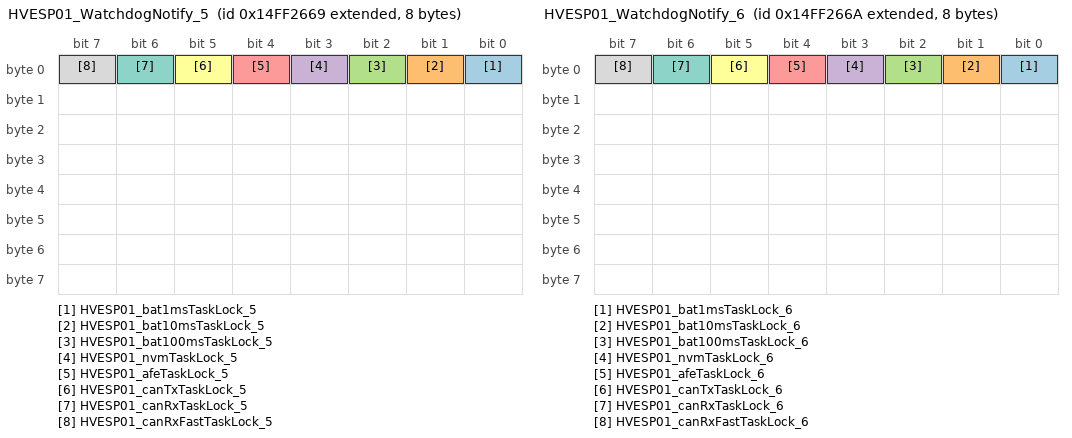
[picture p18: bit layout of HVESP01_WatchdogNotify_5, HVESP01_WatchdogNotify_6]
BO_ 2499749481 HVESP01_WatchdogNotify_5: 8 HVESP01
 SG_ HVESP01_bat1msTaskLock_5 : 0|1@1+ (1,0) [0|1] ""  HVESP01
 SG_ HVESP01_bat10msTaskLock_5 : 1|1@1+ (1,0) [0|1] ""  HVESP01
 SG_ HVESP01_bat100msTaskLock_5 : 2|1@1+ (1,0) [0|1] ""  HVESP01
 SG_ HVESP01_nvmTaskLock_5 : 3|1@1+ (1,0) [0|1] ""  HVESP01
 SG_ HVESP01_afeTaskLock_5 : 4|1@1+ (1,0) [0|1] ""  HVESP01
 SG_ HVESP01_canTxTaskLock_5 : 5|1@1+ (1,0) [0|1] ""  HVESP01
 SG_ HVESP01_canRxTaskLock_5 : 6|1@1+ (1,0) [0|1] ""  HVESP01
 SG_ HVESP01_canRxFastTaskLock_5 : 7|1@1+ (1,0) [0|1] ""  HVESP01

BO_ 2499749482 HVESP01_WatchdogNotify_6: 8 HVESP01
 SG_ HVESP01_bat1msTaskLock_6 : 0|1@1+ (1,0) [0|1] ""  HVESP01
 SG_ HVESP01_bat10msTaskLock_6 : 1|1@1+ (1,0) [0|1] ""  HVESP01
 SG_ HVESP01_bat100msTaskLock_6 : 2|1@1+ (1,0) [0|1] ""  HVESP01
 SG_ HVESP01_nvmTaskLock_6 : 3|1@1+ (1,0) [0|1] ""  HVESP01
 SG_ HVESP01_afeTaskLock_6 : 4|1@1+ (1,0) [0|1] ""  HVESP01
 SG_ HVESP01_canTxTaskLock_6 : 5|1@1+ (1,0) [0|1] ""  HVESP01
 SG_ HVESP01_canRxTaskLock_6 : 6|1@1+ (1,0) [0|1] ""  HVESP01
 SG_ HVESP01_canRxFastTaskLock_6 : 7|1@1+ (1,0) [0|1] ""  HVESP01

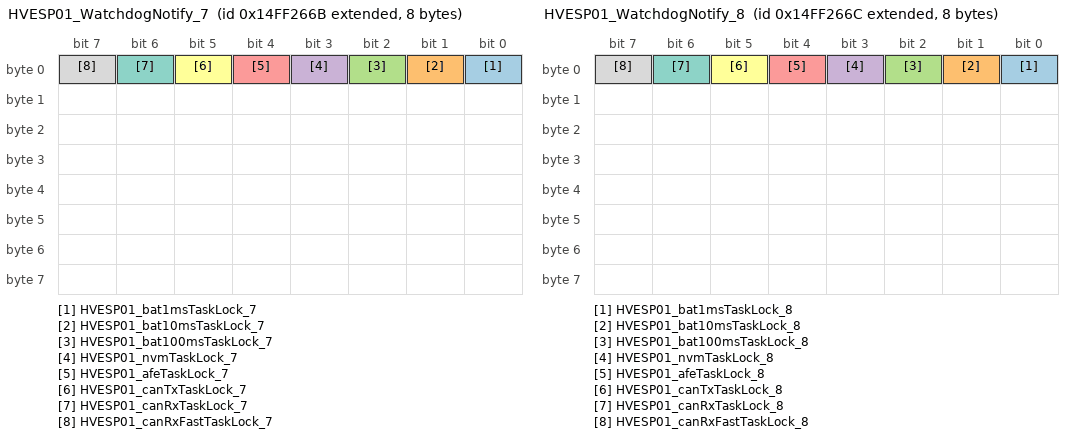
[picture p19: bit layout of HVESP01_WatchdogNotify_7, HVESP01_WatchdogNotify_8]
BO_ 2499749483 HVESP01_WatchdogNotify_7: 8 HVESP01
 SG_ HVESP01_bat1msTaskLock_7 : 0|1@1+ (1,0) [0|1] ""  HVESP01
 SG_ HVESP01_bat10msTaskLock_7 : 1|1@1+ (1,0) [0|1] ""  HVESP01
 SG_ HVESP01_bat100msTaskLock_7 : 2|1@1+ (1,0) [0|1] ""  HVESP01
 SG_ HVESP01_nvmTaskLock_7 : 3|1@1+ (1,0) [0|1] ""  HVESP01
 SG_ HVESP01_afeTaskLock_7 : 4|1@1+ (1,0) [0|1] ""  HVESP01
 SG_ HVESP01_canTxTaskLock_7 : 5|1@1+ (1,0) [0|1] ""  HVESP01
 SG_ HVESP01_canRxTaskLock_7 : 6|1@1+ (1,0) [0|1] ""  HVESP01
 SG_ HVESP01_canRxFastTaskLock_7 : 7|1@1+ (1,0) [0|1] ""  HVESP01

BO_ 2499749484 HVESP01_WatchdogNotify_8: 8 HVESP01
 SG_ HVESP01_bat1msTaskLock_8 : 0|1@1+ (1,0) [0|1] ""  HVESP01
 SG_ HVESP01_bat10msTaskLock_8 : 1|1@1+ (1,0) [0|1] ""  HVESP01
 SG_ HVESP01_bat100msTaskLock_8 : 2|1@1+ (1,0) [0|1] ""  HVESP01
 SG_ HVESP01_nvmTaskLock_8 : 3|1@1+ (1,0) [0|1] ""  HVESP01
 SG_ HVESP01_afeTaskLock_8 : 4|1@1+ (1,0) [0|1] ""  HVESP01
 SG_ HVESP01_canTxTaskLock_8 : 5|1@1+ (1,0) [0|1] ""  HVESP01
 SG_ HVESP01_canRxTaskLock_8 : 6|1@1+ (1,0) [0|1] ""  HVESP01
 SG_ HVESP01_canRxFastTaskLock_8 : 7|1@1+ (1,0) [0|1] ""  HVESP01

BO_ 2499750245 HVESP01_EstOcv_1: 8 HVESP01
 SG_ HVESP01_estOcv_01_1 m0 : 8|14@1+ (0.001,0) [0|16.383] "Ah"  HVESP01
 SG_ HVESP01_estOcv_02_1 m0 : 22|14@1+ (0.001,0) [0|16.383] "Ah"  HVESP01
 SG_ HVESP01_estOcv_03_1 m0 : 36|14@1+ (0.001,0) [0|16.383] "Ah"  HVESP01
 SG_ HVESP01_estOcv_04_1 m0 : 50|14@1+ (0.001,0) [0|16.383] "Ah"  HVESP01
 SG_ HVESP01_estOcv_05_1 m1 : 8|14@1+ (0.001,0) [0|16.383] "Ah"  HVESP01
 SG_ HVESP01_estOcv_06_1 m1 : 22|14@1+ (0.001,0) [0|16.383] "Ah"  HVESP01
 SG_ HVESP01_estOcv_07_1 m1 : 36|14@1+ (0.001,0) [0|16.383] "Ah"  HVESP01
 SG_ HVESP01_estOcv_08_1 m1 : 50|14@1+ (0.001,0) [0|16.383] "Ah"  HVESP01
 SG_ HVESP01_estOcv_09_1 m2 : 8|14@1+ (0.001,0) [0|16.383] "Ah"  HVESP01
 SG_ HVESP01_estOcv_10_1 m2 : 22|14@1+ (0.001,0) [0|16.383] "Ah"  HVESP01
 SG_ HVESP01_estOcv_11_1 m2 : 36|14@1+ (0.001,0) [0|16.383] "Ah"  HVESP01
 SG_ HVESP01_estOcv_12_1 m2 : 50|14@1+ (0.001,0) [0|16.383] "Ah"  HVESP01
 SG_ HVESP01_estOcv_13_1 m3 : 8|14@1+ (0.001,0) [0|16.383] "Ah"  HVESP01
 SG_ HVESP01_estOcv_14_1 m3 : 22|14@1+ (0.001,0) [0|16.383] "Ah"  HVESP01
 SG_ HVESP01_estOcv_15_1 m3 : 36|14@1+ (0.001,0) [0|16.383] "Ah"  HVESP01
 SG_ HVESP01_estOcv_16_1 m3 : 50|14@1+ (0.001,0) [0|16.383] "Ah"  HVESP01
 SG_ HVESP01_estOcv_17_1 m4 : 8|14@1+ (0.001,0) [0|16.383] "Ah"  HVESP01
 SG_ HVESP01_estOcv_18_1 m4 : 22|14@1+ (0.001,0) [0|16.383] "Ah"  HVESP01
 SG_ HVESP01_estOcv_19_1 m4 : 36|14@1+ (0.001,0) [0|16.383] "Ah"  HVESP01
 SG_ HVESP01_estOcv_20_1 m4 : 50|14@1+ (0.001,0) [0|16.383] "Ah"  HVESP01
 SG_ HVESP01_estOcv_21_1 m5 : 8|14@1+ (0.001,0) [0|16.383] "Ah"  HVESP01
 SG_ HVESP01_estOcv_22_1 m5 : 22|14@1+ (0.001,0) [0|16.383] "Ah"  HVESP01
 SG_ HVESP01_estOcv_23_1 m5 : 36|14@1+ (0.001,0) [0|16.383] "Ah"  HVESP01
 SG_ HVESP01_estOcv_24_1 m5 : 50|14@1+ (0.001,0) [0|16.383] "Ah"  HVESP01
 SG_ HVESP01_estOcv_25_1 m6 : 8|14@1+ (0.001,0) [0|16.383] "Ah"  HVESP01
 SG_ HVESP01_estOcv_26_1 m6 : 22|14@1+ (0.001,0) [0|16.383] "Ah"  HVESP01
 SG_ HVESP01_estOcv_27_1 m6 : 36|14@1+ (0.001,0) [0|16.383] "Ah"  HVESP01
 SG_ HVESP01_estOcv_28_1 m6 : 50|14@1+ (0.001,0) [0|16.383] "Ah"  HVESP01
 SG_ HVESP01_estOcv_29_1 m7 : 8|14@1+ (0.001,0) [0|16.383] "Ah"  HVESP01
 SG_ HVESP01_estOcv_30_1 m7 : 22|14@1+ (0.001,0) [0|16.383] "Ah"  HVESP01
 SG_ HVESP01_estOcv_31_1 m7 : 36|14@1+ (0.001,0) [0|16.383] "Ah"  HVESP01
 SG_ HVESP01_estOcv_32_1 m7 : 50|14@1+ (0.001,0) [0|16.383] "Ah"  HVESP01
 SG_ HVESP01_estOcv_33_1 m8 : 8|14@1+ (0.001,0) [0|16.383] "Ah"  HVESP01
 SG_ HVESP01_estOcv_34_1 m8 : 22|14@1+ (0.001,0) [0|16.383] "Ah"  HVESP01
 SG_ HVESP01_estOcv_35_1 m8 : 36|14@1+ (0.001,0) [0|16.383] "Ah"  HVESP01
 SG_ HVESP01_estOcv_36_1 m8 : 50|14@1+ (0.001,0) [0|16.383] "Ah"  HVESP01
 SG_ HVESP01_estOcv_37_1 m9 : 8|14@1+ (0.001,0) [0|16.383] "Ah"  HVESP01
 SG_ HVESP01_estOcv_38_1 m9 : 22|14@1+ (0.001,0) [0|16.383] "Ah"  HVESP01
 SG_ HVESP01_estOcv_39_1 m9 : 36|14@1+ (0.001,0) [0|16.383] "Ah"  HVESP01
 SG_ HVESP01_estOcv_40_1 m9 : 50|14@1+ (0.001,0) [0|16.383] "Ah"  HVESP01
 SG_ HVESP01_estOcv_41_1 m10 : 8|14@1+ (0.001,0) [0|16.383] "Ah"  HVESP01
 SG_ HVESP01_estOcv_42_1 m10 : 22|14@1+ (0.001,0) [0|16.383] "Ah"  HVESP01
 SG_ HVESP01_estOcv_43_1 m10 : 36|14@1+ (0.001,0) [0|16.383] "Ah"  HVESP01
 SG_ HVESP01_estOcv_44_1 m10 : 50|14@1+ (0.001,0) [0|16.383] "Ah"  HVESP01
 SG_ HVESP01_estOcv_45_1 m11 : 8|14@1+ (0.001,0) [0|16.383] "Ah"  HVESP01
 SG_ HVESP01_estOcv_46_1 m11 : 22|14@1+ (0.001,0) [0|16.383] "Ah"  HVESP01
 SG_ HVESP01_estOcv_47_1 m11 : 36|14@1+ (0.001,0) [0|16.383] "Ah"  HVESP01
 SG_ HVESP01_estOcv_48_1 m11 : 50|14@1+ (0.001,0) [0|16.383] "Ah"  HVESP01
 SG_ HVESP01_estOcv_49_1 m12 : 8|14@1+ (0.001,0) [0|16.383] "Ah"  HVESP01
 SG_ HVESP01_estOcv_50_1 m12 : 22|14@1+ (0.001,0) [0|16.383] "Ah"  HVESP01
 SG_ HVESP01_estOcv_51_1 m12 : 36|14@1+ (0.001,0) [0|16.383] "Ah"  HVESP01
 SG_ HVESP01_estOcv_52_1 m12 : 50|14@1+ (0.001,0) [0|16.383] "Ah"  HVESP01
 SG_ HVESP01_estOcv_53_1 m13 : 8|14@1+ (0.001,0) [0|16.383] "Ah"  HVESP01
 SG_ HVESP01_estOcv_54_1 m13 : 22|14@1+ (0.001,0) [0|16.383] "Ah"  HVESP01
 SG_ HVESP01_estOcv_55_1 m13 : 36|14@1+ (0.001,0) [0|16.383] "Ah"  HVESP01
 SG_ HVESP01_estOcv_56_1 m13 : 50|14@1+ (0.001,0) [0|16.383] "Ah"  HVESP01
 SG_ HVESP01_estOcv_57_1 m14 : 8|14@1+ (0.001,0) [0|16.383] "Ah"  HVESP01
 SG_ HVESP01_estOcv_58_1 m14 : 22|14@1+ (0.001,0) [0|16.383] "Ah"  HVESP01
 SG_ HVESP01_estOcv_59_1 m14 : 36|14@1+ (0.001,0) [0|16.383] "Ah"  HVESP01
 SG_ HVESP01_estOcv_60_1 m14 : 50|14@1+ (0.001,0) [0|16.383] "Ah"  HVESP01
 SG_ HVESP01_estOcv_61_1 m15 : 8|14@1+ (0.001,0) [0|16.383] "Ah"  HVESP01
 SG_ HVESP01_estOcv_62_1 m15 : 22|14@1+ (0.001,0) [0|16.383] "Ah"  HVESP01
 SG_ HVESP01_estOcv_63_1 m15 : 36|14@1+ (0.001,0) [0|16.383] "Ah"  HVESP01
 SG_ HVESP01_estOcv_64_1 m15 : 50|14@1+ (0.001,0) [0|16.383] "Ah"  HVESP01
 SG_ HVESP01_estOcv_65_1 m16 : 8|14@1+ (0.001,0) [0|16.383] "Ah"  HVESP01
 SG_ HVESP01_estOcv_66_1 m16 : 22|14@1+ (0.001,0) [0|16.383] "Ah"  HVESP01
 SG_ HVESP01_estOcv_67_1 m16 : 36|14@1+ (0.001,0) [0|16.383] "Ah"  HVESP01
 SG_ HVESP01_estOcv_68_1 m16 : 50|14@1+ (0.001,0) [0|16.383] "Ah"  HVESP01
 SG_ HVESP01_estOcv_69_1 m17 : 8|14@1+ (0.001,0) [0|16.383] "Ah"  HVESP01
 SG_ HVESP01_estOcv_70_1 m17 : 22|14@1+ (0.001,0) [0|16.383] "Ah"  HVESP01
 SG_ HVESP01_estOcv_71_1 m17 : 36|14@1+ (0.001,0) [0|16.383] "Ah"  HVESP01
 SG_ HVESP01_estOcv_72_1 m17 : 50|14@1+ (0.001,0) [0|16.383] "Ah"  HVESP01
 SG_ HVESP01_estOcv_73_1 m18 : 8|14@1+ (0.001,0) [0|16.383] "Ah"  HVESP01
 SG_ HVESP01_estOcv_74_1 m18 : 22|14@1+ (0.001,0) [0|16.383] "Ah"  HVESP01
 SG_ HVESP01_estOcv_75_1 m18 : 36|14@1+ (0.001,0) [0|16.383] "Ah"  HVESP01
 SG_ HVESP01_estOcv_76_1 m18 : 50|14@1+ (0.001,0) [0|16.383] "Ah"  HVESP01
 SG_ HVESP01_estOcv_77_1 m19 : 8|14@1+ (0.001,0) [0|16.383] "Ah"  HVESP01
 SG_ HVESP01_estOcv_78_1 m19 : 22|14@1+ (0.001,0) [0|16.383] "Ah"  HVESP01
 SG_ HVESP01_estOcv_79_1 m19 : 36|14@1+ (0.001,0) [0|16.383] "Ah"  HVESP01
 SG_ HVESP01_estOcv_80_1 m19 : 50|14@1+ (0.001,0) [0|16.383] "Ah"  HVESP01
 SG_ HVESP01_estOcv_81_1 m20 : 8|14@1+ (0.001,0) [0|16.383] "Ah"  HVESP01
 SG_ HVESP01_estOcv_82_1 m20 : 22|14@1+ (0.001,0) [0|16.383] "Ah"  HVESP01
 SG_ HVESP01_estOcv_83_1 m20 : 36|14@1+ (0.001,0) [0|16.383] "Ah"  HVESP01
 SG_ HVESP01_estOcv_84_1 m20 : 50|14@1+ (0.001,0) [0|16.383] "Ah"  HVESP01
 SG_ HVESP01_estOcv_85_1 m21 : 8|14@1+ (0.001,0) [0|16.383] "Ah"  HVESP01
 SG_ HVESP01_estOcv_86_1 m21 : 22|14@1+ (0.001,0) [0|16.383] "Ah"  HVESP01
 SG_ HVESP01_estOcv_87_1 m21 : 36|14@1+ (0.001,0) [0|16.383] "Ah"  HVESP01
 SG_ HVESP01_estOcv_88_1 m21 : 50|14@1+ (0.001,0) [0|16.383] "Ah"  HVESP01
 SG_ HVESP01_estOcv_89_1 m22 : 8|14@1+ (0.001,0) [0|16.383] "Ah"  HVESP01
 SG_ HVESP01_estOcv_90_1 m22 : 22|14@1+ (0.001,0) [0|16.383] "Ah"  HVESP01
 SG_ HVESP01_estOcv_91_1 m22 : 36|14@1+ (0.001,0) [0|16.383] "Ah"  HVESP01
 SG_ HVESP01_estOcv_92_1 m22 : 50|14@1+ (0.001,0) [0|16.383] "Ah"  HVESP01
 SG_ HVESP01_estOcv_93_1 m23 : 8|14@1+ (0.001,0) [0|16.383] "Ah"  HVESP01
 SG_ HVESP01_estOcv_94_1 m23 : 22|14@1+ (0.001,0) [0|16.383] "Ah"  HVESP01
 SG_ HVESP01_estOcv_95_1 m23 : 36|14@1+ (0.001,0) [0|16.383] "Ah"  HVESP01
 SG_ HVESP01_estOcv_96_1 m23 : 50|14@1+ (0.001,0) [0|16.383] "Ah"  HVESP01
 SG_ HVESP01_estOcv_97_1 m24 : 8|14@1+ (0.001,0) [0|16.383] "Ah"  HVESP01
 SG_ HVESP01_estOcv_98_1 m24 : 22|14@1+ (0.001,0) [0|16.383] "Ah"  HVESP01
 SG_ HVESP01_estOcv_99_1 m24 : 36|14@1+ (0.001,0) [0|16.383] "Ah"  HVESP01
 SG_ HVESP01_estOcv_100_1 m24 : 50|14@1+ (0.001,0) [0|16.383] "Ah"  HVESP01
 SG_ HVESP01_estOcv_101_1 m25 : 8|14@1+ (0.001,0) [0|16.383] "Ah"  HVESP01
 SG_ HVESP01_estOcv_102_1 m25 : 22|14@1+ (0.001,0) [0|16.383] "Ah"  HVESP01
 SG_ HVESP01_estOcv_103_1 m25 : 36|14@1+ (0.001,0) [0|16.383] "Ah"  HVESP01
 SG_ HVESP01_estOcv_104_1 m25 : 50|14@1+ (0.001,0) [0|16.383] "Ah"  HVESP01
 SG_ HVESP01_estOcv_105_1 m26 : 8|14@1+ (0.001,0) [0|16.383] "Ah"  HVESP01
 SG_ HVESP01_estOcv_106_1 m26 : 22|14@1+ (0.001,0) [0|16.383] "Ah"  HVESP01
 SG_ HVESP01_estOcv_107_1 m26 : 36|14@1+ (0.001,0) [0|16.383] "Ah"  HVESP01
 SG_ HVESP01_estOcv_108_1 m26 : 50|14@1+ (0.001,0) [0|16.383] "Ah"  HVESP01
 SG_ HVESP01_estOcv_109_1 m27 : 8|14@1+ (0.001,0) [0|16.383] "Ah"  HVESP01
 SG_ HVESP01_estOcv_110_1 m27 : 22|14@1+ (0.001,0) [0|16.383] "Ah"  HVESP01
 SG_ HVESP01_estOcv_111_1 m27 : 36|14@1+ (0.001,0) [0|16.383] "Ah"  HVESP01
 SG_ HVESP01_estOcv_112_1 m27 : 50|14@1+ (0.001,0) [0|16.383] "Ah"  HVESP01
 SG_ HVESP01_estOcv_113_1 m28 : 8|14@1+ (0.001,0) [0|16.383] "Ah"  HVESP01
 SG_ HVESP01_estOcv_114_1 m28 : 22|14@1+ (0.001,0) [0|16.383] "Ah"  HVESP01
 SG_ HVESP01_estOcv_115_1 m28 : 36|14@1+ (0.001,0) [0|16.383] "Ah"  HVESP01
 SG_ HVESP01_estOcv_116_1 m28 : 50|14@1+ (0.001,0) [0|16.383] "Ah"  HVESP01
 SG_ HVESP01_estOcv_117_1 m29 : 8|14@1+ (0.001,0) [0|16.383] "Ah"  HVESP01
 SG_ HVESP01_estOcv_118_1 m29 : 22|14@1+ (0.001,0) [0|16.383] "Ah"  HVESP01
 SG_ HVESP01_estOcv_119_1 m29 : 36|14@1+ (0.001,0) [0|16.383] "Ah"  HVESP01
 SG_ HVESP01_estOcv_120_1 m29 : 50|14@1+ (0.001,0) [0|16.383] "Ah"  HVESP01
 SG_ HVESP01_estOcv_121_1 m30 : 8|14@1+ (0.001,0) [0|16.383] "Ah"  HVESP01
 SG_ HVESP01_estOcv_122_1 m30 : 22|14@1+ (0.001,0) [0|16.383] "Ah"  HVESP01
 SG_ HVESP01_estOcv_123_1 m30 : 36|14@1+ (0.001,0) [0|16.383] "Ah"  HVESP01
 SG_ HVESP01_estOcv_124_1 m30 : 50|14@1+ (0.001,0) [0|16.383] "Ah"  HVESP01
 SG_ HVESP01_estOcv_125_1 m31 : 8|14@1+ (0.001,0) [0|16.383] "Ah"  HVESP01
 SG_ HVESP01_estOcv_126_1 m31 : 22|14@1+ (0.001,0) [0|16.383] "Ah"  HVESP01
 SG_ HVESP01_estOcv_127_1 m31 : 36|14@1+ (0.001,0) [0|16.383] "Ah"  HVESP01
 SG_ HVESP01_estOcv_128_1 m31 : 50|14@1+ (0.001,0) [0|16.383] "Ah"  HVESP01
 SG_ HVESP01_estOcv_129_1 m32 : 8|14@1+ (0.001,0) [0|16.383] "Ah"  HVESP01
 SG_ HVESP01_estOcv_130_1 m32 : 22|14@1+ (0.001,0) [0|16.383] "Ah"  HVESP01
 SG_ HVESP01_estOcv_131_1 m32 : 36|14@1+ (0.001,0) [0|16.383] "Ah"  HVESP01
 SG_ HVESP01_estOcv_132_1 m32 : 50|14@1+ (0.001,0) [0|16.383] "Ah"  HVESP01
 SG_ HVESP01_estOcv_133_1 m33 : 8|14@1+ (0.001,0) [0|16.383] "Ah"  HVESP01
 SG_ HVESP01_estOcv_134_1 m33 : 22|14@1+ (0.001,0) [0|16.383] "Ah"  HVESP01
 SG_ HVESP01_estOcv_135_1 m33 : 36|14@1+ (0.001,0) [0|16.383] "Ah"  HVESP01
 SG_ HVESP01_estOcv_136_1 m33 : 50|14@1+ (0.001,0) [0|16.383] "Ah"  HVESP01
 SG_ HVESP01_estOcv_137_1 m34 : 8|14@1+ (0.001,0) [0|16.383] "Ah"  HVESP01
 SG_ HVESP01_estOcv_138_1 m34 : 22|14@1+ (0.001,0) [0|16.383] "Ah"  HVESP01
 SG_ HVESP01_estOcv_139_1 m34 : 36|14@1+ (0.001,0) [0|16.383] "Ah"  HVESP01
 SG_ HVESP01_estOcv_140_1 m34 : 50|14@1+ (0.001,0) [0|16.383] "Ah"  HVESP01
 SG_ HVESP01_estOcv_141_1 m35 : 8|14@1+ (0.001,0) [0|16.383] "Ah"  HVESP01
 SG_ HVESP01_estOcv_142_1 m35 : 22|14@1+ (0.001,0) [0|16.383] "Ah"  HVESP01
 SG_ HVESP01_estOcv_143_1 m35 : 36|14@1+ (0.001,0) [0|16.383] "Ah"  HVESP01
 SG_ HVESP01_estOcv_144_1 m35 : 50|14@1+ (0.001,0) [0|16.383] "Ah"  HVESP01
 SG_ HVESP01_estOcv_145_1 m36 : 8|14@1+ (0.001,0) [0|16.383] "Ah"  HVESP01
 SG_ HVESP01_estOcv_146_1 m36 : 22|14@1+ (0.001,0) [0|16.383] "Ah"  HVESP01
 SG_ HVESP01_estOcv_147_1 m36 : 36|14@1+ (0.001,0) [0|16.383] "Ah"  HVESP01
 SG_ HVESP01_estOcv_148_1 m36 : 50|14@1+ (0.001,0) [0|16.383] "Ah"  HVESP01
 SG_ HVESP01_estOcv_149_1 m37 : 8|14@1+ (0.001,0) [0|16.383] "Ah"  HVESP01
 SG_ HVESP01_estOcv_150_1 m37 : 22|14@1+ (0.001,0) [0|16.383] "Ah"  HVESP01
 SG_ HVESP01_estOcv_151_1 m37 : 36|14@1+ (0.001,0) [0|16.383] "Ah"  HVESP01
 SG_ HVESP01_estOcv_152_1 m37 : 50|14@1+ (0.001,0) [0|16.383] "Ah"  HVESP01
 SG_ HVESP01_estOcv_153_1 m38 : 8|14@1+ (0.001,0) [0|16.383] "Ah"  HVESP01
 SG_ HVESP01_estOcv_154_1 m38 : 22|14@1+ (0.001,0) [0|16.383] "Ah"  HVESP01
 SG_ HVESP01_estOcv_155_1 m38 : 36|14@1+ (0.001,0) [0|16.383] "Ah"  HVESP01
 SG_ HVESP01_estOcv_156_1 m38 : 50|14@1+ (0.001,0) [0|16.383] "Ah"  HVESP01
 SG_ HVESP01_estOcv_157_1 m39 : 8|14@1+ (0.001,0) [0|16.383] "Ah"  HVESP01
 SG_ HVESP01_estOcv_158_1 m39 : 22|14@1+ (0.001,0) [0|16.383] "Ah"  HVESP01
 SG_ HVESP01_estOcv_159_1 m39 : 36|14@1+ (0.001,0) [0|16.383] "Ah"  HVESP01
 SG_ HVESP01_estOcv_160_1 m39 : 50|14@1+ (0.001,0) [0|16.383] "Ah"  HVESP01
 SG_ HVESP01_estOcv_161_1 m40 : 8|14@1+ (0.001,0) [0|16.383] "Ah"  HVESP01
 SG_ HVESP01_estOcv_162_1 m40 : 22|14@1+ (0.001,0) [0|16.383] "Ah"  HVESP01
 SG_ HVESP01_estOcv_163_1 m40 : 36|14@1+ (0.001,0) [0|16.383] "Ah"  HVESP01
 SG_ HVESP01_estOcv_164_1 m40 : 50|14@1+ (0.001,0) [0|16.383] "Ah"  HVESP01
 SG_ HVESP01_estOcv_165_1 m41 : 8|14@1+ (0.001,0) [0|16.383] "Ah"  HVESP01
 SG_ HVESP01_estOcv_166_1 m41 : 22|14@1+ (0.001,0) [0|16.383] "Ah"  HVESP01
 SG_ HVESP01_estOcv_167_1 m41 : 36|14@1+ (0.001,0) [0|16.383] "Ah"  HVESP01
 SG_ HVESP01_estOcv_168_1 m41 : 50|14@1+ (0.001,0) [0|16.383] "Ah"  HVESP01
 SG_ HVESP01_estOcv_169_1 m42 : 8|14@1+ (0.001,0) [0|16.383] "Ah"  HVESP01
 SG_ HVESP01_estOcv_170_1 m42 : 22|14@1+ (0.001,0) [0|16.383] "Ah"  HVESP01
 SG_ HVESP01_estOcv_171_1 m42 : 36|14@1+ (0.001,0) [0|16.383] "Ah"  HVESP01
 SG_ HVESP01_estOcv_172_1 m42 : 50|14@1+ (0.001,0) [0|16.383] "Ah"  HVESP01
 SG_ HVESP01_estOcv_173_1 m43 : 8|14@1+ (0.001,0) [0|16.383] "Ah"  HVESP01
 SG_ HVESP01_estOcv_174_1 m43 : 22|14@1+ (0.001,0) [0|16.383] "Ah"  HVESP01
 SG_ HVESP01_estOcv_175_1 m43 : 36|14@1+ (0.001,0) [0|16.383] "Ah"  HVESP01
 SG_ HVESP01_estOcv_176_1 m43 : 50|14@1+ (0.001,0) [0|16.383] "Ah"  HVESP01
 SG_ HVESP01_estOcv_177_1 m44 : 8|14@1+ (0.001,0) [0|16.383] "Ah"  HVESP01
 SG_ HVESP01_estOcv_178_1 m44 : 22|14@1+ (0.001,0) [0|16.383] "Ah"  HVESP01
 SG_ HVESP01_estOcv_179_1 m44 : 36|14@1+ (0.001,0) [0|16.383] "Ah"  HVESP01
 SG_ HVESP01_estOcv_180_1 m44 : 50|14@1+ (0.001,0) [0|16.383] "Ah"  HVESP01
 SG_ multiplexoreo_1 M : 0|8@1+ (1,0) [0|255] ""  HVESP01

BO_ 2499750246 HVESP01_EstOcv_2: 8 HVESP01
 SG_ HVESP01_estOcv_01_2 m0 : 8|14@1+ (0.001,0) [0|16.383] "Ah"  HVESP01
 SG_ HVESP01_estOcv_02_2 m0 : 22|14@1+ (0.001,0) [0|16.383] "Ah"  HVESP01
 SG_ HVESP01_estOcv_03_2 m0 : 36|14@1+ (0.001,0) [0|16.383] "Ah"  HVESP01
 SG_ HVESP01_estOcv_04_2 m0 : 50|14@1+ (0.001,0) [0|16.383] "Ah"  HVESP01
 SG_ HVESP01_estOcv_05_2 m1 : 8|14@1+ (0.001,0) [0|16.383] "Ah"  HVESP01
 SG_ HVESP01_estOcv_06_2 m1 : 22|14@1+ (0.001,0) [0|16.383] "Ah"  HVESP01
 SG_ HVESP01_estOcv_07_2 m1 : 36|14@1+ (0.001,0) [0|16.383] "Ah"  HVESP01
 SG_ HVESP01_estOcv_08_2 m1 : 50|14@1+ (0.001,0) [0|16.383] "Ah"  HVESP01
 SG_ HVESP01_estOcv_09_2 m2 : 8|14@1+ (0.001,0) [0|16.383] "Ah"  HVESP01
 SG_ HVESP01_estOcv_10_2 m2 : 22|14@1+ (0.001,0) [0|16.383] "Ah"  HVESP01
 SG_ HVESP01_estOcv_11_2 m2 : 36|14@1+ (0.001,0) [0|16.383] "Ah"  HVESP01
 SG_ HVESP01_estOcv_12_2 m2 : 50|14@1+ (0.001,0) [0|16.383] "Ah"  HVESP01
 SG_ HVESP01_estOcv_13_2 m3 : 8|14@1+ (0.001,0) [0|16.383] "Ah"  HVESP01
 SG_ HVESP01_estOcv_14_2 m3 : 22|14@1+ (0.001,0) [0|16.383] "Ah"  HVESP01
 SG_ HVESP01_estOcv_15_2 m3 : 36|14@1+ (0.001,0) [0|16.383] "Ah"  HVESP01
 SG_ HVESP01_estOcv_16_2 m3 : 50|14@1+ (0.001,0) [0|16.383] "Ah"  HVESP01
 SG_ HVESP01_estOcv_17_2 m4 : 8|14@1+ (0.001,0) [0|16.383] "Ah"  HVESP01
 SG_ HVESP01_estOcv_18_2 m4 : 22|14@1+ (0.001,0) [0|16.383] "Ah"  HVESP01
 SG_ HVESP01_estOcv_19_2 m4 : 36|14@1+ (0.001,0) [0|16.383] "Ah"  HVESP01
 SG_ HVESP01_estOcv_20_2 m4 : 50|14@1+ (0.001,0) [0|16.383] "Ah"  HVESP01
 SG_ HVESP01_estOcv_21_2 m5 : 8|14@1+ (0.001,0) [0|16.383] "Ah"  HVESP01
 SG_ HVESP01_estOcv_22_2 m5 : 22|14@1+ (0.001,0) [0|16.383] "Ah"  HVESP01
 SG_ HVESP01_estOcv_23_2 m5 : 36|14@1+ (0.001,0) [0|16.383] "Ah"  HVESP01
 SG_ HVESP01_estOcv_24_2 m5 : 50|14@1+ (0.001,0) [0|16.383] "Ah"  HVESP01
 SG_ HVESP01_estOcv_25_2 m6 : 8|14@1+ (0.001,0) [0|16.383] "Ah"  HVESP01
 SG_ HVESP01_estOcv_26_2 m6 : 22|14@1+ (0.001,0) [0|16.383] "Ah"  HVESP01
 SG_ HVESP01_estOcv_27_2 m6 : 36|14@1+ (0.001,0) [0|16.383] "Ah"  HVESP01
 SG_ HVESP01_estOcv_28_2 m6 : 50|14@1+ (0.001,0) [0|16.383] "Ah"  HVESP01
 SG_ HVESP01_estOcv_29_2 m7 : 8|14@1+ (0.001,0) [0|16.383] "Ah"  HVESP01
 SG_ HVESP01_estOcv_30_2 m7 : 22|14@1+ (0.001,0) [0|16.383] "Ah"  HVESP01
 SG_ HVESP01_estOcv_31_2 m7 : 36|14@1+ (0.001,0) [0|16.383] "Ah"  HVESP01
 SG_ HVESP01_estOcv_32_2 m7 : 50|14@1+ (0.001,0) [0|16.383] "Ah"  HVESP01
 SG_ HVESP01_estOcv_33_2 m8 : 8|14@1+ (0.001,0) [0|16.383] "Ah"  HVESP01
 SG_ HVESP01_estOcv_34_2 m8 : 22|14@1+ (0.001,0) [0|16.383] "Ah"  HVESP01
 SG_ HVESP01_estOcv_35_2 m8 : 36|14@1+ (0.001,0) [0|16.383] "Ah"  HVESP01
 SG_ HVESP01_estOcv_36_2 m8 : 50|14@1+ (0.001,0) [0|16.383] "Ah"  HVESP01
 SG_ HVESP01_estOcv_37_2 m9 : 8|14@1+ (0.001,0) [0|16.383] "Ah"  HVESP01
 SG_ HVESP01_estOcv_38_2 m9 : 22|14@1+ (0.001,0) [0|16.383] "Ah"  HVESP01
 SG_ HVESP01_estOcv_39_2 m9 : 36|14@1+ (0.001,0) [0|16.383] "Ah"  HVESP01
 SG_ HVESP01_estOcv_40_2 m9 : 50|14@1+ (0.001,0) [0|16.383] "Ah"  HVESP01
 SG_ HVESP01_estOcv_41_2 m10 : 8|14@1+ (0.001,0) [0|16.383] "Ah"  HVESP01
 SG_ HVESP01_estOcv_42_2 m10 : 22|14@1+ (0.001,0) [0|16.383] "Ah"  HVESP01
 SG_ HVESP01_estOcv_43_2 m10 : 36|14@1+ (0.001,0) [0|16.383] "Ah"  HVESP01
 SG_ HVESP01_estOcv_44_2 m10 : 50|14@1+ (0.001,0) [0|16.383] "Ah"  HVESP01
 SG_ HVESP01_estOcv_45_2 m11 : 8|14@1+ (0.001,0) [0|16.383] "Ah"  HVESP01
 SG_ HVESP01_estOcv_46_2 m11 : 22|14@1+ (0.001,0) [0|16.383] "Ah"  HVESP01
 SG_ HVESP01_estOcv_47_2 m11 : 36|14@1+ (0.001,0) [0|16.383] "Ah"  HVESP01
 SG_ HVESP01_estOcv_48_2 m11 : 50|14@1+ (0.001,0) [0|16.383] "Ah"  HVESP01
 SG_ HVESP01_estOcv_49_2 m12 : 8|14@1+ (0.001,0) [0|16.383] "Ah"  HVESP01
 SG_ HVESP01_estOcv_50_2 m12 : 22|14@1+ (0.001,0) [0|16.383] "Ah"  HVESP01
 SG_ HVESP01_estOcv_51_2 m12 : 36|14@1+ (0.001,0) [0|16.383] "Ah"  HVESP01
 SG_ HVESP01_estOcv_52_2 m12 : 50|14@1+ (0.001,0) [0|16.383] "Ah"  HVESP01
 SG_ HVESP01_estOcv_53_2 m13 : 8|14@1+ (0.001,0) [0|16.383] "Ah"  HVESP01
 SG_ HVESP01_estOcv_54_2 m13 : 22|14@1+ (0.001,0) [0|16.383] "Ah"  HVESP01
 SG_ HVESP01_estOcv_55_2 m13 : 36|14@1+ (0.001,0) [0|16.383] "Ah"  HVESP01
 SG_ HVESP01_estOcv_56_2 m13 : 50|14@1+ (0.001,0) [0|16.383] "Ah"  HVESP01
 SG_ HVESP01_estOcv_57_2 m14 : 8|14@1+ (0.001,0) [0|16.383] "Ah"  HVESP01
 SG_ HVESP01_estOcv_58_2 m14 : 22|14@1+ (0.001,0) [0|16.383] "Ah"  HVESP01
 SG_ HVESP01_estOcv_59_2 m14 : 36|14@1+ (0.001,0) [0|16.383] "Ah"  HVESP01
 SG_ HVESP01_estOcv_60_2 m14 : 50|14@1+ (0.001,0) [0|16.383] "Ah"  HVESP01
 SG_ HVESP01_estOcv_61_2 m15 : 8|14@1+ (0.001,0) [0|16.383] "Ah"  HVESP01
 SG_ HVESP01_estOcv_62_2 m15 : 22|14@1+ (0.001,0) [0|16.383] "Ah"  HVESP01
 SG_ HVESP01_estOcv_63_2 m15 : 36|14@1+ (0.001,0) [0|16.383] "Ah"  HVESP01
 SG_ HVESP01_estOcv_64_2 m15 : 50|14@1+ (0.001,0) [0|16.383] "Ah"  HVESP01
 SG_ HVESP01_estOcv_65_2 m16 : 8|14@1+ (0.001,0) [0|16.383] "Ah"  HVESP01
 SG_ HVESP01_estOcv_66_2 m16 : 22|14@1+ (0.001,0) [0|16.383] "Ah"  HVESP01
 SG_ HVESP01_estOcv_67_2 m16 : 36|14@1+ (0.001,0) [0|16.383] "Ah"  HVESP01
 SG_ HVESP01_estOcv_68_2 m16 : 50|14@1+ (0.001,0) [0|16.383] "Ah"  HVESP01
 SG_ HVESP01_estOcv_69_2 m17 : 8|14@1+ (0.001,0) [0|16.383] "Ah"  HVESP01
 SG_ HVESP01_estOcv_70_2 m17 : 22|14@1+ (0.001,0) [0|16.383] "Ah"  HVESP01
 SG_ HVESP01_estOcv_71_2 m17 : 36|14@1+ (0.001,0) [0|16.383] "Ah"  HVESP01
 SG_ HVESP01_estOcv_72_2 m17 : 50|14@1+ (0.001,0) [0|16.383] "Ah"  HVESP01
 SG_ HVESP01_estOcv_73_2 m18 : 8|14@1+ (0.001,0) [0|16.383] "Ah"  HVESP01
 SG_ HVESP01_estOcv_74_2 m18 : 22|14@1+ (0.001,0) [0|16.383] "Ah"  HVESP01
 SG_ HVESP01_estOcv_75_2 m18 : 36|14@1+ (0.001,0) [0|16.383] "Ah"  HVESP01
 SG_ HVESP01_estOcv_76_2 m18 : 50|14@1+ (0.001,0) [0|16.383] "Ah"  HVESP01
 SG_ HVESP01_estOcv_77_2 m19 : 8|14@1+ (0.001,0) [0|16.383] "Ah"  HVESP01
 SG_ HVESP01_estOcv_78_2 m19 : 22|14@1+ (0.001,0) [0|16.383] "Ah"  HVESP01
 SG_ HVESP01_estOcv_79_2 m19 : 36|14@1+ (0.001,0) [0|16.383] "Ah"  HVESP01
 SG_ HVESP01_estOcv_80_2 m19 : 50|14@1+ (0.001,0) [0|16.383] "Ah"  HVESP01
 SG_ HVESP01_estOcv_81_2 m20 : 8|14@1+ (0.001,0) [0|16.383] "Ah"  HVESP01
 SG_ HVESP01_estOcv_82_2 m20 : 22|14@1+ (0.001,0) [0|16.383] "Ah"  HVESP01
 SG_ HVESP01_estOcv_83_2 m20 : 36|14@1+ (0.001,0) [0|16.383] "Ah"  HVESP01
 SG_ HVESP01_estOcv_84_2 m20 : 50|14@1+ (0.001,0) [0|16.383] "Ah"  HVESP01
 SG_ HVESP01_estOcv_85_2 m21 : 8|14@1+ (0.001,0) [0|16.383] "Ah"  HVESP01
 SG_ HVESP01_estOcv_86_2 m21 : 22|14@1+ (0.001,0) [0|16.383] "Ah"  HVESP01
 SG_ HVESP01_estOcv_87_2 m21 : 36|14@1+ (0.001,0) [0|16.383] "Ah"  HVESP01
 SG_ HVESP01_estOcv_88_2 m21 : 50|14@1+ (0.001,0) [0|16.383] "Ah"  HVESP01
 SG_ HVESP01_estOcv_89_2 m22 : 8|14@1+ (0.001,0) [0|16.383] "Ah"  HVESP01
 SG_ HVESP01_estOcv_90_2 m22 : 22|14@1+ (0.001,0) [0|16.383] "Ah"  HVESP01
 SG_ HVESP01_estOcv_91_2 m22 : 36|14@1+ (0.001,0) [0|16.383] "Ah"  HVESP01
 SG_ HVESP01_estOcv_92_2 m22 : 50|14@1+ (0.001,0) [0|16.383] "Ah"  HVESP01
 SG_ HVESP01_estOcv_93_2 m23 : 8|14@1+ (0.001,0) [0|16.383] "Ah"  HVESP01
 SG_ HVESP01_estOcv_94_2 m23 : 22|14@1+ (0.001,0) [0|16.383] "Ah"  HVESP01
 SG_ HVESP01_estOcv_95_2 m23 : 36|14@1+ (0.001,0) [0|16.383] "Ah"  HVESP01
 SG_ HVESP01_estOcv_96_2 m23 : 50|14@1+ (0.001,0) [0|16.383] "Ah"  HVESP01
 SG_ HVESP01_estOcv_97_2 m24 : 8|14@1+ (0.001,0) [0|16.383] "Ah"  HVESP01
 SG_ HVESP01_estOcv_98_2 m24 : 22|14@1+ (0.001,0) [0|16.383] "Ah"  HVESP01
 SG_ HVESP01_estOcv_99_2 m24 : 36|14@1+ (0.001,0) [0|16.383] "Ah"  HVESP01
 SG_ HVESP01_estOcv_100_2 m24 : 50|14@1+ (0.001,0) [0|16.383] "Ah"  HVESP01
 SG_ HVESP01_estOcv_101_2 m25 : 8|14@1+ (0.001,0) [0|16.383] "Ah"  HVESP01
 SG_ HVESP01_estOcv_102_2 m25 : 22|14@1+ (0.001,0) [0|16.383] "Ah"  HVESP01
 SG_ HVESP01_estOcv_103_2 m25 : 36|14@1+ (0.001,0) [0|16.383] "Ah"  HVESP01
 SG_ HVESP01_estOcv_104_2 m25 : 50|14@1+ (0.001,0) [0|16.383] "Ah"  HVESP01
 SG_ HVESP01_estOcv_105_2 m26 : 8|14@1+ (0.001,0) [0|16.383] "Ah"  HVESP01
 SG_ HVESP01_estOcv_106_2 m26 : 22|14@1+ (0.001,0) [0|16.383] "Ah"  HVESP01
 SG_ HVESP01_estOcv_107_2 m26 : 36|14@1+ (0.001,0) [0|16.383] "Ah"  HVESP01
 SG_ HVESP01_estOcv_108_2 m26 : 50|14@1+ (0.001,0) [0|16.383] "Ah"  HVESP01
 SG_ HVESP01_estOcv_109_2 m27 : 8|14@1+ (0.001,0) [0|16.383] "Ah"  HVESP01
 SG_ HVESP01_estOcv_110_2 m27 : 22|14@1+ (0.001,0) [0|16.383] "Ah"  HVESP01
 SG_ HVESP01_estOcv_111_2 m27 : 36|14@1+ (0.001,0) [0|16.383] "Ah"  HVESP01
 SG_ HVESP01_estOcv_112_2 m27 : 50|14@1+ (0.001,0) [0|16.383] "Ah"  HVESP01
 SG_ HVESP01_estOcv_113_2 m28 : 8|14@1+ (0.001,0) [0|16.383] "Ah"  HVESP01
 SG_ HVESP01_estOcv_114_2 m28 : 22|14@1+ (0.001,0) [0|16.383] "Ah"  HVESP01
 SG_ HVESP01_estOcv_115_2 m28 : 36|14@1+ (0.001,0) [0|16.383] "Ah"  HVESP01
 SG_ HVESP01_estOcv_116_2 m28 : 50|14@1+ (0.001,0) [0|16.383] "Ah"  HVESP01
 SG_ HVESP01_estOcv_117_2 m29 : 8|14@1+ (0.001,0) [0|16.383] "Ah"  HVESP01
 SG_ HVESP01_estOcv_118_2 m29 : 22|14@1+ (0.001,0) [0|16.383] "Ah"  HVESP01
 SG_ HVESP01_estOcv_119_2 m29 : 36|14@1+ (0.001,0) [0|16.383] "Ah"  HVESP01
 SG_ HVESP01_estOcv_120_2 m29 : 50|14@1+ (0.001,0) [0|16.383] "Ah"  HVESP01
 SG_ HVESP01_estOcv_121_2 m30 : 8|14@1+ (0.001,0) [0|16.383] "Ah"  HVESP01
 SG_ HVESP01_estOcv_122_2 m30 : 22|14@1+ (0.001,0) [0|16.383] "Ah"  HVESP01
 SG_ HVESP01_estOcv_123_2 m30 : 36|14@1+ (0.001,0) [0|16.383] "Ah"  HVESP01
 SG_ HVESP01_estOcv_124_2 m30 : 50|14@1+ (0.001,0) [0|16.383] "Ah"  HVESP01
 SG_ HVESP01_estOcv_125_2 m31 : 8|14@1+ (0.001,0) [0|16.383] "Ah"  HVESP01
 SG_ HVESP01_estOcv_126_2 m31 : 22|14@1+ (0.001,0) [0|16.383] "Ah"  HVESP01
 SG_ HVESP01_estOcv_127_2 m31 : 36|14@1+ (0.001,0) [0|16.383] "Ah"  HVESP01
 SG_ HVESP01_estOcv_128_2 m31 : 50|14@1+ (0.001,0) [0|16.383] "Ah"  HVESP01
 SG_ HVESP01_estOcv_129_2 m32 : 8|14@1+ (0.001,0) [0|16.383] "Ah"  HVESP01
 SG_ HVESP01_estOcv_130_2 m32 : 22|14@1+ (0.001,0) [0|16.383] "Ah"  HVESP01
 SG_ HVESP01_estOcv_131_2 m32 : 36|14@1+ (0.001,0) [0|16.383] "Ah"  HVESP01
 SG_ HVESP01_estOcv_132_2 m32 : 50|14@1+ (0.001,0) [0|16.383] "Ah"  HVESP01
 SG_ HVESP01_estOcv_133_2 m33 : 8|14@1+ (0.001,0) [0|16.383] "Ah"  HVESP01
 SG_ HVESP01_estOcv_134_2 m33 : 22|14@1+ (0.001,0) [0|16.383] "Ah"  HVESP01
 SG_ HVESP01_estOcv_135_2 m33 : 36|14@1+ (0.001,0) [0|16.383] "Ah"  HVESP01
 SG_ HVESP01_estOcv_136_2 m33 : 50|14@1+ (0.001,0) [0|16.383] "Ah"  HVESP01
 SG_ HVESP01_estOcv_137_2 m34 : 8|14@1+ (0.001,0) [0|16.383] "Ah"  HVESP01
 SG_ HVESP01_estOcv_138_2 m34 : 22|14@1+ (0.001,0) [0|16.383] "Ah"  HVESP01
 SG_ HVESP01_estOcv_139_2 m34 : 36|14@1+ (0.001,0) [0|16.383] "Ah"  HVESP01
 SG_ HVESP01_estOcv_140_2 m34 : 50|14@1+ (0.001,0) [0|16.383] "Ah"  HVESP01
 SG_ HVESP01_estOcv_141_2 m35 : 8|14@1+ (0.001,0) [0|16.383] "Ah"  HVESP01
 SG_ HVESP01_estOcv_142_2 m35 : 22|14@1+ (0.001,0) [0|16.383] "Ah"  HVESP01
 SG_ HVESP01_estOcv_143_2 m35 : 36|14@1+ (0.001,0) [0|16.383] "Ah"  HVESP01
 SG_ HVESP01_estOcv_144_2 m35 : 50|14@1+ (0.001,0) [0|16.383] "Ah"  HVESP01
 SG_ HVESP01_estOcv_145_2 m36 : 8|14@1+ (0.001,0) [0|16.383] "Ah"  HVESP01
 SG_ HVESP01_estOcv_146_2 m36 : 22|14@1+ (0.001,0) [0|16.383] "Ah"  HVESP01
 SG_ HVESP01_estOcv_147_2 m36 : 36|14@1+ (0.001,0) [0|16.383] "Ah"  HVESP01
 SG_ HVESP01_estOcv_148_2 m36 : 50|14@1+ (0.001,0) [0|16.383] "Ah"  HVESP01
 SG_ HVESP01_estOcv_149_2 m37 : 8|14@1+ (0.001,0) [0|16.383] "Ah"  HVESP01
 SG_ HVESP01_estOcv_150_2 m37 : 22|14@1+ (0.001,0) [0|16.383] "Ah"  HVESP01
 SG_ HVESP01_estOcv_151_2 m37 : 36|14@1+ (0.001,0) [0|16.383] "Ah"  HVESP01
 SG_ HVESP01_estOcv_152_2 m37 : 50|14@1+ (0.001,0) [0|16.383] "Ah"  HVESP01
 SG_ HVESP01_estOcv_153_2 m38 : 8|14@1+ (0.001,0) [0|16.383] "Ah"  HVESP01
 SG_ HVESP01_estOcv_154_2 m38 : 22|14@1+ (0.001,0) [0|16.383] "Ah"  HVESP01
 SG_ HVESP01_estOcv_155_2 m38 : 36|14@1+ (0.001,0) [0|16.383] "Ah"  HVESP01
 SG_ HVESP01_estOcv_156_2 m38 : 50|14@1+ (0.001,0) [0|16.383] "Ah"  HVESP01
 SG_ HVESP01_estOcv_157_2 m39 : 8|14@1+ (0.001,0) [0|16.383] "Ah"  HVESP01
 SG_ HVESP01_estOcv_158_2 m39 : 22|14@1+ (0.001,0) [0|16.383] "Ah"  HVESP01
 SG_ HVESP01_estOcv_159_2 m39 : 36|14@1+ (0.001,0) [0|16.383] "Ah"  HVESP01
 SG_ HVESP01_estOcv_160_2 m39 : 50|14@1+ (0.001,0) [0|16.383] "Ah"  HVESP01
 SG_ HVESP01_estOcv_161_2 m40 : 8|14@1+ (0.001,0) [0|16.383] "Ah"  HVESP01
 SG_ HVESP01_estOcv_162_2 m40 : 22|14@1+ (0.001,0) [0|16.383] "Ah"  HVESP01
 SG_ HVESP01_estOcv_163_2 m40 : 36|14@1+ (0.001,0) [0|16.383] "Ah"  HVESP01
 SG_ HVESP01_estOcv_164_2 m40 : 50|14@1+ (0.001,0) [0|16.383] "Ah"  HVESP01
 SG_ HVESP01_estOcv_165_2 m41 : 8|14@1+ (0.001,0) [0|16.383] "Ah"  HVESP01
 SG_ HVESP01_estOcv_166_2 m41 : 22|14@1+ (0.001,0) [0|16.383] "Ah"  HVESP01
 SG_ HVESP01_estOcv_167_2 m41 : 36|14@1+ (0.001,0) [0|16.383] "Ah"  HVESP01
 SG_ HVESP01_estOcv_168_2 m41 : 50|14@1+ (0.001,0) [0|16.383] "Ah"  HVESP01
 SG_ HVESP01_estOcv_169_2 m42 : 8|14@1+ (0.001,0) [0|16.383] "Ah"  HVESP01
 SG_ HVESP01_estOcv_170_2 m42 : 22|14@1+ (0.001,0) [0|16.383] "Ah"  HVESP01
 SG_ HVESP01_estOcv_171_2 m42 : 36|14@1+ (0.001,0) [0|16.383] "Ah"  HVESP01
 SG_ HVESP01_estOcv_172_2 m42 : 50|14@1+ (0.001,0) [0|16.383] "Ah"  HVESP01
 SG_ HVESP01_estOcv_173_2 m43 : 8|14@1+ (0.001,0) [0|16.383] "Ah"  HVESP01
 SG_ HVESP01_estOcv_174_2 m43 : 22|14@1+ (0.001,0) [0|16.383] "Ah"  HVESP01
 SG_ HVESP01_estOcv_175_2 m43 : 36|14@1+ (0.001,0) [0|16.383] "Ah"  HVESP01
 SG_ HVESP01_estOcv_176_2 m43 : 50|14@1+ (0.001,0) [0|16.383] "Ah"  HVESP01
 SG_ HVESP01_estOcv_177_2 m44 : 8|14@1+ (0.001,0) [0|16.383] "Ah"  HVESP01
 SG_ HVESP01_estOcv_178_2 m44 : 22|14@1+ (0.001,0) [0|16.383] "Ah"  HVESP01
 SG_ HVESP01_estOcv_179_2 m44 : 36|14@1+ (0.001,0) [0|16.383] "Ah"  HVESP01
 SG_ HVESP01_estOcv_180_2 m44 : 50|14@1+ (0.001,0) [0|16.383] "Ah"  HVESP01
 SG_ multiplexoreo_2 M : 0|8@1+ (1,0) [0|255] ""  HVESP01

BO_ 2499750247 HVESP01_EstOcv_3: 8 HVESP01
 SG_ HVESP01_estOcv_01_3 m0 : 8|14@1+ (0.001,0) [0|16.383] "Ah"  HVESP01
 SG_ HVESP01_estOcv_02_3 m0 : 22|14@1+ (0.001,0) [0|16.383] "Ah"  HVESP01
 SG_ HVESP01_estOcv_03_3 m0 : 36|14@1+ (0.001,0) [0|16.383] "Ah"  HVESP01
 SG_ HVESP01_estOcv_04_3 m0 : 50|14@1+ (0.001,0) [0|16.383] "Ah"  HVESP01
 SG_ HVESP01_estOcv_05_3 m1 : 8|14@1+ (0.001,0) [0|16.383] "Ah"  HVESP01
 SG_ HVESP01_estOcv_06_3 m1 : 22|14@1+ (0.001,0) [0|16.383] "Ah"  HVESP01
 SG_ HVESP01_estOcv_07_3 m1 : 36|14@1+ (0.001,0) [0|16.383] "Ah"  HVESP01
 SG_ HVESP01_estOcv_08_3 m1 : 50|14@1+ (0.001,0) [0|16.383] "Ah"  HVESP01
 SG_ HVESP01_estOcv_09_3 m2 : 8|14@1+ (0.001,0) [0|16.383] "Ah"  HVESP01
 SG_ HVESP01_estOcv_10_3 m2 : 22|14@1+ (0.001,0) [0|16.383] "Ah"  HVESP01
 SG_ HVESP01_estOcv_11_3 m2 : 36|14@1+ (0.001,0) [0|16.383] "Ah"  HVESP01
 SG_ HVESP01_estOcv_12_3 m2 : 50|14@1+ (0.001,0) [0|16.383] "Ah"  HVESP01
 SG_ HVESP01_estOcv_13_3 m3 : 8|14@1+ (0.001,0) [0|16.383] "Ah"  HVESP01
 SG_ HVESP01_estOcv_14_3 m3 : 22|14@1+ (0.001,0) [0|16.383] "Ah"  HVESP01
 SG_ HVESP01_estOcv_15_3 m3 : 36|14@1+ (0.001,0) [0|16.383] "Ah"  HVESP01
 SG_ HVESP01_estOcv_16_3 m3 : 50|14@1+ (0.001,0) [0|16.383] "Ah"  HVESP01
 SG_ HVESP01_estOcv_17_3 m4 : 8|14@1+ (0.001,0) [0|16.383] "Ah"  HVESP01
 SG_ HVESP01_estOcv_18_3 m4 : 22|14@1+ (0.001,0) [0|16.383] "Ah"  HVESP01
 SG_ HVESP01_estOcv_19_3 m4 : 36|14@1+ (0.001,0) [0|16.383] "Ah"  HVESP01
 SG_ HVESP01_estOcv_20_3 m4 : 50|14@1+ (0.001,0) [0|16.383] "Ah"  HVESP01
 SG_ HVESP01_estOcv_21_3 m5 : 8|14@1+ (0.001,0) [0|16.383] "Ah"  HVESP01
 SG_ HVESP01_estOcv_22_3 m5 : 22|14@1+ (0.001,0) [0|16.383] "Ah"  HVESP01
 SG_ HVESP01_estOcv_23_3 m5 : 36|14@1+ (0.001,0) [0|16.383] "Ah"  HVESP01
 SG_ HVESP01_estOcv_24_3 m5 : 50|14@1+ (0.001,0) [0|16.383] "Ah"  HVESP01
 SG_ HVESP01_estOcv_25_3 m6 : 8|14@1+ (0.001,0) [0|16.383] "Ah"  HVESP01
 SG_ HVESP01_estOcv_26_3 m6 : 22|14@1+ (0.001,0) [0|16.383] "Ah"  HVESP01
 SG_ HVESP01_estOcv_27_3 m6 : 36|14@1+ (0.001,0) [0|16.383] "Ah"  HVESP01
 SG_ HVESP01_estOcv_28_3 m6 : 50|14@1+ (0.001,0) [0|16.383] "Ah"  HVESP01
 SG_ HVESP01_estOcv_29_3 m7 : 8|14@1+ (0.001,0) [0|16.383] "Ah"  HVESP01
 SG_ HVESP01_estOcv_30_3 m7 : 22|14@1+ (0.001,0) [0|16.383] "Ah"  HVESP01
 SG_ HVESP01_estOcv_31_3 m7 : 36|14@1+ (0.001,0) [0|16.383] "Ah"  HVESP01
 SG_ HVESP01_estOcv_32_3 m7 : 50|14@1+ (0.001,0) [0|16.383] "Ah"  HVESP01
 SG_ HVESP01_estOcv_33_3 m8 : 8|14@1+ (0.001,0) [0|16.383] "Ah"  HVESP01
 SG_ HVESP01_estOcv_34_3 m8 : 22|14@1+ (0.001,0) [0|16.383] "Ah"  HVESP01
 SG_ HVESP01_estOcv_35_3 m8 : 36|14@1+ (0.001,0) [0|16.383] "Ah"  HVESP01
 SG_ HVESP01_estOcv_36_3 m8 : 50|14@1+ (0.001,0) [0|16.383] "Ah"  HVESP01
 SG_ HVESP01_estOcv_37_3 m9 : 8|14@1+ (0.001,0) [0|16.383] "Ah"  HVESP01
 SG_ HVESP01_estOcv_38_3 m9 : 22|14@1+ (0.001,0) [0|16.383] "Ah"  HVESP01
 SG_ HVESP01_estOcv_39_3 m9 : 36|14@1+ (0.001,0) [0|16.383] "Ah"  HVESP01
 SG_ HVESP01_estOcv_40_3 m9 : 50|14@1+ (0.001,0) [0|16.383] "Ah"  HVESP01
 SG_ HVESP01_estOcv_41_3 m10 : 8|14@1+ (0.001,0) [0|16.383] "Ah"  HVESP01
 SG_ HVESP01_estOcv_42_3 m10 : 22|14@1+ (0.001,0) [0|16.383] "Ah"  HVESP01
 SG_ HVESP01_estOcv_43_3 m10 : 36|14@1+ (0.001,0) [0|16.383] "Ah"  HVESP01
 SG_ HVESP01_estOcv_44_3 m10 : 50|14@1+ (0.001,0) [0|16.383] "Ah"  HVESP01
 SG_ HVESP01_estOcv_45_3 m11 : 8|14@1+ (0.001,0) [0|16.383] "Ah"  HVESP01
 SG_ HVESP01_estOcv_46_3 m11 : 22|14@1+ (0.001,0) [0|16.383] "Ah"  HVESP01
 SG_ HVESP01_estOcv_47_3 m11 : 36|14@1+ (0.001,0) [0|16.383] "Ah"  HVESP01
 SG_ HVESP01_estOcv_48_3 m11 : 50|14@1+ (0.001,0) [0|16.383] "Ah"  HVESP01
 SG_ HVESP01_estOcv_49_3 m12 : 8|14@1+ (0.001,0) [0|16.383] "Ah"  HVESP01
 SG_ HVESP01_estOcv_50_3 m12 : 22|14@1+ (0.001,0) [0|16.383] "Ah"  HVESP01
 SG_ HVESP01_estOcv_51_3 m12 : 36|14@1+ (0.001,0) [0|16.383] "Ah"  HVESP01
 SG_ HVESP01_estOcv_52_3 m12 : 50|14@1+ (0.001,0) [0|16.383] "Ah"  HVESP01
 SG_ HVESP01_estOcv_53_3 m13 : 8|14@1+ (0.001,0) [0|16.383] "Ah"  HVESP01
 SG_ HVESP01_estOcv_54_3 m13 : 22|14@1+ (0.001,0) [0|16.383] "Ah"  HVESP01
 SG_ HVESP01_estOcv_55_3 m13 : 36|14@1+ (0.001,0) [0|16.383] "Ah"  HVESP01
 SG_ HVESP01_estOcv_56_3 m13 : 50|14@1+ (0.001,0) [0|16.383] "Ah"  HVESP01
 SG_ HVESP01_estOcv_57_3 m14 : 8|14@1+ (0.001,0) [0|16.383] "Ah"  HVESP01
 SG_ HVESP01_estOcv_58_3 m14 : 22|14@1+ (0.001,0) [0|16.383] "Ah"  HVESP01
 SG_ HVESP01_estOcv_59_3 m14 : 36|14@1+ (0.001,0) [0|16.383] "Ah"  HVESP01
 SG_ HVESP01_estOcv_60_3 m14 : 50|14@1+ (0.001,0) [0|16.383] "Ah"  HVESP01
 SG_ HVESP01_estOcv_61_3 m15 : 8|14@1+ (0.001,0) [0|16.383] "Ah"  HVESP01
 SG_ HVESP01_estOcv_62_3 m15 : 22|14@1+ (0.001,0) [0|16.383] "Ah"  HVESP01
 SG_ HVESP01_estOcv_63_3 m15 : 36|14@1+ (0.001,0) [0|16.383] "Ah"  HVESP01
 SG_ HVESP01_estOcv_64_3 m15 : 50|14@1+ (0.001,0) [0|16.383] "Ah"  HVESP01
 SG_ HVESP01_estOcv_65_3 m16 : 8|14@1+ (0.001,0) [0|16.383] "Ah"  HVESP01
 SG_ HVESP01_estOcv_66_3 m16 : 22|14@1+ (0.001,0) [0|16.383] "Ah"  HVESP01
 SG_ HVESP01_estOcv_67_3 m16 : 36|14@1+ (0.001,0) [0|16.383] "Ah"  HVESP01
 SG_ HVESP01_estOcv_68_3 m16 : 50|14@1+ (0.001,0) [0|16.383] "Ah"  HVESP01
 SG_ HVESP01_estOcv_69_3 m17 : 8|14@1+ (0.001,0) [0|16.383] "Ah"  HVESP01
 SG_ HVESP01_estOcv_70_3 m17 : 22|14@1+ (0.001,0) [0|16.383] "Ah"  HVESP01
 SG_ HVESP01_estOcv_71_3 m17 : 36|14@1+ (0.001,0) [0|16.383] "Ah"  HVESP01
 SG_ HVESP01_estOcv_72_3 m17 : 50|14@1+ (0.001,0) [0|16.383] "Ah"  HVESP01
 SG_ HVESP01_estOcv_73_3 m18 : 8|14@1+ (0.001,0) [0|16.383] "Ah"  HVESP01
 SG_ HVESP01_estOcv_74_3 m18 : 22|14@1+ (0.001,0) [0|16.383] "Ah"  HVESP01
 SG_ HVESP01_estOcv_75_3 m18 : 36|14@1+ (0.001,0) [0|16.383] "Ah"  HVESP01
 SG_ HVESP01_estOcv_76_3 m18 : 50|14@1+ (0.001,0) [0|16.383] "Ah"  HVESP01
 SG_ HVESP01_estOcv_77_3 m19 : 8|14@1+ (0.001,0) [0|16.383] "Ah"  HVESP01
 SG_ HVESP01_estOcv_78_3 m19 : 22|14@1+ (0.001,0) [0|16.383] "Ah"  HVESP01
 SG_ HVESP01_estOcv_79_3 m19 : 36|14@1+ (0.001,0) [0|16.383] "Ah"  HVESP01
 SG_ HVESP01_estOcv_80_3 m19 : 50|14@1+ (0.001,0) [0|16.383] "Ah"  HVESP01
 SG_ HVESP01_estOcv_81_3 m20 : 8|14@1+ (0.001,0) [0|16.383] "Ah"  HVESP01
 SG_ HVESP01_estOcv_82_3 m20 : 22|14@1+ (0.001,0) [0|16.383] "Ah"  HVESP01
 SG_ HVESP01_estOcv_83_3 m20 : 36|14@1+ (0.001,0) [0|16.383] "Ah"  HVESP01
 SG_ HVESP01_estOcv_84_3 m20 : 50|14@1+ (0.001,0) [0|16.383] "Ah"  HVESP01
 SG_ HVESP01_estOcv_85_3 m21 : 8|14@1+ (0.001,0) [0|16.383] "Ah"  HVESP01
 SG_ HVESP01_estOcv_86_3 m21 : 22|14@1+ (0.001,0) [0|16.383] "Ah"  HVESP01
 SG_ HVESP01_estOcv_87_3 m21 : 36|14@1+ (0.001,0) [0|16.383] "Ah"  HVESP01
 SG_ HVESP01_estOcv_88_3 m21 : 50|14@1+ (0.001,0) [0|16.383] "Ah"  HVESP01
 SG_ HVESP01_estOcv_89_3 m22 : 8|14@1+ (0.001,0) [0|16.383] "Ah"  HVESP01
 SG_ HVESP01_estOcv_90_3 m22 : 22|14@1+ (0.001,0) [0|16.383] "Ah"  HVESP01
 SG_ HVESP01_estOcv_91_3 m22 : 36|14@1+ (0.001,0) [0|16.383] "Ah"  HVESP01
 SG_ HVESP01_estOcv_92_3 m22 : 50|14@1+ (0.001,0) [0|16.383] "Ah"  HVESP01
 SG_ HVESP01_estOcv_93_3 m23 : 8|14@1+ (0.001,0) [0|16.383] "Ah"  HVESP01
 SG_ HVESP01_estOcv_94_3 m23 : 22|14@1+ (0.001,0) [0|16.383] "Ah"  HVESP01
 SG_ HVESP01_estOcv_95_3 m23 : 36|14@1+ (0.001,0) [0|16.383] "Ah"  HVESP01
 SG_ HVESP01_estOcv_96_3 m23 : 50|14@1+ (0.001,0) [0|16.383] "Ah"  HVESP01
 SG_ HVESP01_estOcv_97_3 m24 : 8|14@1+ (0.001,0) [0|16.383] "Ah"  HVESP01
 SG_ HVESP01_estOcv_98_3 m24 : 22|14@1+ (0.001,0) [0|16.383] "Ah"  HVESP01
 SG_ HVESP01_estOcv_99_3 m24 : 36|14@1+ (0.001,0) [0|16.383] "Ah"  HVESP01
 SG_ HVESP01_estOcv_100_3 m24 : 50|14@1+ (0.001,0) [0|16.383] "Ah"  HVESP01
 SG_ HVESP01_estOcv_101_3 m25 : 8|14@1+ (0.001,0) [0|16.383] "Ah"  HVESP01
 SG_ HVESP01_estOcv_102_3 m25 : 22|14@1+ (0.001,0) [0|16.383] "Ah"  HVESP01
 SG_ HVESP01_estOcv_103_3 m25 : 36|14@1+ (0.001,0) [0|16.383] "Ah"  HVESP01
 SG_ HVESP01_estOcv_104_3 m25 : 50|14@1+ (0.001,0) [0|16.383] "Ah"  HVESP01
 SG_ HVESP01_estOcv_105_3 m26 : 8|14@1+ (0.001,0) [0|16.383] "Ah"  HVESP01
 SG_ HVESP01_estOcv_106_3 m26 : 22|14@1+ (0.001,0) [0|16.383] "Ah"  HVESP01
 SG_ HVESP01_estOcv_107_3 m26 : 36|14@1+ (0.001,0) [0|16.383] "Ah"  HVESP01
 SG_ HVESP01_estOcv_108_3 m26 : 50|14@1+ (0.001,0) [0|16.383] "Ah"  HVESP01
 SG_ HVESP01_estOcv_109_3 m27 : 8|14@1+ (0.001,0) [0|16.383] "Ah"  HVESP01
 SG_ HVESP01_estOcv_110_3 m27 : 22|14@1+ (0.001,0) [0|16.383] "Ah"  HVESP01
 SG_ HVESP01_estOcv_111_3 m27 : 36|14@1+ (0.001,0) [0|16.383] "Ah"  HVESP01
 SG_ HVESP01_estOcv_112_3 m27 : 50|14@1+ (0.001,0) [0|16.383] "Ah"  HVESP01
 SG_ HVESP01_estOcv_113_3 m28 : 8|14@1+ (0.001,0) [0|16.383] "Ah"  HVESP01
 SG_ HVESP01_estOcv_114_3 m28 : 22|14@1+ (0.001,0) [0|16.383] "Ah"  HVESP01
 SG_ HVESP01_estOcv_115_3 m28 : 36|14@1+ (0.001,0) [0|16.383] "Ah"  HVESP01
 SG_ HVESP01_estOcv_116_3 m28 : 50|14@1+ (0.001,0) [0|16.383] "Ah"  HVESP01
 SG_ HVESP01_estOcv_117_3 m29 : 8|14@1+ (0.001,0) [0|16.383] "Ah"  HVESP01
 SG_ HVESP01_estOcv_118_3 m29 : 22|14@1+ (0.001,0) [0|16.383] "Ah"  HVESP01
 SG_ HVESP01_estOcv_119_3 m29 : 36|14@1+ (0.001,0) [0|16.383] "Ah"  HVESP01
 SG_ HVESP01_estOcv_120_3 m29 : 50|14@1+ (0.001,0) [0|16.383] "Ah"  HVESP01
 SG_ HVESP01_estOcv_121_3 m30 : 8|14@1+ (0.001,0) [0|16.383] "Ah"  HVESP01
 SG_ HVESP01_estOcv_122_3 m30 : 22|14@1+ (0.001,0) [0|16.383] "Ah"  HVESP01
 SG_ HVESP01_estOcv_123_3 m30 : 36|14@1+ (0.001,0) [0|16.383] "Ah"  HVESP01
 SG_ HVESP01_estOcv_124_3 m30 : 50|14@1+ (0.001,0) [0|16.383] "Ah"  HVESP01
 SG_ HVESP01_estOcv_125_3 m31 : 8|14@1+ (0.001,0) [0|16.383] "Ah"  HVESP01
 SG_ HVESP01_estOcv_126_3 m31 : 22|14@1+ (0.001,0) [0|16.383] "Ah"  HVESP01
 SG_ HVESP01_estOcv_127_3 m31 : 36|14@1+ (0.001,0) [0|16.383] "Ah"  HVESP01
 SG_ HVESP01_estOcv_128_3 m31 : 50|14@1+ (0.001,0) [0|16.383] "Ah"  HVESP01
 SG_ HVESP01_estOcv_129_3 m32 : 8|14@1+ (0.001,0) [0|16.383] "Ah"  HVESP01
 SG_ HVESP01_estOcv_130_3 m32 : 22|14@1+ (0.001,0) [0|16.383] "Ah"  HVESP01
 SG_ HVESP01_estOcv_131_3 m32 : 36|14@1+ (0.001,0) [0|16.383] "Ah"  HVESP01
 SG_ HVESP01_estOcv_132_3 m32 : 50|14@1+ (0.001,0) [0|16.383] "Ah"  HVESP01
 SG_ HVESP01_estOcv_133_3 m33 : 8|14@1+ (0.001,0) [0|16.383] "Ah"  HVESP01
 SG_ HVESP01_estOcv_134_3 m33 : 22|14@1+ (0.001,0) [0|16.383] "Ah"  HVESP01
 SG_ HVESP01_estOcv_135_3 m33 : 36|14@1+ (0.001,0) [0|16.383] "Ah"  HVESP01
 SG_ HVESP01_estOcv_136_3 m33 : 50|14@1+ (0.001,0) [0|16.383] "Ah"  HVESP01
 SG_ HVESP01_estOcv_137_3 m34 : 8|14@1+ (0.001,0) [0|16.383] "Ah"  HVESP01
 SG_ HVESP01_estOcv_138_3 m34 : 22|14@1+ (0.001,0) [0|16.383] "Ah"  HVESP01
 SG_ HVESP01_estOcv_139_3 m34 : 36|14@1+ (0.001,0) [0|16.383] "Ah"  HVESP01
 SG_ HVESP01_estOcv_140_3 m34 : 50|14@1+ (0.001,0) [0|16.383] "Ah"  HVESP01
 SG_ HVESP01_estOcv_141_3 m35 : 8|14@1+ (0.001,0) [0|16.383] "Ah"  HVESP01
 SG_ HVESP01_estOcv_142_3 m35 : 22|14@1+ (0.001,0) [0|16.383] "Ah"  HVESP01
 SG_ HVESP01_estOcv_143_3 m35 : 36|14@1+ (0.001,0) [0|16.383] "Ah"  HVESP01
 SG_ HVESP01_estOcv_144_3 m35 : 50|14@1+ (0.001,0) [0|16.383] "Ah"  HVESP01
 SG_ HVESP01_estOcv_145_3 m36 : 8|14@1+ (0.001,0) [0|16.383] "Ah"  HVESP01
 SG_ HVESP01_estOcv_146_3 m36 : 22|14@1+ (0.001,0) [0|16.383] "Ah"  HVESP01
 SG_ HVESP01_estOcv_147_3 m36 : 36|14@1+ (0.001,0) [0|16.383] "Ah"  HVESP01
 SG_ HVESP01_estOcv_148_3 m36 : 50|14@1+ (0.001,0) [0|16.383] "Ah"  HVESP01
 SG_ HVESP01_estOcv_149_3 m37 : 8|14@1+ (0.001,0) [0|16.383] "Ah"  HVESP01
 SG_ HVESP01_estOcv_150_3 m37 : 22|14@1+ (0.001,0) [0|16.383] "Ah"  HVESP01
 SG_ HVESP01_estOcv_151_3 m37 : 36|14@1+ (0.001,0) [0|16.383] "Ah"  HVESP01
 SG_ HVESP01_estOcv_152_3 m37 : 50|14@1+ (0.001,0) [0|16.383] "Ah"  HVESP01
 SG_ HVESP01_estOcv_153_3 m38 : 8|14@1+ (0.001,0) [0|16.383] "Ah"  HVESP01
 SG_ HVESP01_estOcv_154_3 m38 : 22|14@1+ (0.001,0) [0|16.383] "Ah"  HVESP01
 SG_ HVESP01_estOcv_155_3 m38 : 36|14@1+ (0.001,0) [0|16.383] "Ah"  HVESP01
 SG_ HVESP01_estOcv_156_3 m38 : 50|14@1+ (0.001,0) [0|16.383] "Ah"  HVESP01
 SG_ HVESP01_estOcv_157_3 m39 : 8|14@1+ (0.001,0) [0|16.383] "Ah"  HVESP01
 SG_ HVESP01_estOcv_158_3 m39 : 22|14@1+ (0.001,0) [0|16.383] "Ah"  HVESP01
 SG_ HVESP01_estOcv_159_3 m39 : 36|14@1+ (0.001,0) [0|16.383] "Ah"  HVESP01
 SG_ HVESP01_estOcv_160_3 m39 : 50|14@1+ (0.001,0) [0|16.383] "Ah"  HVESP01
 SG_ HVESP01_estOcv_161_3 m40 : 8|14@1+ (0.001,0) [0|16.383] "Ah"  HVESP01
 SG_ HVESP01_estOcv_162_3 m40 : 22|14@1+ (0.001,0) [0|16.383] "Ah"  HVESP01
 SG_ HVESP01_estOcv_163_3 m40 : 36|14@1+ (0.001,0) [0|16.383] "Ah"  HVESP01
 SG_ HVESP01_estOcv_164_3 m40 : 50|14@1+ (0.001,0) [0|16.383] "Ah"  HVESP01
 SG_ HVESP01_estOcv_165_3 m41 : 8|14@1+ (0.001,0) [0|16.383] "Ah"  HVESP01
 SG_ HVESP01_estOcv_166_3 m41 : 22|14@1+ (0.001,0) [0|16.383] "Ah"  HVESP01
 SG_ HVESP01_estOcv_167_3 m41 : 36|14@1+ (0.001,0) [0|16.383] "Ah"  HVESP01
 SG_ HVESP01_estOcv_168_3 m41 : 50|14@1+ (0.001,0) [0|16.383] "Ah"  HVESP01
 SG_ HVESP01_estOcv_169_3 m42 : 8|14@1+ (0.001,0) [0|16.383] "Ah"  HVESP01
 SG_ HVESP01_estOcv_170_3 m42 : 22|14@1+ (0.001,0) [0|16.383] "Ah"  HVESP01
 SG_ HVESP01_estOcv_171_3 m42 : 36|14@1+ (0.001,0) [0|16.383] "Ah"  HVESP01
 SG_ HVESP01_estOcv_172_3 m42 : 50|14@1+ (0.001,0) [0|16.383] "Ah"  HVESP01
 SG_ HVESP01_estOcv_173_3 m43 : 8|14@1+ (0.001,0) [0|16.383] "Ah"  HVESP01
 SG_ HVESP01_estOcv_174_3 m43 : 22|14@1+ (0.001,0) [0|16.383] "Ah"  HVESP01
 SG_ HVESP01_estOcv_175_3 m43 : 36|14@1+ (0.001,0) [0|16.383] "Ah"  HVESP01
 SG_ HVESP01_estOcv_176_3 m43 : 50|14@1+ (0.001,0) [0|16.383] "Ah"  HVESP01
 SG_ HVESP01_estOcv_177_3 m44 : 8|14@1+ (0.001,0) [0|16.383] "Ah"  HVESP01
 SG_ HVESP01_estOcv_178_3 m44 : 22|14@1+ (0.001,0) [0|16.383] "Ah"  HVESP01
 SG_ HVESP01_estOcv_179_3 m44 : 36|14@1+ (0.001,0) [0|16.383] "Ah"  HVESP01
 SG_ HVESP01_estOcv_180_3 m44 : 50|14@1+ (0.001,0) [0|16.383] "Ah"  HVESP01
 SG_ multiplexoreo_3 M : 0|8@1+ (1,0) [0|255] ""  HVESP01

BO_ 2499750248 HVESP01_EstOcv_4: 8 HVESP01
 SG_ HVESP01_estOcv_01_4 m0 : 8|14@1+ (0.001,0) [0|16.383] "Ah"  HVESP01
 SG_ HVESP01_estOcv_02_4 m0 : 22|14@1+ (0.001,0) [0|16.383] "Ah"  HVESP01
 SG_ HVESP01_estOcv_03_4 m0 : 36|14@1+ (0.001,0) [0|16.383] "Ah"  HVESP01
 SG_ HVESP01_estOcv_04_4 m0 : 50|14@1+ (0.001,0) [0|16.383] "Ah"  HVESP01
 SG_ HVESP01_estOcv_05_4 m1 : 8|14@1+ (0.001,0) [0|16.383] "Ah"  HVESP01
 SG_ HVESP01_estOcv_06_4 m1 : 22|14@1+ (0.001,0) [0|16.383] "Ah"  HVESP01
 SG_ HVESP01_estOcv_07_4 m1 : 36|14@1+ (0.001,0) [0|16.383] "Ah"  HVESP01
 SG_ HVESP01_estOcv_08_4 m1 : 50|14@1+ (0.001,0) [0|16.383] "Ah"  HVESP01
 SG_ HVESP01_estOcv_09_4 m2 : 8|14@1+ (0.001,0) [0|16.383] "Ah"  HVESP01
 SG_ HVESP01_estOcv_10_4 m2 : 22|14@1+ (0.001,0) [0|16.383] "Ah"  HVESP01
 SG_ HVESP01_estOcv_11_4 m2 : 36|14@1+ (0.001,0) [0|16.383] "Ah"  HVESP01
 SG_ HVESP01_estOcv_12_4 m2 : 50|14@1+ (0.001,0) [0|16.383] "Ah"  HVESP01
 SG_ HVESP01_estOcv_13_4 m3 : 8|14@1+ (0.001,0) [0|16.383] "Ah"  HVESP01
 SG_ HVESP01_estOcv_14_4 m3 : 22|14@1+ (0.001,0) [0|16.383] "Ah"  HVESP01
 SG_ HVESP01_estOcv_15_4 m3 : 36|14@1+ (0.001,0) [0|16.383] "Ah"  HVESP01
 SG_ HVESP01_estOcv_16_4 m3 : 50|14@1+ (0.001,0) [0|16.383] "Ah"  HVESP01
 SG_ HVESP01_estOcv_17_4 m4 : 8|14@1+ (0.001,0) [0|16.383] "Ah"  HVESP01
 SG_ HVESP01_estOcv_18_4 m4 : 22|14@1+ (0.001,0) [0|16.383] "Ah"  HVESP01
 SG_ HVESP01_estOcv_19_4 m4 : 36|14@1+ (0.001,0) [0|16.383] "Ah"  HVESP01
 SG_ HVESP01_estOcv_20_4 m4 : 50|14@1+ (0.001,0) [0|16.383] "Ah"  HVESP01
 SG_ HVESP01_estOcv_21_4 m5 : 8|14@1+ (0.001,0) [0|16.383] "Ah"  HVESP01
 SG_ HVESP01_estOcv_22_4 m5 : 22|14@1+ (0.001,0) [0|16.383] "Ah"  HVESP01
 SG_ HVESP01_estOcv_23_4 m5 : 36|14@1+ (0.001,0) [0|16.383] "Ah"  HVESP01
 SG_ HVESP01_estOcv_24_4 m5 : 50|14@1+ (0.001,0) [0|16.383] "Ah"  HVESP01
 SG_ HVESP01_estOcv_25_4 m6 : 8|14@1+ (0.001,0) [0|16.383] "Ah"  HVESP01
 SG_ HVESP01_estOcv_26_4 m6 : 22|14@1+ (0.001,0) [0|16.383] "Ah"  HVESP01
 SG_ HVESP01_estOcv_27_4 m6 : 36|14@1+ (0.001,0) [0|16.383] "Ah"  HVESP01
 SG_ HVESP01_estOcv_28_4 m6 : 50|14@1+ (0.001,0) [0|16.383] "Ah"  HVESP01
 SG_ HVESP01_estOcv_29_4 m7 : 8|14@1+ (0.001,0) [0|16.383] "Ah"  HVESP01
 SG_ HVESP01_estOcv_30_4 m7 : 22|14@1+ (0.001,0) [0|16.383] "Ah"  HVESP01
 SG_ HVESP01_estOcv_31_4 m7 : 36|14@1+ (0.001,0) [0|16.383] "Ah"  HVESP01
 SG_ HVESP01_estOcv_32_4 m7 : 50|14@1+ (0.001,0) [0|16.383] "Ah"  HVESP01
 SG_ HVESP01_estOcv_33_4 m8 : 8|14@1+ (0.001,0) [0|16.383] "Ah"  HVESP01
 SG_ HVESP01_estOcv_34_4 m8 : 22|14@1+ (0.001,0) [0|16.383] "Ah"  HVESP01
 SG_ HVESP01_estOcv_35_4 m8 : 36|14@1+ (0.001,0) [0|16.383] "Ah"  HVESP01
 SG_ HVESP01_estOcv_36_4 m8 : 50|14@1+ (0.001,0) [0|16.383] "Ah"  HVESP01
 SG_ HVESP01_estOcv_37_4 m9 : 8|14@1+ (0.001,0) [0|16.383] "Ah"  HVESP01
 SG_ HVESP01_estOcv_38_4 m9 : 22|14@1+ (0.001,0) [0|16.383] "Ah"  HVESP01
 SG_ HVESP01_estOcv_39_4 m9 : 36|14@1+ (0.001,0) [0|16.383] "Ah"  HVESP01
 SG_ HVESP01_estOcv_40_4 m9 : 50|14@1+ (0.001,0) [0|16.383] "Ah"  HVESP01
 SG_ HVESP01_estOcv_41_4 m10 : 8|14@1+ (0.001,0) [0|16.383] "Ah"  HVESP01
 SG_ HVESP01_estOcv_42_4 m10 : 22|14@1+ (0.001,0) [0|16.383] "Ah"  HVESP01
 SG_ HVESP01_estOcv_43_4 m10 : 36|14@1+ (0.001,0) [0|16.383] "Ah"  HVESP01
 SG_ HVESP01_estOcv_44_4 m10 : 50|14@1+ (0.001,0) [0|16.383] "Ah"  HVESP01
 SG_ HVESP01_estOcv_45_4 m11 : 8|14@1+ (0.001,0) [0|16.383] "Ah"  HVESP01
 SG_ HVESP01_estOcv_46_4 m11 : 22|14@1+ (0.001,0) [0|16.383] "Ah"  HVESP01
 SG_ HVESP01_estOcv_47_4 m11 : 36|14@1+ (0.001,0) [0|16.383] "Ah"  HVESP01
 SG_ HVESP01_estOcv_48_4 m11 : 50|14@1+ (0.001,0) [0|16.383] "Ah"  HVESP01
 SG_ HVESP01_estOcv_49_4 m12 : 8|14@1+ (0.001,0) [0|16.383] "Ah"  HVESP01
 SG_ HVESP01_estOcv_50_4 m12 : 22|14@1+ (0.001,0) [0|16.383] "Ah"  HVESP01
 SG_ HVESP01_estOcv_51_4 m12 : 36|14@1+ (0.001,0) [0|16.383] "Ah"  HVESP01
 SG_ HVESP01_estOcv_52_4 m12 : 50|14@1+ (0.001,0) [0|16.383] "Ah"  HVESP01
 SG_ HVESP01_estOcv_53_4 m13 : 8|14@1+ (0.001,0) [0|16.383] "Ah"  HVESP01
 SG_ HVESP01_estOcv_54_4 m13 : 22|14@1+ (0.001,0) [0|16.383] "Ah"  HVESP01
 SG_ HVESP01_estOcv_55_4 m13 : 36|14@1+ (0.001,0) [0|16.383] "Ah"  HVESP01
 SG_ HVESP01_estOcv_56_4 m13 : 50|14@1+ (0.001,0) [0|16.383] "Ah"  HVESP01
 SG_ HVESP01_estOcv_57_4 m14 : 8|14@1+ (0.001,0) [0|16.383] "Ah"  HVESP01
 SG_ HVESP01_estOcv_58_4 m14 : 22|14@1+ (0.001,0) [0|16.383] "Ah"  HVESP01
 SG_ HVESP01_estOcv_59_4 m14 : 36|14@1+ (0.001,0) [0|16.383] "Ah"  HVESP01
 SG_ HVESP01_estOcv_60_4 m14 : 50|14@1+ (0.001,0) [0|16.383] "Ah"  HVESP01
 SG_ HVESP01_estOcv_61_4 m15 : 8|14@1+ (0.001,0) [0|16.383] "Ah"  HVESP01
 SG_ HVESP01_estOcv_62_4 m15 : 22|14@1+ (0.001,0) [0|16.383] "Ah"  HVESP01
 SG_ HVESP01_estOcv_63_4 m15 : 36|14@1+ (0.001,0) [0|16.383] "Ah"  HVESP01
 SG_ HVESP01_estOcv_64_4 m15 : 50|14@1+ (0.001,0) [0|16.383] "Ah"  HVESP01
 SG_ HVESP01_estOcv_65_4 m16 : 8|14@1+ (0.001,0) [0|16.383] "Ah"  HVESP01
 SG_ HVESP01_estOcv_66_4 m16 : 22|14@1+ (0.001,0) [0|16.383] "Ah"  HVESP01
 SG_ HVESP01_estOcv_67_4 m16 : 36|14@1+ (0.001,0) [0|16.383] "Ah"  HVESP01
 SG_ HVESP01_estOcv_68_4 m16 : 50|14@1+ (0.001,0) [0|16.383] "Ah"  HVESP01
 SG_ HVESP01_estOcv_69_4 m17 : 8|14@1+ (0.001,0) [0|16.383] "Ah"  HVESP01
 SG_ HVESP01_estOcv_70_4 m17 : 22|14@1+ (0.001,0) [0|16.383] "Ah"  HVESP01
 SG_ HVESP01_estOcv_71_4 m17 : 36|14@1+ (0.001,0) [0|16.383] "Ah"  HVESP01
 SG_ HVESP01_estOcv_72_4 m17 : 50|14@1+ (0.001,0) [0|16.383] "Ah"  HVESP01
 SG_ HVESP01_estOcv_73_4 m18 : 8|14@1+ (0.001,0) [0|16.383] "Ah"  HVESP01
 SG_ HVESP01_estOcv_74_4 m18 : 22|14@1+ (0.001,0) [0|16.383] "Ah"  HVESP01
 SG_ HVESP01_estOcv_75_4 m18 : 36|14@1+ (0.001,0) [0|16.383] "Ah"  HVESP01
 SG_ HVESP01_estOcv_76_4 m18 : 50|14@1+ (0.001,0) [0|16.383] "Ah"  HVESP01
 SG_ HVESP01_estOcv_77_4 m19 : 8|14@1+ (0.001,0) [0|16.383] "Ah"  HVESP01
 SG_ HVESP01_estOcv_78_4 m19 : 22|14@1+ (0.001,0) [0|16.383] "Ah"  HVESP01
 SG_ HVESP01_estOcv_79_4 m19 : 36|14@1+ (0.001,0) [0|16.383] "Ah"  HVESP01
 SG_ HVESP01_estOcv_80_4 m19 : 50|14@1+ (0.001,0) [0|16.383] "Ah"  HVESP01
 SG_ HVESP01_estOcv_81_4 m20 : 8|14@1+ (0.001,0) [0|16.383] "Ah"  HVESP01
 SG_ HVESP01_estOcv_82_4 m20 : 22|14@1+ (0.001,0) [0|16.383] "Ah"  HVESP01
 SG_ HVESP01_estOcv_83_4 m20 : 36|14@1+ (0.001,0) [0|16.383] "Ah"  HVESP01
 SG_ HVESP01_estOcv_84_4 m20 : 50|14@1+ (0.001,0) [0|16.383] "Ah"  HVESP01
 SG_ HVESP01_estOcv_85_4 m21 : 8|14@1+ (0.001,0) [0|16.383] "Ah"  HVESP01
 SG_ HVESP01_estOcv_86_4 m21 : 22|14@1+ (0.001,0) [0|16.383] "Ah"  HVESP01
 SG_ HVESP01_estOcv_87_4 m21 : 36|14@1+ (0.001,0) [0|16.383] "Ah"  HVESP01
 SG_ HVESP01_estOcv_88_4 m21 : 50|14@1+ (0.001,0) [0|16.383] "Ah"  HVESP01
 SG_ HVESP01_estOcv_89_4 m22 : 8|14@1+ (0.001,0) [0|16.383] "Ah"  HVESP01
 SG_ HVESP01_estOcv_90_4 m22 : 22|14@1+ (0.001,0) [0|16.383] "Ah"  HVESP01
 SG_ HVESP01_estOcv_91_4 m22 : 36|14@1+ (0.001,0) [0|16.383] "Ah"  HVESP01
 SG_ HVESP01_estOcv_92_4 m22 : 50|14@1+ (0.001,0) [0|16.383] "Ah"  HVESP01
 SG_ HVESP01_estOcv_93_4 m23 : 8|14@1+ (0.001,0) [0|16.383] "Ah"  HVESP01
 SG_ HVESP01_estOcv_94_4 m23 : 22|14@1+ (0.001,0) [0|16.383] "Ah"  HVESP01
 SG_ HVESP01_estOcv_95_4 m23 : 36|14@1+ (0.001,0) [0|16.383] "Ah"  HVESP01
 SG_ HVESP01_estOcv_96_4 m23 : 50|14@1+ (0.001,0) [0|16.383] "Ah"  HVESP01
 SG_ HVESP01_estOcv_97_4 m24 : 8|14@1+ (0.001,0) [0|16.383] "Ah"  HVESP01
 SG_ HVESP01_estOcv_98_4 m24 : 22|14@1+ (0.001,0) [0|16.383] "Ah"  HVESP01
 SG_ HVESP01_estOcv_99_4 m24 : 36|14@1+ (0.001,0) [0|16.383] "Ah"  HVESP01
 SG_ HVESP01_estOcv_100_4 m24 : 50|14@1+ (0.001,0) [0|16.383] "Ah"  HVESP01
 SG_ HVESP01_estOcv_101_4 m25 : 8|14@1+ (0.001,0) [0|16.383] "Ah"  HVESP01
 SG_ HVESP01_estOcv_102_4 m25 : 22|14@1+ (0.001,0) [0|16.383] "Ah"  HVESP01
 SG_ HVESP01_estOcv_103_4 m25 : 36|14@1+ (0.001,0) [0|16.383] "Ah"  HVESP01
 SG_ HVESP01_estOcv_104_4 m25 : 50|14@1+ (0.001,0) [0|16.383] "Ah"  HVESP01
 SG_ HVESP01_estOcv_105_4 m26 : 8|14@1+ (0.001,0) [0|16.383] "Ah"  HVESP01
 SG_ HVESP01_estOcv_106_4 m26 : 22|14@1+ (0.001,0) [0|16.383] "Ah"  HVESP01
 SG_ HVESP01_estOcv_107_4 m26 : 36|14@1+ (0.001,0) [0|16.383] "Ah"  HVESP01
 SG_ HVESP01_estOcv_108_4 m26 : 50|14@1+ (0.001,0) [0|16.383] "Ah"  HVESP01
 SG_ HVESP01_estOcv_109_4 m27 : 8|14@1+ (0.001,0) [0|16.383] "Ah"  HVESP01
 SG_ HVESP01_estOcv_110_4 m27 : 22|14@1+ (0.001,0) [0|16.383] "Ah"  HVESP01
 SG_ HVESP01_estOcv_111_4 m27 : 36|14@1+ (0.001,0) [0|16.383] "Ah"  HVESP01
 SG_ HVESP01_estOcv_112_4 m27 : 50|14@1+ (0.001,0) [0|16.383] "Ah"  HVESP01
 SG_ HVESP01_estOcv_113_4 m28 : 8|14@1+ (0.001,0) [0|16.383] "Ah"  HVESP01
 SG_ HVESP01_estOcv_114_4 m28 : 22|14@1+ (0.001,0) [0|16.383] "Ah"  HVESP01
 SG_ HVESP01_estOcv_115_4 m28 : 36|14@1+ (0.001,0) [0|16.383] "Ah"  HVESP01
 SG_ HVESP01_estOcv_116_4 m28 : 50|14@1+ (0.001,0) [0|16.383] "Ah"  HVESP01
 SG_ HVESP01_estOcv_117_4 m29 : 8|14@1+ (0.001,0) [0|16.383] "Ah"  HVESP01
 SG_ HVESP01_estOcv_118_4 m29 : 22|14@1+ (0.001,0) [0|16.383] "Ah"  HVESP01
 SG_ HVESP01_estOcv_119_4 m29 : 36|14@1+ (0.001,0) [0|16.383] "Ah"  HVESP01
 SG_ HVESP01_estOcv_120_4 m29 : 50|14@1+ (0.001,0) [0|16.383] "Ah"  HVESP01
 SG_ HVESP01_estOcv_121_4 m30 : 8|14@1+ (0.001,0) [0|16.383] "Ah"  HVESP01
 SG_ HVESP01_estOcv_122_4 m30 : 22|14@1+ (0.001,0) [0|16.383] "Ah"  HVESP01
 SG_ HVESP01_estOcv_123_4 m30 : 36|14@1+ (0.001,0) [0|16.383] "Ah"  HVESP01
 SG_ HVESP01_estOcv_124_4 m30 : 50|14@1+ (0.001,0) [0|16.383] "Ah"  HVESP01
 SG_ HVESP01_estOcv_125_4 m31 : 8|14@1+ (0.001,0) [0|16.383] "Ah"  HVESP01
 SG_ HVESP01_estOcv_126_4 m31 : 22|14@1+ (0.001,0) [0|16.383] "Ah"  HVESP01
 SG_ HVESP01_estOcv_127_4 m31 : 36|14@1+ (0.001,0) [0|16.383] "Ah"  HVESP01
 SG_ HVESP01_estOcv_128_4 m31 : 50|14@1+ (0.001,0) [0|16.383] "Ah"  HVESP01
 SG_ HVESP01_estOcv_129_4 m32 : 8|14@1+ (0.001,0) [0|16.383] "Ah"  HVESP01
 SG_ HVESP01_estOcv_130_4 m32 : 22|14@1+ (0.001,0) [0|16.383] "Ah"  HVESP01
 SG_ HVESP01_estOcv_131_4 m32 : 36|14@1+ (0.001,0) [0|16.383] "Ah"  HVESP01
 SG_ HVESP01_estOcv_132_4 m32 : 50|14@1+ (0.001,0) [0|16.383] "Ah"  HVESP01
 SG_ HVESP01_estOcv_133_4 m33 : 8|14@1+ (0.001,0) [0|16.383] "Ah"  HVESP01
 SG_ HVESP01_estOcv_134_4 m33 : 22|14@1+ (0.001,0) [0|16.383] "Ah"  HVESP01
 SG_ HVESP01_estOcv_135_4 m33 : 36|14@1+ (0.001,0) [0|16.383] "Ah"  HVESP01
 SG_ HVESP01_estOcv_136_4 m33 : 50|14@1+ (0.001,0) [0|16.383] "Ah"  HVESP01
 SG_ HVESP01_estOcv_137_4 m34 : 8|14@1+ (0.001,0) [0|16.383] "Ah"  HVESP01
 SG_ HVESP01_estOcv_138_4 m34 : 22|14@1+ (0.001,0) [0|16.383] "Ah"  HVESP01
 SG_ HVESP01_estOcv_139_4 m34 : 36|14@1+ (0.001,0) [0|16.383] "Ah"  HVESP01
 SG_ HVESP01_estOcv_140_4 m34 : 50|14@1+ (0.001,0) [0|16.383] "Ah"  HVESP01
 SG_ HVESP01_estOcv_141_4 m35 : 8|14@1+ (0.001,0) [0|16.383] "Ah"  HVESP01
 SG_ HVESP01_estOcv_142_4 m35 : 22|14@1+ (0.001,0) [0|16.383] "Ah"  HVESP01
 SG_ HVESP01_estOcv_143_4 m35 : 36|14@1+ (0.001,0) [0|16.383] "Ah"  HVESP01
 SG_ HVESP01_estOcv_144_4 m35 : 50|14@1+ (0.001,0) [0|16.383] "Ah"  HVESP01
 SG_ HVESP01_estOcv_145_4 m36 : 8|14@1+ (0.001,0) [0|16.383] "Ah"  HVESP01
 SG_ HVESP01_estOcv_146_4 m36 : 22|14@1+ (0.001,0) [0|16.383] "Ah"  HVESP01
 SG_ HVESP01_estOcv_147_4 m36 : 36|14@1+ (0.001,0) [0|16.383] "Ah"  HVESP01
 SG_ HVESP01_estOcv_148_4 m36 : 50|14@1+ (0.001,0) [0|16.383] "Ah"  HVESP01
 SG_ HVESP01_estOcv_149_4 m37 : 8|14@1+ (0.001,0) [0|16.383] "Ah"  HVESP01
 SG_ HVESP01_estOcv_150_4 m37 : 22|14@1+ (0.001,0) [0|16.383] "Ah"  HVESP01
 SG_ HVESP01_estOcv_151_4 m37 : 36|14@1+ (0.001,0) [0|16.383] "Ah"  HVESP01
 SG_ HVESP01_estOcv_152_4 m37 : 50|14@1+ (0.001,0) [0|16.383] "Ah"  HVESP01
 SG_ HVESP01_estOcv_153_4 m38 : 8|14@1+ (0.001,0) [0|16.383] "Ah"  HVESP01
 SG_ HVESP01_estOcv_154_4 m38 : 22|14@1+ (0.001,0) [0|16.383] "Ah"  HVESP01
 SG_ HVESP01_estOcv_155_4 m38 : 36|14@1+ (0.001,0) [0|16.383] "Ah"  HVESP01
 SG_ HVESP01_estOcv_156_4 m38 : 50|14@1+ (0.001,0) [0|16.383] "Ah"  HVESP01
 SG_ HVESP01_estOcv_157_4 m39 : 8|14@1+ (0.001,0) [0|16.383] "Ah"  HVESP01
 SG_ HVESP01_estOcv_158_4 m39 : 22|14@1+ (0.001,0) [0|16.383] "Ah"  HVESP01
 SG_ HVESP01_estOcv_159_4 m39 : 36|14@1+ (0.001,0) [0|16.383] "Ah"  HVESP01
 SG_ HVESP01_estOcv_160_4 m39 : 50|14@1+ (0.001,0) [0|16.383] "Ah"  HVESP01
 SG_ HVESP01_estOcv_161_4 m40 : 8|14@1+ (0.001,0) [0|16.383] "Ah"  HVESP01
 SG_ HVESP01_estOcv_162_4 m40 : 22|14@1+ (0.001,0) [0|16.383] "Ah"  HVESP01
 SG_ HVESP01_estOcv_163_4 m40 : 36|14@1+ (0.001,0) [0|16.383] "Ah"  HVESP01
 SG_ HVESP01_estOcv_164_4 m40 : 50|14@1+ (0.001,0) [0|16.383] "Ah"  HVESP01
 SG_ HVESP01_estOcv_165_4 m41 : 8|14@1+ (0.001,0) [0|16.383] "Ah"  HVESP01
 SG_ HVESP01_estOcv_166_4 m41 : 22|14@1+ (0.001,0) [0|16.383] "Ah"  HVESP01
 SG_ HVESP01_estOcv_167_4 m41 : 36|14@1+ (0.001,0) [0|16.383] "Ah"  HVESP01
 SG_ HVESP01_estOcv_168_4 m41 : 50|14@1+ (0.001,0) [0|16.383] "Ah"  HVESP01
 SG_ HVESP01_estOcv_169_4 m42 : 8|14@1+ (0.001,0) [0|16.383] "Ah"  HVESP01
 SG_ HVESP01_estOcv_170_4 m42 : 22|14@1+ (0.001,0) [0|16.383] "Ah"  HVESP01
 SG_ HVESP01_estOcv_171_4 m42 : 36|14@1+ (0.001,0) [0|16.383] "Ah"  HVESP01
 SG_ HVESP01_estOcv_172_4 m42 : 50|14@1+ (0.001,0) [0|16.383] "Ah"  HVESP01
 SG_ HVESP01_estOcv_173_4 m43 : 8|14@1+ (0.001,0) [0|16.383] "Ah"  HVESP01
 SG_ HVESP01_estOcv_174_4 m43 : 22|14@1+ (0.001,0) [0|16.383] "Ah"  HVESP01
 SG_ HVESP01_estOcv_175_4 m43 : 36|14@1+ (0.001,0) [0|16.383] "Ah"  HVESP01
 SG_ HVESP01_estOcv_176_4 m43 : 50|14@1+ (0.001,0) [0|16.383] "Ah"  HVESP01
 SG_ HVESP01_estOcv_177_4 m44 : 8|14@1+ (0.001,0) [0|16.383] "Ah"  HVESP01
 SG_ HVESP01_estOcv_178_4 m44 : 22|14@1+ (0.001,0) [0|16.383] "Ah"  HVESP01
 SG_ HVESP01_estOcv_179_4 m44 : 36|14@1+ (0.001,0) [0|16.383] "Ah"  HVESP01
 SG_ HVESP01_estOcv_180_4 m44 : 50|14@1+ (0.001,0) [0|16.383] "Ah"  HVESP01
 SG_ multiplexoreo_4 M : 0|8@1+ (1,0) [0|255] ""  HVESP01

BO_ 2499750249 HVESP01_EstOcv_5: 8 HVESP01
 SG_ HVESP01_estOcv_01_5 m0 : 8|14@1+ (0.001,0) [0|16.383] "Ah"  HVESP01
 SG_ HVESP01_estOcv_02_5 m0 : 22|14@1+ (0.001,0) [0|16.383] "Ah"  HVESP01
 SG_ HVESP01_estOcv_03_5 m0 : 36|14@1+ (0.001,0) [0|16.383] "Ah"  HVESP01
 SG_ HVESP01_estOcv_04_5 m0 : 50|14@1+ (0.001,0) [0|16.383] "Ah"  HVESP01
 SG_ HVESP01_estOcv_05_5 m1 : 8|14@1+ (0.001,0) [0|16.383] "Ah"  HVESP01
 SG_ HVESP01_estOcv_06_5 m1 : 22|14@1+ (0.001,0) [0|16.383] "Ah"  HVESP01
 SG_ HVESP01_estOcv_07_5 m1 : 36|14@1+ (0.001,0) [0|16.383] "Ah"  HVESP01
 SG_ HVESP01_estOcv_08_5 m1 : 50|14@1+ (0.001,0) [0|16.383] "Ah"  HVESP01
 SG_ HVESP01_estOcv_09_5 m2 : 8|14@1+ (0.001,0) [0|16.383] "Ah"  HVESP01
 SG_ HVESP01_estOcv_10_5 m2 : 22|14@1+ (0.001,0) [0|16.383] "Ah"  HVESP01
 SG_ HVESP01_estOcv_11_5 m2 : 36|14@1+ (0.001,0) [0|16.383] "Ah"  HVESP01
 SG_ HVESP01_estOcv_12_5 m2 : 50|14@1+ (0.001,0) [0|16.383] "Ah"  HVESP01
 SG_ HVESP01_estOcv_13_5 m3 : 8|14@1+ (0.001,0) [0|16.383] "Ah"  HVESP01
 SG_ HVESP01_estOcv_14_5 m3 : 22|14@1+ (0.001,0) [0|16.383] "Ah"  HVESP01
 SG_ HVESP01_estOcv_15_5 m3 : 36|14@1+ (0.001,0) [0|16.383] "Ah"  HVESP01
 SG_ HVESP01_estOcv_16_5 m3 : 50|14@1+ (0.001,0) [0|16.383] "Ah"  HVESP01
 SG_ HVESP01_estOcv_17_5 m4 : 8|14@1+ (0.001,0) [0|16.383] "Ah"  HVESP01
 SG_ HVESP01_estOcv_18_5 m4 : 22|14@1+ (0.001,0) [0|16.383] "Ah"  HVESP01
 SG_ HVESP01_estOcv_19_5 m4 : 36|14@1+ (0.001,0) [0|16.383] "Ah"  HVESP01
 SG_ HVESP01_estOcv_20_5 m4 : 50|14@1+ (0.001,0) [0|16.383] "Ah"  HVESP01
 SG_ HVESP01_estOcv_21_5 m5 : 8|14@1+ (0.001,0) [0|16.383] "Ah"  HVESP01
 SG_ HVESP01_estOcv_22_5 m5 : 22|14@1+ (0.001,0) [0|16.383] "Ah"  HVESP01
 SG_ HVESP01_estOcv_23_5 m5 : 36|14@1+ (0.001,0) [0|16.383] "Ah"  HVESP01
 SG_ HVESP01_estOcv_24_5 m5 : 50|14@1+ (0.001,0) [0|16.383] "Ah"  HVESP01
 SG_ HVESP01_estOcv_25_5 m6 : 8|14@1+ (0.001,0) [0|16.383] "Ah"  HVESP01
 SG_ HVESP01_estOcv_26_5 m6 : 22|14@1+ (0.001,0) [0|16.383] "Ah"  HVESP01
 SG_ HVESP01_estOcv_27_5 m6 : 36|14@1+ (0.001,0) [0|16.383] "Ah"  HVESP01
 SG_ HVESP01_estOcv_28_5 m6 : 50|14@1+ (0.001,0) [0|16.383] "Ah"  HVESP01
 SG_ HVESP01_estOcv_29_5 m7 : 8|14@1+ (0.001,0) [0|16.383] "Ah"  HVESP01
 SG_ HVESP01_estOcv_30_5 m7 : 22|14@1+ (0.001,0) [0|16.383] "Ah"  HVESP01
 SG_ HVESP01_estOcv_31_5 m7 : 36|14@1+ (0.001,0) [0|16.383] "Ah"  HVESP01
 SG_ HVESP01_estOcv_32_5 m7 : 50|14@1+ (0.001,0) [0|16.383] "Ah"  HVESP01
 SG_ HVESP01_estOcv_33_5 m8 : 8|14@1+ (0.001,0) [0|16.383] "Ah"  HVESP01
 SG_ HVESP01_estOcv_34_5 m8 : 22|14@1+ (0.001,0) [0|16.383] "Ah"  HVESP01
 SG_ HVESP01_estOcv_35_5 m8 : 36|14@1+ (0.001,0) [0|16.383] "Ah"  HVESP01
 SG_ HVESP01_estOcv_36_5 m8 : 50|14@1+ (0.001,0) [0|16.383] "Ah"  HVESP01
 SG_ HVESP01_estOcv_37_5 m9 : 8|14@1+ (0.001,0) [0|16.383] "Ah"  HVESP01
 SG_ HVESP01_estOcv_38_5 m9 : 22|14@1+ (0.001,0) [0|16.383] "Ah"  HVESP01
 SG_ HVESP01_estOcv_39_5 m9 : 36|14@1+ (0.001,0) [0|16.383] "Ah"  HVESP01
 SG_ HVESP01_estOcv_40_5 m9 : 50|14@1+ (0.001,0) [0|16.383] "Ah"  HVESP01
 SG_ HVESP01_estOcv_41_5 m10 : 8|14@1+ (0.001,0) [0|16.383] "Ah"  HVESP01
 SG_ HVESP01_estOcv_42_5 m10 : 22|14@1+ (0.001,0) [0|16.383] "Ah"  HVESP01
 SG_ HVESP01_estOcv_43_5 m10 : 36|14@1+ (0.001,0) [0|16.383] "Ah"  HVESP01
 SG_ HVESP01_estOcv_44_5 m10 : 50|14@1+ (0.001,0) [0|16.383] "Ah"  HVESP01
 SG_ HVESP01_estOcv_45_5 m11 : 8|14@1+ (0.001,0) [0|16.383] "Ah"  HVESP01
 SG_ HVESP01_estOcv_46_5 m11 : 22|14@1+ (0.001,0) [0|16.383] "Ah"  HVESP01
 SG_ HVESP01_estOcv_47_5 m11 : 36|14@1+ (0.001,0) [0|16.383] "Ah"  HVESP01
 SG_ HVESP01_estOcv_48_5 m11 : 50|14@1+ (0.001,0) [0|16.383] "Ah"  HVESP01
 SG_ HVESP01_estOcv_49_5 m12 : 8|14@1+ (0.001,0) [0|16.383] "Ah"  HVESP01
 SG_ HVESP01_estOcv_50_5 m12 : 22|14@1+ (0.001,0) [0|16.383] "Ah"  HVESP01
 SG_ HVESP01_estOcv_51_5 m12 : 36|14@1+ (0.001,0) [0|16.383] "Ah"  HVESP01
 SG_ HVESP01_estOcv_52_5 m12 : 50|14@1+ (0.001,0) [0|16.383] "Ah"  HVESP01
 SG_ HVESP01_estOcv_53_5 m13 : 8|14@1+ (0.001,0) [0|16.383] "Ah"  HVESP01
 SG_ HVESP01_estOcv_54_5 m13 : 22|14@1+ (0.001,0) [0|16.383] "Ah"  HVESP01
 SG_ HVESP01_estOcv_55_5 m13 : 36|14@1+ (0.001,0) [0|16.383] "Ah"  HVESP01
 SG_ HVESP01_estOcv_56_5 m13 : 50|14@1+ (0.001,0) [0|16.383] "Ah"  HVESP01
 SG_ HVESP01_estOcv_57_5 m14 : 8|14@1+ (0.001,0) [0|16.383] "Ah"  HVESP01
 SG_ HVESP01_estOcv_58_5 m14 : 22|14@1+ (0.001,0) [0|16.383] "Ah"  HVESP01
 SG_ HVESP01_estOcv_59_5 m14 : 36|14@1+ (0.001,0) [0|16.383] "Ah"  HVESP01
 SG_ HVESP01_estOcv_60_5 m14 : 50|14@1+ (0.001,0) [0|16.383] "Ah"  HVESP01
 SG_ HVESP01_estOcv_61_5 m15 : 8|14@1+ (0.001,0) [0|16.383] "Ah"  HVESP01
 SG_ HVESP01_estOcv_62_5 m15 : 22|14@1+ (0.001,0) [0|16.383] "Ah"  HVESP01
 SG_ HVESP01_estOcv_63_5 m15 : 36|14@1+ (0.001,0) [0|16.383] "Ah"  HVESP01
 SG_ HVESP01_estOcv_64_5 m15 : 50|14@1+ (0.001,0) [0|16.383] "Ah"  HVESP01
 SG_ HVESP01_estOcv_65_5 m16 : 8|14@1+ (0.001,0) [0|16.383] "Ah"  HVESP01
 SG_ HVESP01_estOcv_66_5 m16 : 22|14@1+ (0.001,0) [0|16.383] "Ah"  HVESP01
 SG_ HVESP01_estOcv_67_5 m16 : 36|14@1+ (0.001,0) [0|16.383] "Ah"  HVESP01
 SG_ HVESP01_estOcv_68_5 m16 : 50|14@1+ (0.001,0) [0|16.383] "Ah"  HVESP01
 SG_ HVESP01_estOcv_69_5 m17 : 8|14@1+ (0.001,0) [0|16.383] "Ah"  HVESP01
 SG_ HVESP01_estOcv_70_5 m17 : 22|14@1+ (0.001,0) [0|16.383] "Ah"  HVESP01
 SG_ HVESP01_estOcv_71_5 m17 : 36|14@1+ (0.001,0) [0|16.383] "Ah"  HVESP01
 SG_ HVESP01_estOcv_72_5 m17 : 50|14@1+ (0.001,0) [0|16.383] "Ah"  HVESP01
 SG_ HVESP01_estOcv_73_5 m18 : 8|14@1+ (0.001,0) [0|16.383] "Ah"  HVESP01
 SG_ HVESP01_estOcv_74_5 m18 : 22|14@1+ (0.001,0) [0|16.383] "Ah"  HVESP01
 SG_ HVESP01_estOcv_75_5 m18 : 36|14@1+ (0.001,0) [0|16.383] "Ah"  HVESP01
 SG_ HVESP01_estOcv_76_5 m18 : 50|14@1+ (0.001,0) [0|16.383] "Ah"  HVESP01
 SG_ HVESP01_estOcv_77_5 m19 : 8|14@1+ (0.001,0) [0|16.383] "Ah"  HVESP01
 SG_ HVESP01_estOcv_78_5 m19 : 22|14@1+ (0.001,0) [0|16.383] "Ah"  HVESP01
 SG_ HVESP01_estOcv_79_5 m19 : 36|14@1+ (0.001,0) [0|16.383] "Ah"  HVESP01
 SG_ HVESP01_estOcv_80_5 m19 : 50|14@1+ (0.001,0) [0|16.383] "Ah"  HVESP01
 SG_ HVESP01_estOcv_81_5 m20 : 8|14@1+ (0.001,0) [0|16.383] "Ah"  HVESP01
 SG_ HVESP01_estOcv_82_5 m20 : 22|14@1+ (0.001,0) [0|16.383] "Ah"  HVESP01
 SG_ HVESP01_estOcv_83_5 m20 : 36|14@1+ (0.001,0) [0|16.383] "Ah"  HVESP01
 SG_ HVESP01_estOcv_84_5 m20 : 50|14@1+ (0.001,0) [0|16.383] "Ah"  HVESP01
 SG_ HVESP01_estOcv_85_5 m21 : 8|14@1+ (0.001,0) [0|16.383] "Ah"  HVESP01
 SG_ HVESP01_estOcv_86_5 m21 : 22|14@1+ (0.001,0) [0|16.383] "Ah"  HVESP01
 SG_ HVESP01_estOcv_87_5 m21 : 36|14@1+ (0.001,0) [0|16.383] "Ah"  HVESP01
 SG_ HVESP01_estOcv_88_5 m21 : 50|14@1+ (0.001,0) [0|16.383] "Ah"  HVESP01
 SG_ HVESP01_estOcv_89_5 m22 : 8|14@1+ (0.001,0) [0|16.383] "Ah"  HVESP01
 SG_ HVESP01_estOcv_90_5 m22 : 22|14@1+ (0.001,0) [0|16.383] "Ah"  HVESP01
 SG_ HVESP01_estOcv_91_5 m22 : 36|14@1+ (0.001,0) [0|16.383] "Ah"  HVESP01
 SG_ HVESP01_estOcv_92_5 m22 : 50|14@1+ (0.001,0) [0|16.383] "Ah"  HVESP01
 SG_ HVESP01_estOcv_93_5 m23 : 8|14@1+ (0.001,0) [0|16.383] "Ah"  HVESP01
 SG_ HVESP01_estOcv_94_5 m23 : 22|14@1+ (0.001,0) [0|16.383] "Ah"  HVESP01
 SG_ HVESP01_estOcv_95_5 m23 : 36|14@1+ (0.001,0) [0|16.383] "Ah"  HVESP01
 SG_ HVESP01_estOcv_96_5 m23 : 50|14@1+ (0.001,0) [0|16.383] "Ah"  HVESP01
 SG_ HVESP01_estOcv_97_5 m24 : 8|14@1+ (0.001,0) [0|16.383] "Ah"  HVESP01
 SG_ HVESP01_estOcv_98_5 m24 : 22|14@1+ (0.001,0) [0|16.383] "Ah"  HVESP01
 SG_ HVESP01_estOcv_99_5 m24 : 36|14@1+ (0.001,0) [0|16.383] "Ah"  HVESP01
 SG_ HVESP01_estOcv_100_5 m24 : 50|14@1+ (0.001,0) [0|16.383] "Ah"  HVESP01
 SG_ HVESP01_estOcv_101_5 m25 : 8|14@1+ (0.001,0) [0|16.383] "Ah"  HVESP01
 SG_ HVESP01_estOcv_102_5 m25 : 22|14@1+ (0.001,0) [0|16.383] "Ah"  HVESP01
 SG_ HVESP01_estOcv_103_5 m25 : 36|14@1+ (0.001,0) [0|16.383] "Ah"  HVESP01
 SG_ HVESP01_estOcv_104_5 m25 : 50|14@1+ (0.001,0) [0|16.383] "Ah"  HVESP01
 SG_ HVESP01_estOcv_105_5 m26 : 8|14@1+ (0.001,0) [0|16.383] "Ah"  HVESP01
 SG_ HVESP01_estOcv_106_5 m26 : 22|14@1+ (0.001,0) [0|16.383] "Ah"  HVESP01
 SG_ HVESP01_estOcv_107_5 m26 : 36|14@1+ (0.001,0) [0|16.383] "Ah"  HVESP01
 SG_ HVESP01_estOcv_108_5 m26 : 50|14@1+ (0.001,0) [0|16.383] "Ah"  HVESP01
 SG_ HVESP01_estOcv_109_5 m27 : 8|14@1+ (0.001,0) [0|16.383] "Ah"  HVESP01
 SG_ HVESP01_estOcv_110_5 m27 : 22|14@1+ (0.001,0) [0|16.383] "Ah"  HVESP01
 SG_ HVESP01_estOcv_111_5 m27 : 36|14@1+ (0.001,0) [0|16.383] "Ah"  HVESP01
 SG_ HVESP01_estOcv_112_5 m27 : 50|14@1+ (0.001,0) [0|16.383] "Ah"  HVESP01
 SG_ HVESP01_estOcv_113_5 m28 : 8|14@1+ (0.001,0) [0|16.383] "Ah"  HVESP01
 SG_ HVESP01_estOcv_114_5 m28 : 22|14@1+ (0.001,0) [0|16.383] "Ah"  HVESP01
 SG_ HVESP01_estOcv_115_5 m28 : 36|14@1+ (0.001,0) [0|16.383] "Ah"  HVESP01
 SG_ HVESP01_estOcv_116_5 m28 : 50|14@1+ (0.001,0) [0|16.383] "Ah"  HVESP01
 SG_ HVESP01_estOcv_117_5 m29 : 8|14@1+ (0.001,0) [0|16.383] "Ah"  HVESP01
 SG_ HVESP01_estOcv_118_5 m29 : 22|14@1+ (0.001,0) [0|16.383] "Ah"  HVESP01
 SG_ HVESP01_estOcv_119_5 m29 : 36|14@1+ (0.001,0) [0|16.383] "Ah"  HVESP01
 SG_ HVESP01_estOcv_120_5 m29 : 50|14@1+ (0.001,0) [0|16.383] "Ah"  HVESP01
 SG_ HVESP01_estOcv_121_5 m30 : 8|14@1+ (0.001,0) [0|16.383] "Ah"  HVESP01
 SG_ HVESP01_estOcv_122_5 m30 : 22|14@1+ (0.001,0) [0|16.383] "Ah"  HVESP01
 SG_ HVESP01_estOcv_123_5 m30 : 36|14@1+ (0.001,0) [0|16.383] "Ah"  HVESP01
 SG_ HVESP01_estOcv_124_5 m30 : 50|14@1+ (0.001,0) [0|16.383] "Ah"  HVESP01
 SG_ HVESP01_estOcv_125_5 m31 : 8|14@1+ (0.001,0) [0|16.383] "Ah"  HVESP01
 SG_ HVESP01_estOcv_126_5 m31 : 22|14@1+ (0.001,0) [0|16.383] "Ah"  HVESP01
 SG_ HVESP01_estOcv_127_5 m31 : 36|14@1+ (0.001,0) [0|16.383] "Ah"  HVESP01
 SG_ HVESP01_estOcv_128_5 m31 : 50|14@1+ (0.001,0) [0|16.383] "Ah"  HVESP01
 SG_ HVESP01_estOcv_129_5 m32 : 8|14@1+ (0.001,0) [0|16.383] "Ah"  HVESP01
 SG_ HVESP01_estOcv_130_5 m32 : 22|14@1+ (0.001,0) [0|16.383] "Ah"  HVESP01
 SG_ HVESP01_estOcv_131_5 m32 : 36|14@1+ (0.001,0) [0|16.383] "Ah"  HVESP01
 SG_ HVESP01_estOcv_132_5 m32 : 50|14@1+ (0.001,0) [0|16.383] "Ah"  HVESP01
 SG_ HVESP01_estOcv_133_5 m33 : 8|14@1+ (0.001,0) [0|16.383] "Ah"  HVESP01
 SG_ HVESP01_estOcv_134_5 m33 : 22|14@1+ (0.001,0) [0|16.383] "Ah"  HVESP01
 SG_ HVESP01_estOcv_135_5 m33 : 36|14@1+ (0.001,0) [0|16.383] "Ah"  HVESP01
 SG_ HVESP01_estOcv_136_5 m33 : 50|14@1+ (0.001,0) [0|16.383] "Ah"  HVESP01
 SG_ HVESP01_estOcv_137_5 m34 : 8|14@1+ (0.001,0) [0|16.383] "Ah"  HVESP01
 SG_ HVESP01_estOcv_138_5 m34 : 22|14@1+ (0.001,0) [0|16.383] "Ah"  HVESP01
 SG_ HVESP01_estOcv_139_5 m34 : 36|14@1+ (0.001,0) [0|16.383] "Ah"  HVESP01
 SG_ HVESP01_estOcv_140_5 m34 : 50|14@1+ (0.001,0) [0|16.383] "Ah"  HVESP01
 SG_ HVESP01_estOcv_141_5 m35 : 8|14@1+ (0.001,0) [0|16.383] "Ah"  HVESP01
 SG_ HVESP01_estOcv_142_5 m35 : 22|14@1+ (0.001,0) [0|16.383] "Ah"  HVESP01
 SG_ HVESP01_estOcv_143_5 m35 : 36|14@1+ (0.001,0) [0|16.383] "Ah"  HVESP01
 SG_ HVESP01_estOcv_144_5 m35 : 50|14@1+ (0.001,0) [0|16.383] "Ah"  HVESP01
 SG_ HVESP01_estOcv_145_5 m36 : 8|14@1+ (0.001,0) [0|16.383] "Ah"  HVESP01
 SG_ HVESP01_estOcv_146_5 m36 : 22|14@1+ (0.001,0) [0|16.383] "Ah"  HVESP01
 SG_ HVESP01_estOcv_147_5 m36 : 36|14@1+ (0.001,0) [0|16.383] "Ah"  HVESP01
 SG_ HVESP01_estOcv_148_5 m36 : 50|14@1+ (0.001,0) [0|16.383] "Ah"  HVESP01
 SG_ HVESP01_estOcv_149_5 m37 : 8|14@1+ (0.001,0) [0|16.383] "Ah"  HVESP01
 SG_ HVESP01_estOcv_150_5 m37 : 22|14@1+ (0.001,0) [0|16.383] "Ah"  HVESP01
 SG_ HVESP01_estOcv_151_5 m37 : 36|14@1+ (0.001,0) [0|16.383] "Ah"  HVESP01
 SG_ HVESP01_estOcv_152_5 m37 : 50|14@1+ (0.001,0) [0|16.383] "Ah"  HVESP01
 SG_ HVESP01_estOcv_153_5 m38 : 8|14@1+ (0.001,0) [0|16.383] "Ah"  HVESP01
 SG_ HVESP01_estOcv_154_5 m38 : 22|14@1+ (0.001,0) [0|16.383] "Ah"  HVESP01
 SG_ HVESP01_estOcv_155_5 m38 : 36|14@1+ (0.001,0) [0|16.383] "Ah"  HVESP01
 SG_ HVESP01_estOcv_156_5 m38 : 50|14@1+ (0.001,0) [0|16.383] "Ah"  HVESP01
 SG_ HVESP01_estOcv_157_5 m39 : 8|14@1+ (0.001,0) [0|16.383] "Ah"  HVESP01
 SG_ HVESP01_estOcv_158_5 m39 : 22|14@1+ (0.001,0) [0|16.383] "Ah"  HVESP01
 SG_ HVESP01_estOcv_159_5 m39 : 36|14@1+ (0.001,0) [0|16.383] "Ah"  HVESP01
 SG_ HVESP01_estOcv_160_5 m39 : 50|14@1+ (0.001,0) [0|16.383] "Ah"  HVESP01
 SG_ HVESP01_estOcv_161_5 m40 : 8|14@1+ (0.001,0) [0|16.383] "Ah"  HVESP01
 SG_ HVESP01_estOcv_162_5 m40 : 22|14@1+ (0.001,0) [0|16.383] "Ah"  HVESP01
 SG_ HVESP01_estOcv_163_5 m40 : 36|14@1+ (0.001,0) [0|16.383] "Ah"  HVESP01
 SG_ HVESP01_estOcv_164_5 m40 : 50|14@1+ (0.001,0) [0|16.383] "Ah"  HVESP01
 SG_ HVESP01_estOcv_165_5 m41 : 8|14@1+ (0.001,0) [0|16.383] "Ah"  HVESP01
 SG_ HVESP01_estOcv_166_5 m41 : 22|14@1+ (0.001,0) [0|16.383] "Ah"  HVESP01
 SG_ HVESP01_estOcv_167_5 m41 : 36|14@1+ (0.001,0) [0|16.383] "Ah"  HVESP01
 SG_ HVESP01_estOcv_168_5 m41 : 50|14@1+ (0.001,0) [0|16.383] "Ah"  HVESP01
 SG_ HVESP01_estOcv_169_5 m42 : 8|14@1+ (0.001,0) [0|16.383] "Ah"  HVESP01
 SG_ HVESP01_estOcv_170_5 m42 : 22|14@1+ (0.001,0) [0|16.383] "Ah"  HVESP01
 SG_ HVESP01_estOcv_171_5 m42 : 36|14@1+ (0.001,0) [0|16.383] "Ah"  HVESP01
 SG_ HVESP01_estOcv_172_5 m42 : 50|14@1+ (0.001,0) [0|16.383] "Ah"  HVESP01
 SG_ HVESP01_estOcv_173_5 m43 : 8|14@1+ (0.001,0) [0|16.383] "Ah"  HVESP01
 SG_ HVESP01_estOcv_174_5 m43 : 22|14@1+ (0.001,0) [0|16.383] "Ah"  HVESP01
 SG_ HVESP01_estOcv_175_5 m43 : 36|14@1+ (0.001,0) [0|16.383] "Ah"  HVESP01
 SG_ HVESP01_estOcv_176_5 m43 : 50|14@1+ (0.001,0) [0|16.383] "Ah"  HVESP01
 SG_ HVESP01_estOcv_177_5 m44 : 8|14@1+ (0.001,0) [0|16.383] "Ah"  HVESP01
 SG_ HVESP01_estOcv_178_5 m44 : 22|14@1+ (0.001,0) [0|16.383] "Ah"  HVESP01
 SG_ HVESP01_estOcv_179_5 m44 : 36|14@1+ (0.001,0) [0|16.383] "Ah"  HVESP01
 SG_ HVESP01_estOcv_180_5 m44 : 50|14@1+ (0.001,0) [0|16.383] "Ah"  HVESP01
 SG_ multiplexoreo_5 M : 0|8@1+ (1,0) [0|255] ""  HVESP01

BA_DEF_ BO_  "GenMsgDiag" ENUM  "No","Yes";
BA_DEF_ BO_  "GenMsgInstanced" STRING ;
BA_DEF_ SG_  "SigType" ENUM  "Default","Range","RangeSigned","ASCII","Discrete","Control","ReferencePGN","DTC","StringDelimiter","StringLength","StringLengthControl","MessageCounter","MessageChecksum";
BA_DEF_ SG_  "GenSigEVName" STRING ;
BA_DEF_ SG_  "GenSigILSupport" ENUM  "No","Yes";
BA_DEF_ SG_  "GenSigSendType" ENUM  "Cyclic","OnWrite","OnWriteWithRepetition","OnChange","OnChangeWithRepetition","IfActive","IfActiveWithRepetition","NoSigSendType";
BA_DEF_ SG_  "GenSigStartValue" INT 0 10000;
BA_DEF_ BO_  "GenMsgILSupport" ENUM  "No","Yes";
BA_DEF_ BO_  "GenMsgSendType" ENUM  "cyclic","NotUsed","IfActive","NotUsed","NotUsed","NotUsed","NotUsed","NotUsed","noMsgSendType";
BA_DEF_ BO_  "GenMsgRequestable" INT 0 1;
BA_DEF_ BO_  "GenMsgCycleTime" INT 0 3600000;
BA_DEF_ BO_  "VFrameFormat" ENUM  "StandardCAN","ExtendedCAN","reserved","J1939PG";
BA_DEF_ SG_  "SystemSignalLongSymbol" STRING ;
BA_DEF_ BO_  "SystemMessageLongSymbol" STRING ;
BA_DEF_DEF_  "GenMsgDiag" "No";
BA_DEF_DEF_  "GenMsgInstanced" "No";
BA_DEF_DEF_  "SigType" "Default";
BA_DEF_DEF_  "GenSigEVName" "Env@Nodename_@Signame";
BA_DEF_DEF_  "GenSigILSupport" "Yes";
BA_DEF_DEF_  "GenSigSendType" "NoSigSendType";
BA_DEF_DEF_  "GenSigStartValue" 0;
BA_DEF_DEF_  "GenMsgILSupport" "Yes";
BA_DEF_DEF_  "GenMsgSendType" "noMsgSendType";
BA_DEF_DEF_  "GenMsgRequestable" 1;
BA_DEF_DEF_  "GenMsgCycleTime" 0;
BA_DEF_DEF_  "VFrameFormat" "J1939PG";
BA_DEF_DEF_  "SystemSignalLongSymbol" "";
BA_DEF_DEF_  "SystemMessageLongSymbol" "";
BA_ "GenMsgCycleTime" BO_ 2499744364 200;
BA_ "GenMsgSendType" BO_ 2499744364 0;
BA_ "GenMsgInstanced" BO_ 2499744364 "False";
BA_ "GenMsgCycleTime" BO_ 2499744613 200;
BA_ "GenMsgSendType" BO_ 2499744613 0;
BA_ "GenMsgInstanced" BO_ 2499744613 "False";
BA_ "GenMsgCycleTime" BO_ 2499744614 200;
BA_ "GenMsgSendType" BO_ 2499744614 0;
BA_ "GenMsgInstanced" BO_ 2499744614 "False";
BA_ "GenMsgCycleTime" BO_ 2499744615 200;
BA_ "GenMsgSendType" BO_ 2499744615 0;
BA_ "GenMsgInstanced" BO_ 2499744615 "False";
BA_ "GenMsgCycleTime" BO_ 2499744616 200;
BA_ "GenMsgSendType" BO_ 2499744616 0;
BA_ "GenMsgInstanced" BO_ 2499744616 "False";
BA_ "GenMsgCycleTime" BO_ 2499744617 200;
BA_ "GenMsgSendType" BO_ 2499744617 0;
BA_ "GenMsgInstanced" BO_ 2499744617 "False";
BA_ "GenMsgCycleTime" BO_ 2499744618 200;
BA_ "GenMsgSendType" BO_ 2499744618 0;
BA_ "GenMsgInstanced" BO_ 2499744618 "False";
BA_ "GenMsgCycleTime" BO_ 2499744619 200;
BA_ "GenMsgSendType" BO_ 2499744619 0;
BA_ "GenMsgInstanced" BO_ 2499744619 "False";
BA_ "GenMsgCycleTime" BO_ 2499744620 200;
BA_ "GenMsgSendType" BO_ 2499744620 0;
BA_ "GenMsgInstanced" BO_ 2499744620 "False";
BA_ "VFrameFormat" BO_ 2499744869 1;
BA_ "GenMsgCycleTime" BO_ 2499744869 100;
BA_ "GenMsgInstanced" BO_ 2499744869 "False";
BA_ "VFrameFormat" BO_ 2499744870 1;
BA_ "GenMsgCycleTime" BO_ 2499744870 100;
BA_ "GenMsgInstanced" BO_ 2499744870 "False";
BA_ "VFrameFormat" BO_ 2499744871 1;
BA_ "GenMsgCycleTime" BO_ 2499744871 100;
BA_ "GenMsgInstanced" BO_ 2499744871 "False";
BA_ "VFrameFormat" BO_ 2499744872 1;
BA_ "GenMsgCycleTime" BO_ 2499744872 100;
BA_ "GenMsgInstanced" BO_ 2499744872 "False";
BA_ "VFrameFormat" BO_ 2499744873 1;
BA_ "GenMsgCycleTime" BO_ 2499744873 100;
BA_ "GenMsgInstanced" BO_ 2499744873 "False";
BA_ "VFrameFormat" BO_ 2499744874 1;
BA_ "GenMsgCycleTime" BO_ 2499744874 100;
BA_ "GenMsgInstanced" BO_ 2499744874 "False";
BA_ "VFrameFormat" BO_ 2499744875 1;
BA_ "GenMsgCycleTime" BO_ 2499744875 100;
BA_ "GenMsgInstanced" BO_ 2499744875 "False";
BA_ "VFrameFormat" BO_ 2499744876 1;
BA_ "GenMsgCycleTime" BO_ 2499744876 100;
BA_ "GenMsgInstanced" BO_ 2499744876 "False";
BA_ "GenMsgCycleTime" BO_ 2499745125 200;
BA_ "GenMsgSendType" BO_ 2499745125 0;
BA_ "GenMsgInstanced" BO_ 2499745125 "False";
BA_ "GenMsgCycleTime" BO_ 2499745126 200;
BA_ "GenMsgSendType" BO_ 2499745126 0;
BA_ "GenMsgInstanced" BO_ 2499745126 "False";
BA_ "GenMsgCycleTime" BO_ 2499745127 200;
BA_ "GenMsgSendType" BO_ 2499745127 0;
BA_ "GenMsgInstanced" BO_ 2499745127 "False";
BA_ "GenMsgCycleTime" BO_ 2499745128 200;
BA_ "GenMsgSendType" BO_ 2499745128 0;
BA_ "GenMsgInstanced" BO_ 2499745128 "False";
BA_ "GenMsgCycleTime" BO_ 2499745129 200;
BA_ "GenMsgSendType" BO_ 2499745129 0;
BA_ "GenMsgInstanced" BO_ 2499745129 "False";
BA_ "GenMsgCycleTime" BO_ 2499745130 200;
BA_ "GenMsgSendType" BO_ 2499745130 0;
BA_ "GenMsgInstanced" BO_ 2499745130 "False";
BA_ "GenMsgCycleTime" BO_ 2499745131 200;
BA_ "GenMsgSendType" BO_ 2499745131 0;
BA_ "GenMsgInstanced" BO_ 2499745131 "False";
BA_ "GenMsgCycleTime" BO_ 2499745132 200;
BA_ "GenMsgSendType" BO_ 2499745132 0;
BA_ "GenMsgInstanced" BO_ 2499745132 "False";
BA_ "GenMsgCycleTime" BO_ 2499745381 200;
BA_ "GenMsgSendType" BO_ 2499745381 0;
BA_ "GenMsgInstanced" BO_ 2499745381 "False";
BA_ "GenMsgCycleTime" BO_ 2499745382 200;
BA_ "GenMsgSendType" BO_ 2499745382 0;
BA_ "GenMsgInstanced" BO_ 2499745382 "False";
BA_ "GenMsgCycleTime" BO_ 2499745383 200;
BA_ "GenMsgSendType" BO_ 2499745383 0;
BA_ "GenMsgInstanced" BO_ 2499745383 "False";
BA_ "GenMsgCycleTime" BO_ 2499745384 200;
BA_ "GenMsgSendType" BO_ 2499745384 0;
BA_ "GenMsgInstanced" BO_ 2499745384 "False";
BA_ "GenMsgCycleTime" BO_ 2499745385 200;
BA_ "GenMsgSendType" BO_ 2499745385 0;
BA_ "GenMsgInstanced" BO_ 2499745385 "False";
BA_ "GenMsgCycleTime" BO_ 2499745386 200;
BA_ "GenMsgSendType" BO_ 2499745386 0;
BA_ "GenMsgInstanced" BO_ 2499745386 "False";
BA_ "GenMsgCycleTime" BO_ 2499745387 200;
BA_ "GenMsgSendType" BO_ 2499745387 0;
BA_ "GenMsgInstanced" BO_ 2499745387 "False";
BA_ "GenMsgCycleTime" BO_ 2499745388 200;
BA_ "GenMsgSendType" BO_ 2499745388 0;
BA_ "GenMsgInstanced" BO_ 2499745388 "False";
BA_ "GenMsgCycleTime" BO_ 2499745637 200;
BA_ "GenMsgSendType" BO_ 2499745637 0;
BA_ "GenMsgInstanced" BO_ 2499745637 "False";
BA_ "GenMsgCycleTime" BO_ 2499745638 200;
BA_ "GenMsgSendType" BO_ 2499745638 0;
BA_ "GenMsgInstanced" BO_ 2499745638 "False";
BA_ "GenMsgCycleTime" BO_ 2499745639 200;
BA_ "GenMsgSendType" BO_ 2499745639 0;
BA_ "GenMsgInstanced" BO_ 2499745639 "False";
BA_ "GenMsgCycleTime" BO_ 2499745640 200;
BA_ "GenMsgSendType" BO_ 2499745640 0;
BA_ "GenMsgInstanced" BO_ 2499745640 "False";
BA_ "GenMsgCycleTime" BO_ 2499745641 200;
BA_ "GenMsgSendType" BO_ 2499745641 0;
BA_ "GenMsgInstanced" BO_ 2499745641 "False";
BA_ "GenMsgCycleTime" BO_ 2499745642 200;
BA_ "GenMsgSendType" BO_ 2499745642 0;
BA_ "GenMsgInstanced" BO_ 2499745642 "False";
BA_ "GenMsgCycleTime" BO_ 2499745643 200;
BA_ "GenMsgSendType" BO_ 2499745643 0;
BA_ "GenMsgInstanced" BO_ 2499745643 "False";
BA_ "GenMsgCycleTime" BO_ 2499745644 200;
BA_ "GenMsgSendType" BO_ 2499745644 0;
BA_ "GenMsgInstanced" BO_ 2499745644 "False";
BA_ "GenMsgCycleTime" BO_ 2499745893 200;
BA_ "GenMsgSendType" BO_ 2499745893 0;
BA_ "GenMsgInstanced" BO_ 2499745893 "False";
BA_ "GenMsgCycleTime" BO_ 2499745894 200;
BA_ "GenMsgSendType" BO_ 2499745894 0;
BA_ "GenMsgInstanced" BO_ 2499745894 "False";
BA_ "GenMsgCycleTime" BO_ 2499745895 200;
BA_ "GenMsgSendType" BO_ 2499745895 0;
BA_ "GenMsgInstanced" BO_ 2499745895 "False";
BA_ "GenMsgCycleTime" BO_ 2499745896 200;
BA_ "GenMsgSendType" BO_ 2499745896 0;
BA_ "GenMsgInstanced" BO_ 2499745896 "False";
BA_ "GenMsgCycleTime" BO_ 2499745897 200;
BA_ "GenMsgSendType" BO_ 2499745897 0;
BA_ "GenMsgInstanced" BO_ 2499745897 "False";
BA_ "GenMsgCycleTime" BO_ 2499745898 200;
BA_ "GenMsgSendType" BO_ 2499745898 0;
BA_ "GenMsgInstanced" BO_ 2499745898 "False";
BA_ "GenMsgCycleTime" BO_ 2499745899 200;
BA_ "GenMsgSendType" BO_ 2499745899 0;
BA_ "GenMsgInstanced" BO_ 2499745899 "False";
BA_ "GenMsgCycleTime" BO_ 2499745900 200;
BA_ "GenMsgSendType" BO_ 2499745900 0;
BA_ "GenMsgInstanced" BO_ 2499745900 "False";
BA_ "GenMsgCycleTime" BO_ 2499746149 200;
BA_ "GenMsgSendType" BO_ 2499746149 0;
BA_ "GenMsgInstanced" BO_ 2499746149 "False";
BA_ "GenMsgCycleTime" BO_ 2499746150 200;
BA_ "GenMsgSendType" BO_ 2499746150 0;
BA_ "GenMsgInstanced" BO_ 2499746150 "False";
BA_ "GenMsgCycleTime" BO_ 2499746151 200;
BA_ "GenMsgSendType" BO_ 2499746151 0;
BA_ "GenMsgInstanced" BO_ 2499746151 "False";
BA_ "GenMsgCycleTime" BO_ 2499746152 200;
BA_ "GenMsgSendType" BO_ 2499746152 0;
BA_ "GenMsgInstanced" BO_ 2499746152 "False";
BA_ "GenMsgCycleTime" BO_ 2499746153 200;
BA_ "GenMsgSendType" BO_ 2499746153 0;
BA_ "GenMsgInstanced" BO_ 2499746153 "False";
BA_ "GenMsgCycleTime" BO_ 2499746154 200;
BA_ "GenMsgSendType" BO_ 2499746154 0;
BA_ "GenMsgInstanced" BO_ 2499746154 "False";
BA_ "GenMsgCycleTime" BO_ 2499746155 200;
BA_ "GenMsgSendType" BO_ 2499746155 0;
BA_ "GenMsgInstanced" BO_ 2499746155 "False";
BA_ "GenMsgCycleTime" BO_ 2499746156 200;
BA_ "GenMsgSendType" BO_ 2499746156 0;
BA_ "GenMsgInstanced" BO_ 2499746156 "False";
BA_ "VFrameFormat" BO_ 2499747941 1;
BA_ "GenMsgCycleTime" BO_ 2499747941 100;
BA_ "GenMsgInstanced" BO_ 2499747941 "False";
BA_ "VFrameFormat" BO_ 2499747942 1;
BA_ "GenMsgCycleTime" BO_ 2499747942 100;
BA_ "GenMsgInstanced" BO_ 2499747942 "False";
BA_ "VFrameFormat" BO_ 2499747943 1;
BA_ "GenMsgCycleTime" BO_ 2499747943 100;
BA_ "GenMsgInstanced" BO_ 2499747943 "False";
BA_ "VFrameFormat" BO_ 2499747944 1;
BA_ "GenMsgCycleTime" BO_ 2499747944 100;
BA_ "GenMsgInstanced" BO_ 2499747944 "False";
BA_ "VFrameFormat" BO_ 2499747945 1;
BA_ "GenMsgCycleTime" BO_ 2499747945 100;
BA_ "GenMsgInstanced" BO_ 2499747945 "False";
BA_ "VFrameFormat" BO_ 2499747946 1;
BA_ "GenMsgCycleTime" BO_ 2499747946 100;
BA_ "GenMsgInstanced" BO_ 2499747946 "False";
BA_ "VFrameFormat" BO_ 2499747947 1;
BA_ "GenMsgCycleTime" BO_ 2499747947 100;
BA_ "GenMsgInstanced" BO_ 2499747947 "False";
BA_ "VFrameFormat" BO_ 2499747948 1;
BA_ "GenMsgCycleTime" BO_ 2499747948 100;
BA_ "GenMsgInstanced" BO_ 2499747948 "False";
BA_ "VFrameFormat" BO_ 2499748197 1;
BA_ "GenMsgCycleTime" BO_ 2499748197 1000;
BA_ "GenMsgInstanced" BO_ 2499748197 "False";
BA_ "GenMsgDiag" BO_ 2499748197 1;
BA_ "VFrameFormat" BO_ 2499748198 1;
BA_ "GenMsgCycleTime" BO_ 2499748198 1000;
BA_ "GenMsgInstanced" BO_ 2499748198 "False";
BA_ "GenMsgDiag" BO_ 2499748198 1;
BA_ "VFrameFormat" BO_ 2499748199 1;
BA_ "GenMsgCycleTime" BO_ 2499748199 1000;
BA_ "GenMsgInstanced" BO_ 2499748199 "False";
BA_ "GenMsgDiag" BO_ 2499748199 1;
BA_ "VFrameFormat" BO_ 2499748200 1;
BA_ "GenMsgCycleTime" BO_ 2499748200 1000;
BA_ "GenMsgInstanced" BO_ 2499748200 "False";
BA_ "GenMsgDiag" BO_ 2499748200 1;
BA_ "VFrameFormat" BO_ 2499748201 1;
BA_ "GenMsgCycleTime" BO_ 2499748201 1000;
BA_ "GenMsgInstanced" BO_ 2499748201 "False";
BA_ "GenMsgDiag" BO_ 2499748201 1;
BA_ "VFrameFormat" BO_ 2499748202 1;
BA_ "GenMsgCycleTime" BO_ 2499748202 1000;
BA_ "GenMsgInstanced" BO_ 2499748202 "False";
BA_ "GenMsgDiag" BO_ 2499748202 1;
BA_ "VFrameFormat" BO_ 2499748203 1;
BA_ "GenMsgCycleTime" BO_ 2499748203 1000;
BA_ "GenMsgInstanced" BO_ 2499748203 "False";
BA_ "GenMsgDiag" BO_ 2499748203 1;
BA_ "VFrameFormat" BO_ 2499748204 1;
BA_ "GenMsgCycleTime" BO_ 2499748204 1000;
BA_ "GenMsgInstanced" BO_ 2499748204 "False";
BA_ "GenMsgDiag" BO_ 2499748204 1;
BA_ "VFrameFormat" BO_ 2499748453 1;
BA_ "GenMsgCycleTime" BO_ 2499748453 1000;
BA_ "GenMsgInstanced" BO_ 2499748453 "False";
BA_ "GenMsgDiag" BO_ 2499748453 1;
BA_ "VFrameFormat" BO_ 2499748454 1;
BA_ "GenMsgCycleTime" BO_ 2499748454 1000;
BA_ "GenMsgInstanced" BO_ 2499748454 "False";
BA_ "GenMsgDiag" BO_ 2499748454 1;
BA_ "VFrameFormat" BO_ 2499748455 1;
BA_ "GenMsgCycleTime" BO_ 2499748455 1000;
BA_ "GenMsgInstanced" BO_ 2499748455 "False";
BA_ "GenMsgDiag" BO_ 2499748455 1;
BA_ "VFrameFormat" BO_ 2499748456 1;
BA_ "GenMsgCycleTime" BO_ 2499748456 1000;
BA_ "GenMsgInstanced" BO_ 2499748456 "False";
BA_ "GenMsgDiag" BO_ 2499748456 1;
BA_ "VFrameFormat" BO_ 2499748457 1;
BA_ "GenMsgCycleTime" BO_ 2499748457 1000;
BA_ "GenMsgInstanced" BO_ 2499748457 "False";
BA_ "GenMsgDiag" BO_ 2499748457 1;
BA_ "VFrameFormat" BO_ 2499748458 1;
BA_ "GenMsgCycleTime" BO_ 2499748458 1000;
BA_ "GenMsgInstanced" BO_ 2499748458 "False";
BA_ "GenMsgDiag" BO_ 2499748458 1;
BA_ "VFrameFormat" BO_ 2499748459 1;
BA_ "GenMsgCycleTime" BO_ 2499748459 1000;
BA_ "GenMsgInstanced" BO_ 2499748459 "False";
BA_ "GenMsgDiag" BO_ 2499748459 1;
BA_ "VFrameFormat" BO_ 2499748460 1;
BA_ "GenMsgCycleTime" BO_ 2499748460 1000;
BA_ "GenMsgInstanced" BO_ 2499748460 "False";
BA_ "GenMsgDiag" BO_ 2499748460 1;
BA_ "VFrameFormat" BO_ 2499748709 1;
BA_ "GenMsgCycleTime" BO_ 2499748709 1000;
BA_ "GenMsgInstanced" BO_ 2499748709 "False";
BA_ "GenMsgDiag" BO_ 2499748709 1;
BA_ "VFrameFormat" BO_ 2499748710 1;
BA_ "GenMsgCycleTime" BO_ 2499748710 1000;
BA_ "GenMsgInstanced" BO_ 2499748710 "False";
BA_ "GenMsgDiag" BO_ 2499748710 1;
BA_ "VFrameFormat" BO_ 2499748711 1;
BA_ "GenMsgCycleTime" BO_ 2499748711 1000;
BA_ "GenMsgInstanced" BO_ 2499748711 "False";
BA_ "GenMsgDiag" BO_ 2499748711 1;
BA_ "VFrameFormat" BO_ 2499748712 1;
BA_ "GenMsgCycleTime" BO_ 2499748712 1000;
BA_ "GenMsgInstanced" BO_ 2499748712 "False";
BA_ "GenMsgDiag" BO_ 2499748712 1;
BA_ "VFrameFormat" BO_ 2499748713 1;
BA_ "GenMsgCycleTime" BO_ 2499748713 1000;
BA_ "GenMsgInstanced" BO_ 2499748713 "False";
BA_ "GenMsgDiag" BO_ 2499748713 1;
BA_ "VFrameFormat" BO_ 2499748714 1;
BA_ "GenMsgCycleTime" BO_ 2499748714 1000;
BA_ "GenMsgInstanced" BO_ 2499748714 "False";
BA_ "GenMsgDiag" BO_ 2499748714 1;
BA_ "VFrameFormat" BO_ 2499748715 1;
BA_ "GenMsgCycleTime" BO_ 2499748715 1000;
BA_ "GenMsgInstanced" BO_ 2499748715 "False";
BA_ "GenMsgDiag" BO_ 2499748715 1;
BA_ "VFrameFormat" BO_ 2499748716 1;
BA_ "GenMsgCycleTime" BO_ 2499748716 1000;
BA_ "GenMsgInstanced" BO_ 2499748716 "False";
BA_ "GenMsgDiag" BO_ 2499748716 1;
BA_ "GenMsgCycleTime" BO_ 2499748965 100;
BA_ "GenMsgSendType" BO_ 2499748965 0;
BA_ "GenMsgInstanced" BO_ 2499748965 "False";
BA_ "GenMsgDiag" BO_ 2499748965 1;
BA_ "GenMsgCycleTime" BO_ 2499748966 100;
BA_ "GenMsgSendType" BO_ 2499748966 0;
BA_ "GenMsgInstanced" BO_ 2499748966 "False";
BA_ "GenMsgDiag" BO_ 2499748966 1;
BA_ "GenMsgCycleTime" BO_ 2499748967 100;
BA_ "GenMsgSendType" BO_ 2499748967 0;
BA_ "GenMsgInstanced" BO_ 2499748967 "False";
BA_ "GenMsgDiag" BO_ 2499748967 1;
BA_ "GenMsgCycleTime" BO_ 2499748968 100;
BA_ "GenMsgSendType" BO_ 2499748968 0;
BA_ "GenMsgInstanced" BO_ 2499748968 "False";
BA_ "GenMsgDiag" BO_ 2499748968 1;
BA_ "GenMsgCycleTime" BO_ 2499748969 100;
BA_ "GenMsgSendType" BO_ 2499748969 0;
BA_ "GenMsgInstanced" BO_ 2499748969 "False";
BA_ "GenMsgDiag" BO_ 2499748969 1;
BA_ "GenMsgCycleTime" BO_ 2499748970 100;
BA_ "GenMsgSendType" BO_ 2499748970 0;
BA_ "GenMsgInstanced" BO_ 2499748970 "False";
BA_ "GenMsgDiag" BO_ 2499748970 1;
BA_ "GenMsgCycleTime" BO_ 2499748971 100;
BA_ "GenMsgSendType" BO_ 2499748971 0;
BA_ "GenMsgInstanced" BO_ 2499748971 "False";
BA_ "GenMsgDiag" BO_ 2499748971 1;
BA_ "GenMsgCycleTime" BO_ 2499748972 100;
BA_ "GenMsgSendType" BO_ 2499748972 0;
BA_ "GenMsgInstanced" BO_ 2499748972 "False";
BA_ "GenMsgDiag" BO_ 2499748972 1;
BA_ "GenMsgCycleTime" BO_ 2499749221 100;
BA_ "GenMsgSendType" BO_ 2499749221 0;
BA_ "GenMsgInstanced" BO_ 2499749221 "False";
BA_ "GenMsgDiag" BO_ 2499749221 1;
BA_ "GenMsgCycleTime" BO_ 2499749222 100;
BA_ "GenMsgSendType" BO_ 2499749222 0;
BA_ "GenMsgInstanced" BO_ 2499749222 "False";
BA_ "GenMsgDiag" BO_ 2499749222 1;
BA_ "GenMsgCycleTime" BO_ 2499749223 100;
BA_ "GenMsgSendType" BO_ 2499749223 0;
BA_ "GenMsgInstanced" BO_ 2499749223 "False";
BA_ "GenMsgDiag" BO_ 2499749223 1;
BA_ "GenMsgCycleTime" BO_ 2499749224 100;
BA_ "GenMsgSendType" BO_ 2499749224 0;
BA_ "GenMsgInstanced" BO_ 2499749224 "False";
BA_ "GenMsgDiag" BO_ 2499749224 1;
BA_ "GenMsgCycleTime" BO_ 2499749225 100;
BA_ "GenMsgSendType" BO_ 2499749225 0;
BA_ "GenMsgInstanced" BO_ 2499749225 "False";
BA_ "GenMsgDiag" BO_ 2499749225 1;
BA_ "GenMsgCycleTime" BO_ 2499749226 100;
BA_ "GenMsgSendType" BO_ 2499749226 0;
BA_ "GenMsgInstanced" BO_ 2499749226 "False";
BA_ "GenMsgDiag" BO_ 2499749226 1;
BA_ "GenMsgCycleTime" BO_ 2499749227 100;
BA_ "GenMsgSendType" BO_ 2499749227 0;
BA_ "GenMsgInstanced" BO_ 2499749227 "False";
BA_ "GenMsgDiag" BO_ 2499749227 1;
BA_ "GenMsgCycleTime" BO_ 2499749228 100;
BA_ "GenMsgSendType" BO_ 2499749228 0;
BA_ "GenMsgInstanced" BO_ 2499749228 "False";
BA_ "GenMsgDiag" BO_ 2499749228 1;
BA_ "VFrameFormat" BO_ 2499749477 1;
BA_ "GenMsgInstanced" BO_ 2499749477 "False";
BA_ "VFrameFormat" BO_ 2499749478 1;
BA_ "GenMsgInstanced" BO_ 2499749478 "False";
BA_ "VFrameFormat" BO_ 2499749479 1;
BA_ "GenMsgInstanced" BO_ 2499749479 "False";
BA_ "VFrameFormat" BO_ 2499749480 1;
BA_ "GenMsgInstanced" BO_ 2499749480 "False";
BA_ "VFrameFormat" BO_ 2499749481 1;
BA_ "GenMsgInstanced" BO_ 2499749481 "False";
BA_ "VFrameFormat" BO_ 2499749482 1;
BA_ "GenMsgInstanced" BO_ 2499749482 "False";
BA_ "VFrameFormat" BO_ 2499749483 1;
BA_ "GenMsgInstanced" BO_ 2499749483 "False";
BA_ "VFrameFormat" BO_ 2499749484 1;
BA_ "GenMsgInstanced" BO_ 2499749484 "False";
BA_ "VFrameFormat" BO_ 2499750245 1;
BA_ "GenMsgInstanced" BO_ 2499750245 "False";
BA_ "GenMsgDiag" BO_ 2499750245 1;
BA_ "VFrameFormat" BO_ 2499750246 1;
BA_ "GenMsgInstanced" BO_ 2499750246 "False";
BA_ "GenMsgDiag" BO_ 2499750246 1;
BA_ "VFrameFormat" BO_ 2499750247 1;
BA_ "GenMsgInstanced" BO_ 2499750247 "False";
BA_ "GenMsgDiag" BO_ 2499750247 1;
BA_ "VFrameFormat" BO_ 2499750248 1;
BA_ "GenMsgInstanced" BO_ 2499750248 "False";
BA_ "GenMsgDiag" BO_ 2499750248 1;
BA_ "VFrameFormat" BO_ 2499750249 1;
BA_ "GenMsgInstanced" BO_ 2499750249 "False";
BA_ "GenMsgDiag" BO_ 2499750249 1;
BA_ "SystemSignalLongSymbol" SG_ 2499745381 HVESP01_ModuleThermFaultMod_0007 "HVESP01_ModuleThermFaultModerate_1";
BA_ "SystemSignalLongSymbol" SG_ 2499745381 HVESP01_ModuleThermFaultWar_0007 "HVESP01_ModuleThermFaultWarning_1";
BA_ "SystemSignalLongSymbol" SG_ 2499745382 HVESP01_ModuleThermFaultMod_0008 "HVESP01_ModuleThermFaultModerate_2";
BA_ "SystemSignalLongSymbol" SG_ 2499745382 HVESP01_ModuleThermFaultWar_0008 "HVESP01_ModuleThermFaultWarning_2";
BA_ "SystemSignalLongSymbol" SG_ 2499745383 HVESP01_ModuleThermFaultMod_0009 "HVESP01_ModuleThermFaultModerate_3";
BA_ "SystemSignalLongSymbol" SG_ 2499745383 HVESP01_ModuleThermFaultWar_0009 "HVESP01_ModuleThermFaultWarning_3";
BA_ "SystemSignalLongSymbol" SG_ 2499745384 HVESP01_ModuleThermFaultMod_0010 "HVESP01_ModuleThermFaultModerate_4";
BA_ "SystemSignalLongSymbol" SG_ 2499745384 HVESP01_ModuleThermFaultWar_0010 "HVESP01_ModuleThermFaultWarning_4";
BA_ "SystemSignalLongSymbol" SG_ 2499745385 HVESP01_ModuleThermFaultMod_0011 "HVESP01_ModuleThermFaultModerate_5";
BA_ "SystemSignalLongSymbol" SG_ 2499745385 HVESP01_ModuleThermFaultWar_0011 "HVESP01_ModuleThermFaultWarning_5";
BA_ "SystemSignalLongSymbol" SG_ 2499745386 HVESP01_ModuleThermFaultMod_0012 "HVESP01_ModuleThermFaultModerate_6";
BA_ "SystemSignalLongSymbol" SG_ 2499745386 HVESP01_ModuleThermFaultWar_0012 "HVESP01_ModuleThermFaultWarning_6";
BA_ "SystemSignalLongSymbol" SG_ 2499745387 HVESP01_ModuleThermFaultMod_0013 "HVESP01_ModuleThermFaultModerate_7";
BA_ "SystemSignalLongSymbol" SG_ 2499745387 HVESP01_ModuleThermFaultWar_0013 "HVESP01_ModuleThermFaultWarning_7";
BA_ "SystemSignalLongSymbol" SG_ 2499745388 HVESP01_ModuleThermFaultMod_0014 "HVESP01_ModuleThermFaultModerate_8";
BA_ "SystemSignalLongSymbol" SG_ 2499745388 HVESP01_ModuleThermFaultWar_0014 "HVESP01_ModuleThermFaultWarning_8";
